VERSION ""

NS_ :

BS_:

BU_: FR C3B

BO_ 273 FR_111: 64 FR
 SG_ FR_CRCCheck_111 : 503|16@0+ (1,0) [0|65535] ""  C3B
 SG_ FR_RollingCounter_111 : 491|4@0+ (1,0) [0|15] ""  C3B
 SG_ FR_Obj1_Ax : 303|10@0+ (0.03125,-16) [-16|15.96875] "m/s2"  C3B
 SG_ FR_Obj1_Ay : 280|9@0+ (0.0625,-16) [-16|15.9375] "m/s2"  C3B
 SG_ FR_Obj1_Vx : 276|12@0+ (0.0625,-128) [-128|127.9375] "m/s"  C3B
 SG_ FR_Obj1_Vy : 270|10@0+ (0.0625,-32) [-32|31.9375] "m/s"  C3B
 SG_ FR_Obj1_DelayTime : 254|16@0+ (1,0) [0|65535] "ms"  C3B
 SG_ FR_Obj1_ReferPoint_Dx : 237|4@0+ (1,0) [0|15] "m"  C3B
 SG_ FR_Obj1_HeightGround : 223|9@0+ (0.1,0) [0|51.1] "m"  C3B
 SG_ FR_Obj1_MotionStatusConf : 213|6@0+ (2,0) [0|63] "-"  C3B
 SG_ FR_Obj1_MotionStatus : 200|3@0+ (1,0) [0|7] ""  C3B
 SG_ FR_Obj1_Measured : 202|2@0+ (1,0) [0|3] ""  C3B
 SG_ FR_Obj1_valid : 203|1@0+ (1,0) [0|1] ""  C3B
 SG_ FR_Obj1_Track_Age : 187|16@0+ (1,0) [0|65535] ""  C3B
 SG_ FR_Obj1_Track_ID : 171|16@0+ (1,0) [0|65535] ""  C3B
 SG_ FR_Obj1_ObstacleProb : 161|6@0+ (2,0) [0|100] "%"  C3B
 SG_ FR_Obj1_ExistProb : 167|6@0+ (2,0) [0|100] "%"  C3B
 SG_ FR_Obj1_RelAx : 145|10@0+ (0.03125,-16) [-16|15.96875] "m/s2"  C3B
 SG_ FR_Obj1_RelAy : 138|9@0+ (0.0625,-16) [-16|15.9375] "m/s2"  C3B
 SG_ FR_Obj1_RelVx_std : 134|12@0+ (0.0625,0) [0|255.9375] "m/s"  C3B
 SG_ FR_Obj1_RelVx : 114|12@0+ (0.0625,-128) [-128|127.9375] "m/s"  C3B
 SG_ FR_Obj1_RelVy_std : 108|10@0+ (0.125,0) [0|127.875] "m/s"  C3B
 SG_ FR_Obj1_RelVy : 102|10@0+ (0.0625,-32) [-32|31.9375] "m/s"  C3B
 SG_ FR_Obj1_Dx_Vnce : 84|14@0+ (0.05,0) [0|50] "m2"  C3B
 SG_ FR_Obj1_Dx : 65|13@0+ (0.0625,-100) [-100|411.9375] "m"  C3B
 SG_ FR_Obj1_Dy_Vnce : 59|10@0+ (0.02,0) [0|20] "m2"  C3B
 SG_ FR_Obj1_Dy : 54|11@0+ (0.125,-128) [-128|127.875] "m"  C3B
 SG_ FR_Obj1_HeadingAngle : 32|10@0+ (0.01,-3.14) [-3.14|3.14] "rad"  C3B
 SG_ FR_Obj1_Length : 25|9@0+ (0.05,0) [0|25.5] "m"  C3B
 SG_ FR_Obj1_Height : 18|9@0+ (0.01,0) [0|5.11] "m"  C3B
 SG_ FR_Obj1_Width : 12|10@0+ (0.01,0) [0|10.23] "m"  C3B
 SG_ FR_Obj1_TypeProb : 2|6@0+ (2,0) [0|100] "%"  C3B
 SG_ FR_Obj1_Type : 6|4@0+ (1,0) [0|15] ""  C3B

BO_ 274 FR_112: 64 FR
 SG_ FR_CRCCheck_112 : 503|16@0+ (1,0) [0|65535] ""  C3B
 SG_ FR_RollingCounter_112 : 491|4@0+ (1,0) [0|15] ""  C3B
 SG_ FR_Obj2_Ax : 303|10@0+ (0.03125,-16) [-16|15.96875] "m/s2"  C3B
 SG_ FR_Obj2_Ay : 280|9@0+ (0.0625,-16) [-16|15.9375] "m/s2"  C3B
 SG_ FR_Obj2_Vx : 276|12@0+ (0.0625,-128) [-128|127.9375] "m/s"  C3B
 SG_ FR_Obj2_Vy : 270|10@0+ (0.0625,-32) [-32|31.9375] "m/s"  C3B
 SG_ FR_Obj2_DelayTime : 254|16@0+ (1,0) [0|65535] "ms"  C3B
 SG_ FR_Obj2_ReferPoint_Dx : 237|4@0+ (1,0) [0|15] "m"  C3B
 SG_ FR_Obj2_HeightGround : 223|9@0+ (0.1,0) [0|51.1] "m"  C3B
 SG_ FR_Obj2_MotionStatusConf : 213|6@0+ (2,0) [0|63] "-"  C3B
 SG_ FR_Obj2_MotionStatus : 200|3@0+ (1,0) [0|7] ""  C3B
 SG_ FR_Obj2_Measured : 202|2@0+ (1,0) [0|3] ""  C3B
 SG_ FR_Obj2_valid : 203|1@0+ (1,0) [0|1] ""  C3B
 SG_ FR_Obj2_Track_Age : 187|16@0+ (1,0) [0|65535] ""  C3B
 SG_ FR_Obj2_Track_ID : 171|16@0+ (1,0) [0|65535] ""  C3B
 SG_ FR_Obj2_ObstacleProb : 161|6@0+ (2,0) [0|100] "%"  C3B
 SG_ FR_Obj2_ExistProb : 167|6@0+ (2,0) [0|100] "%"  C3B
 SG_ FR_Obj2_RelAx : 145|10@0+ (0.03125,-16) [-16|15.96875] "m/s2"  C3B
 SG_ FR_Obj2_RelAy : 138|9@0+ (0.0625,-16) [-16|15.9375] "m/s2"  C3B
 SG_ FR_Obj2_RelVx_std : 134|12@0+ (0.0625,0) [0|255.9375] "m/s"  C3B
 SG_ FR_Obj2_RelVx : 114|12@0+ (0.0625,-128) [-128|127.9375] "m/s"  C3B
 SG_ FR_Obj2_RelVy_std : 108|10@0+ (0.125,0) [0|127.875] "m/s"  C3B
 SG_ FR_Obj2_RelVy : 102|10@0+ (0.0625,-32) [-32|31.9375] "m/s"  C3B
 SG_ FR_Obj2_Dx_Vnce : 84|14@0+ (0.05,0) [0|50] "m2"  C3B
 SG_ FR_Obj2_Dx : 65|13@0+ (0.0625,-100) [-100|411.9375] "m"  C3B
 SG_ FR_Obj2_Dy_Vnce : 59|10@0+ (0.02,0) [0|20] "m2"  C3B
 SG_ FR_Obj2_Dy : 54|11@0+ (0.125,-128) [-128|127.875] "m"  C3B
 SG_ FR_Obj2_HeadingAngle : 32|10@0+ (0.01,-3.14) [-3.14|3.14] "rad"  C3B
 SG_ FR_Obj2_Length : 25|9@0+ (0.05,0) [0|25.5] "m"  C3B
 SG_ FR_Obj2_Height : 18|9@0+ (0.01,0) [0|5.11] "m"  C3B
 SG_ FR_Obj2_Width : 12|10@0+ (0.01,0) [0|10.23] "m"  C3B
 SG_ FR_Obj2_TypeProb : 2|6@0+ (2,0) [0|100] "%"  C3B
 SG_ FR_Obj2_Type : 6|4@0+ (1,0) [0|15] ""  C3B

BO_ 275 FR_113: 64 FR
 SG_ FR_CRCCheck_113 : 503|16@0+ (1,0) [0|65535] ""  C3B
 SG_ FR_RollingCounter_113 : 491|4@0+ (1,0) [0|15] ""  C3B
 SG_ FR_Obj3_Ax : 303|10@0+ (0.03125,-16) [-16|15.96875] "m/s2"  C3B
 SG_ FR_Obj3_Ay : 280|9@0+ (0.0625,-16) [-16|15.9375] "m/s2"  C3B
 SG_ FR_Obj3_Vx : 276|12@0+ (0.0625,-128) [-128|127.9375] "m/s"  C3B
 SG_ FR_Obj3_Vy : 270|10@0+ (0.0625,-32) [-32|31.9375] "m/s"  C3B
 SG_ FR_Obj3_DelayTime : 254|16@0+ (1,0) [0|65535] "ms"  C3B
 SG_ FR_Obj3_ReferPoint_Dx : 237|4@0+ (1,0) [0|15] "m"  C3B
 SG_ FR_Obj3_HeightGround : 223|9@0+ (0.1,0) [0|51.1] "m"  C3B
 SG_ FR_Obj3_MotionStatusConf : 213|6@0+ (2,0) [0|63] "-"  C3B
 SG_ FR_Obj3_MotionStatus : 200|3@0+ (1,0) [0|7] ""  C3B
 SG_ FR_Obj3_Measured : 202|2@0+ (1,0) [0|3] ""  C3B
 SG_ FR_Obj3_valid : 203|1@0+ (1,0) [0|1] ""  C3B
 SG_ FR_Obj3_Track_Age : 187|16@0+ (1,0) [0|65535] ""  C3B
 SG_ FR_Obj3_Track_ID : 171|16@0+ (1,0) [0|65535] ""  C3B
 SG_ FR_Obj3_ObstacleProb : 161|6@0+ (2,0) [0|100] "%"  C3B
 SG_ FR_Obj3_ExistProb : 167|6@0+ (2,0) [0|100] "%"  C3B
 SG_ FR_Obj3_RelAx : 145|10@0+ (0.03125,-16) [-16|15.96875] "m/s2"  C3B
 SG_ FR_Obj3_RelAy : 138|9@0+ (0.0625,-16) [-16|15.9375] "m/s2"  C3B
 SG_ FR_Obj3_RelVx_std : 134|12@0+ (0.0625,0) [0|255.9375] "m/s"  C3B
 SG_ FR_Obj3_RelVx : 114|12@0+ (0.0625,-128) [-128|127.9375] "m/s"  C3B
 SG_ FR_Obj3_RelVy_std : 108|10@0+ (0.125,0) [0|127.875] "m/s"  C3B
 SG_ FR_Obj3_RelVy : 102|10@0+ (0.0625,-32) [-32|31.9375] "m/s"  C3B
 SG_ FR_Obj3_Dx_Vnce : 84|14@0+ (0.05,0) [0|50] "m2"  C3B
 SG_ FR_Obj3_Dx : 65|13@0+ (0.0625,-100) [-100|411.9375] "m"  C3B
 SG_ FR_Obj3_Dy_Vnce : 59|10@0+ (0.02,0) [0|20] "m2"  C3B
 SG_ FR_Obj3_Dy : 54|11@0+ (0.125,-128) [-128|127.875] "m"  C3B
 SG_ FR_Obj3_HeadingAngle : 32|10@0+ (0.01,-3.14) [-3.14|3.14] "rad"  C3B
 SG_ FR_Obj3_Length : 25|9@0+ (0.05,0) [0|25.5] "m"  C3B
 SG_ FR_Obj3_Height : 18|9@0+ (0.01,0) [0|5.11] "m"  C3B
 SG_ FR_Obj3_Width : 12|10@0+ (0.01,0) [0|10.23] "m"  C3B
 SG_ FR_Obj3_TypeProb : 2|6@0+ (2,0) [0|100] "%"  C3B
 SG_ FR_Obj3_Type : 6|4@0+ (1,0) [0|15] ""  C3B

BO_ 276 FR_114: 64 FR
 SG_ FR_CRCCheck_114 : 503|16@0+ (1,0) [0|65535] ""  C3B
 SG_ FR_RollingCounter_114 : 491|4@0+ (1,0) [0|15] ""  C3B
 SG_ FR_Obj4_Ax : 303|10@0+ (0.03125,-16) [-16|15.96875] "m/s2"  C3B
 SG_ FR_Obj4_Ay : 280|9@0+ (0.0625,-16) [-16|15.9375] "m/s2"  C3B
 SG_ FR_Obj4_Vx : 276|12@0+ (0.0625,-128) [-128|127.9375] "m/s"  C3B
 SG_ FR_Obj4_Vy : 270|10@0+ (0.0625,-32) [-32|31.9375] "m/s"  C3B
 SG_ FR_Obj4_DelayTime : 254|16@0+ (1,0) [0|65535] "ms"  C3B
 SG_ FR_Obj4_ReferPoint_Dx : 237|4@0+ (1,0) [0|15] "m"  C3B
 SG_ FR_Obj4_HeightGround : 223|9@0+ (0.1,0) [0|51.1] "m"  C3B
 SG_ FR_Obj4_MotionStatusConf : 213|6@0+ (2,0) [0|63] "-"  C3B
 SG_ FR_Obj4_MotionStatus : 200|3@0+ (1,0) [0|7] ""  C3B
 SG_ FR_Obj4_Measured : 202|2@0+ (1,0) [0|3] ""  C3B
 SG_ FR_Obj4_valid : 203|1@0+ (1,0) [0|1] ""  C3B
 SG_ FR_Obj4_Track_Age : 187|16@0+ (1,0) [0|65535] ""  C3B
 SG_ FR_Obj4_Track_ID : 171|16@0+ (1,0) [0|65535] ""  C3B
 SG_ FR_Obj4_ObstacleProb : 161|6@0+ (2,0) [0|100] "%"  C3B
 SG_ FR_Obj4_ExistProb : 167|6@0+ (2,0) [0|100] "%"  C3B
 SG_ FR_Obj4_RelAx : 145|10@0+ (0.03125,-16) [-16|15.96875] "m/s2"  C3B
 SG_ FR_Obj4_RelAy : 138|9@0+ (0.0625,-16) [-16|15.9375] "m/s2"  C3B
 SG_ FR_Obj4_RelVx_std : 134|12@0+ (0.0625,0) [0|255.9375] "m/s"  C3B
 SG_ FR_Obj4_RelVx : 114|12@0+ (0.0625,-128) [-128|127.9375] "m/s"  C3B
 SG_ FR_Obj4_RelVy_std : 108|10@0+ (0.125,0) [0|127.875] "m/s"  C3B
 SG_ FR_Obj4_RelVy : 102|10@0+ (0.0625,-32) [-32|31.9375] "m/s"  C3B
 SG_ FR_Obj4_Dx_Vnce : 84|14@0+ (0.05,0) [0|50] "m2"  C3B
 SG_ FR_Obj4_Dx : 65|13@0+ (0.0625,-100) [-100|411.9375] "m"  C3B
 SG_ FR_Obj4_Dy_Vnce : 59|10@0+ (0.02,0) [0|20] "m2"  C3B
 SG_ FR_Obj4_Dy : 54|11@0+ (0.125,-128) [-128|127.875] "m"  C3B
 SG_ FR_Obj4_HeadingAngle : 32|10@0+ (0.01,-3.14) [-3.14|3.14] "rad"  C3B
 SG_ FR_Obj4_Length : 25|9@0+ (0.05,0) [0|25.5] "m"  C3B
 SG_ FR_Obj4_Height : 18|9@0+ (0.01,0) [0|5.11] "m"  C3B
 SG_ FR_Obj4_Width : 12|10@0+ (0.01,0) [0|10.23] "m"  C3B
 SG_ FR_Obj4_TypeProb : 2|6@0+ (2,0) [0|100] "%"  C3B
 SG_ FR_Obj4_Type : 6|4@0+ (1,0) [0|15] ""  C3B

BO_ 277 FR_115: 64 FR
 SG_ FR_CRCCheck_115 : 503|16@0+ (1,0) [0|65535] ""  C3B
 SG_ FR_RollingCounter_115 : 491|4@0+ (1,0) [0|15] ""  C3B
 SG_ FR_Obj5_Ax : 303|10@0+ (0.03125,-16) [-16|15.96875] "m/s2"  C3B
 SG_ FR_Obj5_Ay : 280|9@0+ (0.0625,-16) [-16|15.9375] "m/s2"  C3B
 SG_ FR_Obj5_Vx : 276|12@0+ (0.0625,-128) [-128|127.9375] "m/s"  C3B
 SG_ FR_Obj5_Vy : 270|10@0+ (0.0625,-32) [-32|31.9375] "m/s"  C3B
 SG_ FR_Obj5_DelayTime : 254|16@0+ (1,0) [0|65535] "ms"  C3B
 SG_ FR_Obj5_ReferPoint_Dx : 237|4@0+ (1,0) [0|15] "m"  C3B
 SG_ FR_Obj5_HeightGround : 223|9@0+ (0.1,0) [0|51.1] "m"  C3B
 SG_ FR_Obj5_MotionStatusConf : 213|6@0+ (2,0) [0|63] "-"  C3B
 SG_ FR_Obj5_MotionStatus : 200|3@0+ (1,0) [0|7] ""  C3B
 SG_ FR_Obj5_Measured : 202|2@0+ (1,0) [0|3] ""  C3B
 SG_ FR_Obj5_valid : 203|1@0+ (1,0) [0|1] ""  C3B
 SG_ FR_Obj5_Track_Age : 187|16@0+ (1,0) [0|65535] ""  C3B
 SG_ FR_Obj5_Track_ID : 171|16@0+ (1,0) [0|65535] ""  C3B
 SG_ FR_Obj5_ObstacleProb : 161|6@0+ (2,0) [0|100] "%"  C3B
 SG_ FR_Obj5_ExistProb : 167|6@0+ (2,0) [0|100] "%"  C3B
 SG_ FR_Obj5_RelAx : 145|10@0+ (0.03125,-16) [-16|15.96875] "m/s2"  C3B
 SG_ FR_Obj5_RelAy : 138|9@0+ (0.0625,-16) [-16|15.9375] "m/s2"  C3B
 SG_ FR_Obj5_RelVx_std : 134|12@0+ (0.0625,0) [0|255.9375] "m/s"  C3B
 SG_ FR_Obj5_RelVx : 114|12@0+ (0.0625,-128) [-128|127.9375] "m/s"  C3B
 SG_ FR_Obj5_RelVy_std : 108|10@0+ (0.125,0) [0|127.875] "m/s"  C3B
 SG_ FR_Obj5_RelVy : 102|10@0+ (0.0625,-32) [-32|31.9375] "m/s"  C3B
 SG_ FR_Obj5_Dx_Vnce : 84|14@0+ (0.05,0) [0|50] "m2"  C3B
 SG_ FR_Obj5_Dx : 65|13@0+ (0.0625,-100) [-100|411.9375] "m"  C3B
 SG_ FR_Obj5_Dy_Vnce : 59|10@0+ (0.02,0) [0|20] "m2"  C3B
 SG_ FR_Obj5_Dy : 54|11@0+ (0.125,-128) [-128|127.875] "m"  C3B
 SG_ FR_Obj5_HeadingAngle : 32|10@0+ (0.01,-3.14) [-3.14|3.14] "rad"  C3B
 SG_ FR_Obj5_Length : 25|9@0+ (0.05,0) [0|25.5] "m"  C3B
 SG_ FR_Obj5_Height : 18|9@0+ (0.01,0) [0|5.11] "m"  C3B
 SG_ FR_Obj5_Width : 12|10@0+ (0.01,0) [0|10.23] "m"  C3B
 SG_ FR_Obj5_TypeProb : 2|6@0+ (2,0) [0|100] "%"  C3B
 SG_ FR_Obj5_Type : 6|4@0+ (1,0) [0|15] ""  C3B

BO_ 278 FR_116: 64 FR
 SG_ FR_CRCCheck_116 : 503|16@0+ (1,0) [0|65535] ""  C3B
 SG_ FR_RollingCounter_116 : 491|4@0+ (1,0) [0|15] ""  C3B
 SG_ FR_Obj6_Ax : 303|10@0+ (0.03125,-16) [-16|15.96875] "m/s2"  C3B
 SG_ FR_Obj6_Ay : 280|9@0+ (0.0625,-16) [-16|15.9375] "m/s2"  C3B
 SG_ FR_Obj6_Vx : 276|12@0+ (0.0625,-128) [-128|127.9375] "m/s"  C3B
 SG_ FR_Obj6_Vy : 270|10@0+ (0.0625,-32) [-32|31.9375] "m/s"  C3B
 SG_ FR_Obj6_DelayTime : 254|16@0+ (1,0) [0|65535] "ms"  C3B
 SG_ FR_Obj6_ReferPoint_Dx : 237|4@0+ (1,0) [0|15] "m"  C3B
 SG_ FR_Obj6_HeightGround : 223|9@0+ (0.1,0) [0|51.1] "m"  C3B
 SG_ FR_Obj6_MotionStatusConf : 213|6@0+ (2,0) [0|63] "-"  C3B
 SG_ FR_Obj6_MotionStatus : 200|3@0+ (1,0) [0|7] ""  C3B
 SG_ FR_Obj6_Measured : 202|2@0+ (1,0) [0|3] ""  C3B
 SG_ FR_Obj6_valid : 203|1@0+ (1,0) [0|1] ""  C3B
 SG_ FR_Obj6_Track_Age : 187|16@0+ (1,0) [0|65535] ""  C3B
 SG_ FR_Obj6_Track_ID : 171|16@0+ (1,0) [0|65535] ""  C3B
 SG_ FR_Obj6_ObstacleProb : 161|6@0+ (2,0) [0|100] "%"  C3B
 SG_ FR_Obj6_ExistProb : 167|6@0+ (2,0) [0|100] "%"  C3B
 SG_ FR_Obj6_RelAx : 145|10@0+ (0.03125,-16) [-16|15.96875] "m/s2"  C3B
 SG_ FR_Obj6_RelAy : 138|9@0+ (0.0625,-16) [-16|15.9375] "m/s2"  C3B
 SG_ FR_Obj6_RelVx_std : 134|12@0+ (0.0625,0) [0|255.9375] "m/s"  C3B
 SG_ FR_Obj6_RelVx : 114|12@0+ (0.0625,-128) [-128|127.9375] "m/s"  C3B
 SG_ FR_Obj6_RelVy_std : 108|10@0+ (0.125,0) [0|127.875] "m/s"  C3B
 SG_ FR_Obj6_RelVy : 102|10@0+ (0.0625,-32) [-32|31.9375] "m/s"  C3B
 SG_ FR_Obj6_Dx_Vnce : 84|14@0+ (0.05,0) [0|50] "m2"  C3B
 SG_ FR_Obj6_Dx : 65|13@0+ (0.0625,-100) [-100|411.9375] "m"  C3B
 SG_ FR_Obj6_Dy_Vnce : 59|10@0+ (0.02,0) [0|20] "m2"  C3B
 SG_ FR_Obj6_Dy : 54|11@0+ (0.125,-128) [-128|127.875] "m"  C3B
 SG_ FR_Obj6_HeadingAngle : 32|10@0+ (0.01,-3.14) [-3.14|3.14] "rad"  C3B
 SG_ FR_Obj6_Length : 25|9@0+ (0.05,0) [0|25.5] "m"  C3B
 SG_ FR_Obj6_Height : 18|9@0+ (0.01,0) [0|5.11] "m"  C3B
 SG_ FR_Obj6_Width : 12|10@0+ (0.01,0) [0|10.23] "m"  C3B
 SG_ FR_Obj6_TypeProb : 2|6@0+ (2,0) [0|100] "%"  C3B
 SG_ FR_Obj6_Type : 6|4@0+ (1,0) [0|15] ""  C3B

BO_ 279 FR_117: 64 FR
 SG_ FR_CRCCheck_117 : 503|16@0+ (1,0) [0|65535] ""  C3B
 SG_ FR_RollingCounter_117 : 491|4@0+ (1,0) [0|15] ""  C3B
 SG_ FR_Obj7_Ax : 303|10@0+ (0.03125,-16) [-16|15.96875] "m/s2"  C3B
 SG_ FR_Obj7_Ay : 280|9@0+ (0.0625,-16) [-16|15.9375] "m/s2"  C3B
 SG_ FR_Obj7_Vx : 276|12@0+ (0.0625,-128) [-128|127.9375] "m/s"  C3B
 SG_ FR_Obj7_Vy : 270|10@0+ (0.0625,-32) [-32|31.9375] "m/s"  C3B
 SG_ FR_Obj7_DelayTime : 254|16@0+ (1,0) [0|65535] "ms"  C3B
 SG_ FR_Obj7_ReferPoint_Dx : 237|4@0+ (1,0) [0|15] "m"  C3B
 SG_ FR_Obj7_HeightGround : 223|9@0+ (0.1,0) [0|51.1] "m"  C3B
 SG_ FR_Obj7_MotionStatusConf : 213|6@0+ (2,0) [0|63] "-"  C3B
 SG_ FR_Obj7_MotionStatus : 200|3@0+ (1,0) [0|7] ""  C3B
 SG_ FR_Obj7_Measured : 202|2@0+ (1,0) [0|3] ""  C3B
 SG_ FR_Obj7_valid : 203|1@0+ (1,0) [0|1] ""  C3B
 SG_ FR_Obj7_Track_Age : 187|16@0+ (1,0) [0|65535] ""  C3B
 SG_ FR_Obj7_Track_ID : 171|16@0+ (1,0) [0|65535] ""  C3B
 SG_ FR_Obj7_ObstacleProb : 161|6@0+ (2,0) [0|100] "%"  C3B
 SG_ FR_Obj7_ExistProb : 167|6@0+ (2,0) [0|100] "%"  C3B
 SG_ FR_Obj7_RelAx : 145|10@0+ (0.03125,-16) [-16|15.96875] "m/s2"  C3B
 SG_ FR_Obj7_RelAy : 138|9@0+ (0.0625,-16) [-16|15.9375] "m/s2"  C3B
 SG_ FR_Obj7_RelVx_std : 134|12@0+ (0.0625,0) [0|255.9375] "m/s"  C3B
 SG_ FR_Obj7_RelVx : 114|12@0+ (0.0625,-128) [-128|127.9375] "m/s"  C3B
 SG_ FR_Obj7_RelVy_std : 108|10@0+ (0.125,0) [0|127.875] "m/s"  C3B
 SG_ FR_Obj7_RelVy : 102|10@0+ (0.0625,-32) [-32|31.9375] "m/s"  C3B
 SG_ FR_Obj7_Dx_Vnce : 84|14@0+ (0.05,0) [0|50] "m2"  C3B
 SG_ FR_Obj7_Dx : 65|13@0+ (0.0625,-100) [-100|411.9375] "m"  C3B
 SG_ FR_Obj7_Dy_Vnce : 59|10@0+ (0.02,0) [0|20] "m2"  C3B
 SG_ FR_Obj7_Dy : 54|11@0+ (0.125,-128) [-128|127.875] "m"  C3B
 SG_ FR_Obj7_HeadingAngle : 32|10@0+ (0.01,-3.14) [-3.14|3.14] "rad"  C3B
 SG_ FR_Obj7_Length : 25|9@0+ (0.05,0) [0|25.5] "m"  C3B
 SG_ FR_Obj7_Height : 18|9@0+ (0.01,0) [0|5.11] "m"  C3B
 SG_ FR_Obj7_Width : 12|10@0+ (0.01,0) [0|10.23] "m"  C3B
 SG_ FR_Obj7_TypeProb : 2|6@0+ (2,0) [0|100] "%"  C3B
 SG_ FR_Obj7_Type : 6|4@0+ (1,0) [0|15] ""  C3B

BO_ 280 FR_118: 64 FR
 SG_ FR_CRCCheck_118 : 503|16@0+ (1,0) [0|65535] ""  C3B
 SG_ FR_RollingCounter_118 : 491|4@0+ (1,0) [0|15] ""  C3B
 SG_ FR_Obj8_Ax : 303|10@0+ (0.03125,-16) [-16|15.96875] "m/s2"  C3B
 SG_ FR_Obj8_Ay : 280|9@0+ (0.0625,-16) [-16|15.9375] "m/s2"  C3B
 SG_ FR_Obj8_Vx : 276|12@0+ (0.0625,-128) [-128|127.9375] "m/s"  C3B
 SG_ FR_Obj8_Vy : 270|10@0+ (0.0625,-32) [-32|31.9375] "m/s"  C3B
 SG_ FR_Obj8_DelayTime : 254|16@0+ (1,0) [0|65535] "ms"  C3B
 SG_ FR_Obj8_ReferPoint_Dx : 237|4@0+ (1,0) [0|15] "m"  C3B
 SG_ FR_Obj8_HeightGround : 223|9@0+ (0.1,0) [0|51.1] "m"  C3B
 SG_ FR_Obj8_MotionStatusConf : 213|6@0+ (2,0) [0|63] "-"  C3B
 SG_ FR_Obj8_MotionStatus : 200|3@0+ (1,0) [0|7] ""  C3B
 SG_ FR_Obj8_Measured : 202|2@0+ (1,0) [0|3] ""  C3B
 SG_ FR_Obj8_valid : 203|1@0+ (1,0) [0|1] ""  C3B
 SG_ FR_Obj8_Track_Age : 187|16@0+ (1,0) [0|65535] ""  C3B
 SG_ FR_Obj8_Track_ID : 171|16@0+ (1,0) [0|65535] ""  C3B
 SG_ FR_Obj8_ObstacleProb : 161|6@0+ (2,0) [0|100] "%"  C3B
 SG_ FR_Obj8_ExistProb : 167|6@0+ (2,0) [0|100] "%"  C3B
 SG_ FR_Obj8_RelAx : 145|10@0+ (0.03125,-16) [-16|15.96875] "m/s2"  C3B
 SG_ FR_Obj8_RelAy : 138|9@0+ (0.0625,-16) [-16|15.9375] "m/s2"  C3B
 SG_ FR_Obj8_RelVx_std : 134|12@0+ (0.0625,0) [0|255.9375] "m/s"  C3B
 SG_ FR_Obj8_RelVx : 114|12@0+ (0.0625,-128) [-128|127.9375] "m/s"  C3B
 SG_ FR_Obj8_RelVy_std : 108|10@0+ (0.125,0) [0|127.875] "m/s"  C3B
 SG_ FR_Obj8_RelVy : 102|10@0+ (0.0625,-32) [-32|31.9375] "m/s"  C3B
 SG_ FR_Obj8_Dx_Vnce : 84|14@0+ (0.05,0) [0|50] "m2"  C3B
 SG_ FR_Obj8_Dx : 65|13@0+ (0.0625,-100) [-100|411.9375] "m"  C3B
 SG_ FR_Obj8_Dy_Vnce : 59|10@0+ (0.02,0) [0|20] "m2"  C3B
 SG_ FR_Obj8_Dy : 54|11@0+ (0.125,-128) [-128|127.875] "m"  C3B
 SG_ FR_Obj8_HeadingAngle : 32|10@0+ (0.01,-3.14) [-3.14|3.14] "rad"  C3B
 SG_ FR_Obj8_Length : 25|9@0+ (0.05,0) [0|25.5] "m"  C3B
 SG_ FR_Obj8_Height : 18|9@0+ (0.01,0) [0|5.11] "m"  C3B
 SG_ FR_Obj8_Width : 12|10@0+ (0.01,0) [0|10.23] "m"  C3B
 SG_ FR_Obj8_TypeProb : 2|6@0+ (2,0) [0|100] "%"  C3B
 SG_ FR_Obj8_Type : 6|4@0+ (1,0) [0|15] ""  C3B

BO_ 281 FR_119: 64 FR
 SG_ FR_CRCCheck_119 : 503|16@0+ (1,0) [0|65535] ""  C3B
 SG_ FR_RollingCounter_119 : 491|4@0+ (1,0) [0|15] ""  C3B
 SG_ FR_Obj9_Ax : 303|10@0+ (0.03125,-16) [-16|15.96875] "m/s2"  C3B
 SG_ FR_Obj9_Ay : 280|9@0+ (0.0625,-16) [-16|15.9375] "m/s2"  C3B
 SG_ FR_Obj9_Vx : 276|12@0+ (0.0625,-128) [-128|127.9375] "m/s"  C3B
 SG_ FR_Obj9_Vy : 270|10@0+ (0.0625,-32) [-32|31.9375] "m/s"  C3B
 SG_ FR_Obj9_DelayTime : 254|16@0+ (1,0) [0|65535] "ms"  C3B
 SG_ FR_Obj9_ReferPoint_Dx : 237|4@0+ (1,0) [0|15] "m"  C3B
 SG_ FR_Obj9_HeightGround : 223|9@0+ (0.1,0) [0|51.1] "m"  C3B
 SG_ FR_Obj9_MotionStatusConf : 213|6@0+ (2,0) [0|63] "-"  C3B
 SG_ FR_Obj9_MotionStatus : 200|3@0+ (1,0) [0|7] ""  C3B
 SG_ FR_Obj9_Measured : 202|2@0+ (1,0) [0|3] ""  C3B
 SG_ FR_Obj9_valid : 203|1@0+ (1,0) [0|1] ""  C3B
 SG_ FR_Obj9_Track_Age : 187|16@0+ (1,0) [0|65535] ""  C3B
 SG_ FR_Obj9_Track_ID : 171|16@0+ (1,0) [0|65535] ""  C3B
 SG_ FR_Obj9_ObstacleProb : 161|6@0+ (2,0) [0|100] "%"  C3B
 SG_ FR_Obj9_ExistProb : 167|6@0+ (2,0) [0|100] "%"  C3B
 SG_ FR_Obj9_RelAx : 145|10@0+ (0.03125,-16) [-16|15.96875] "m/s2"  C3B
 SG_ FR_Obj9_RelAy : 138|9@0+ (0.0625,-16) [-16|15.9375] "m/s2"  C3B
 SG_ FR_Obj9_RelVx_std : 134|12@0+ (0.0625,0) [0|255.9375] "m/s"  C3B
 SG_ FR_Obj9_RelVx : 114|12@0+ (0.0625,-128) [-128|127.9375] "m/s"  C3B
 SG_ FR_Obj9_RelVy_std : 108|10@0+ (0.125,0) [0|127.875] "m/s"  C3B
 SG_ FR_Obj9_RelVy : 102|10@0+ (0.0625,-32) [-32|31.9375] "m/s"  C3B
 SG_ FR_Obj9_Dx_Vnce : 84|14@0+ (0.05,0) [0|50] "m2"  C3B
 SG_ FR_Obj9_Dx : 65|13@0+ (0.0625,-100) [-100|411.9375] "m"  C3B
 SG_ FR_Obj9_Dy_Vnce : 59|10@0+ (0.02,0) [0|20] "m2"  C3B
 SG_ FR_Obj9_Dy : 54|11@0+ (0.125,-128) [-128|127.875] "m"  C3B
 SG_ FR_Obj9_HeadingAngle : 32|10@0+ (0.01,-3.14) [-3.14|3.14] "rad"  C3B
 SG_ FR_Obj9_Length : 25|9@0+ (0.05,0) [0|25.5] "m"  C3B
 SG_ FR_Obj9_Height : 18|9@0+ (0.01,0) [0|5.11] "m"  C3B
 SG_ FR_Obj9_Width : 12|10@0+ (0.01,0) [0|10.23] "m"  C3B
 SG_ FR_Obj9_TypeProb : 2|6@0+ (2,0) [0|100] "%"  C3B
 SG_ FR_Obj9_Type : 6|4@0+ (1,0) [0|15] ""  C3B

BO_ 288 FR_120: 64 FR
 SG_ FR_CRCCheck_120 : 503|16@0+ (1,0) [0|65535] ""  C3B
 SG_ FR_RollingCounter_120 : 491|4@0+ (1,0) [0|15] ""  C3B
 SG_ FR_Obj10_Ax : 303|10@0+ (0.03125,-16) [-16|15.96875] "m/s2"  C3B
 SG_ FR_Obj10_Ay : 280|9@0+ (0.0625,-16) [-16|15.9375] "m/s2"  C3B
 SG_ FR_Obj10_Vx : 276|12@0+ (0.0625,-128) [-128|127.9375] "m/s"  C3B
 SG_ FR_Obj10_Vy : 270|10@0+ (0.0625,-32) [-32|31.9375] "m/s"  C3B
 SG_ FR_Obj10_DelayTime : 254|16@0+ (1,0) [0|65535] "ms"  C3B
 SG_ FR_Obj10_ReferPoint_Dx : 237|4@0+ (1,0) [0|15] "m"  C3B
 SG_ FR_Obj10_HeightGround : 223|9@0+ (0.1,0) [0|51.1] "m"  C3B
 SG_ FR_Obj10_MotionStatusConf : 213|6@0+ (2,0) [0|63] "-"  C3B
 SG_ FR_Obj10_MotionStatus : 200|3@0+ (1,0) [0|7] ""  C3B
 SG_ FR_Obj10_Measured : 202|2@0+ (1,0) [0|3] ""  C3B
 SG_ FR_Obj10_valid : 203|1@0+ (1,0) [0|1] ""  C3B
 SG_ FR_Obj10_Track_Age : 187|16@0+ (1,0) [0|65535] ""  C3B
 SG_ FR_Obj10_Track_ID : 171|16@0+ (1,0) [0|65535] ""  C3B
 SG_ FR_Obj10_ObstacleProb : 161|6@0+ (2,0) [0|100] "%"  C3B
 SG_ FR_Obj10_ExistProb : 167|6@0+ (2,0) [0|100] "%"  C3B
 SG_ FR_Obj10_RelAx : 145|10@0+ (0.03125,-16) [-16|15.96875] "m/s2"  C3B
 SG_ FR_Obj10_RelAy : 138|9@0+ (0.0625,-16) [-16|15.9375] "m/s2"  C3B
 SG_ FR_Obj10_RelVx_std : 134|12@0+ (0.0625,0) [0|255.9375] "m/s"  C3B
 SG_ FR_Obj10_RelVx : 114|12@0+ (0.0625,-128) [-128|127.9375] "m/s"  C3B
 SG_ FR_Obj10_RelVy_std : 108|10@0+ (0.125,0) [0|127.875] "m/s"  C3B
 SG_ FR_Obj10_RelVy : 102|10@0+ (0.0625,-32) [-32|31.9375] "m/s"  C3B
 SG_ FR_Obj10_Dx_Vnce : 84|14@0+ (0.05,0) [0|50] "m2"  C3B
 SG_ FR_Obj10_Dx : 65|13@0+ (0.0625,-100) [-100|411.9375] "m"  C3B
 SG_ FR_Obj10_Dy_Vnce : 59|10@0+ (0.02,0) [0|20] "m2"  C3B
 SG_ FR_Obj10_Dy : 54|11@0+ (0.125,-128) [-128|127.875] "m"  C3B
 SG_ FR_Obj10_HeadingAngle : 32|10@0+ (0.01,-3.14) [-3.14|3.14] "rad"  C3B
 SG_ FR_Obj10_Length : 25|9@0+ (0.05,0) [0|25.5] "m"  C3B
 SG_ FR_Obj10_Height : 18|9@0+ (0.01,0) [0|5.11] "m"  C3B
 SG_ FR_Obj10_Width : 12|10@0+ (0.01,0) [0|10.23] "m"  C3B
 SG_ FR_Obj10_TypeProb : 2|6@0+ (2,0) [0|100] "%"  C3B
 SG_ FR_Obj10_Type : 6|4@0+ (1,0) [0|15] ""  C3B

BO_ 289 FR_121: 64 FR
 SG_ FR_CRCCheck_121 : 503|16@0+ (1,0) [0|65535] ""  C3B
 SG_ FR_RollingCounter_121 : 491|4@0+ (1,0) [0|15] ""  C3B
 SG_ FR_Obj11_Ax : 303|10@0+ (0.03125,-16) [-16|15.96875] "m/s2"  C3B
 SG_ FR_Obj11_Ay : 280|9@0+ (0.0625,-16) [-16|15.9375] "m/s2"  C3B
 SG_ FR_Obj11_Vx : 276|12@0+ (0.0625,-128) [-128|127.9375] "m/s"  C3B
 SG_ FR_Obj11_Vy : 270|10@0+ (0.0625,-32) [-32|31.9375] "m/s"  C3B
 SG_ FR_Obj11_DelayTime : 254|16@0+ (1,0) [0|65535] "ms"  C3B
 SG_ FR_Obj11_ReferPoint_Dx : 237|4@0+ (1,0) [0|15] "m"  C3B
 SG_ FR_Obj11_HeightGround : 223|9@0+ (0.1,0) [0|51.1] "m"  C3B
 SG_ FR_Obj11_MotionStatusConf : 213|6@0+ (2,0) [0|63] "-"  C3B
 SG_ FR_Obj11_MotionStatus : 200|3@0+ (1,0) [0|7] ""  C3B
 SG_ FR_Obj11_Measured : 202|2@0+ (1,0) [0|3] ""  C3B
 SG_ FR_Obj11_valid : 203|1@0+ (1,0) [0|1] ""  C3B
 SG_ FR_Obj11_Track_Age : 187|16@0+ (1,0) [0|65535] ""  C3B
 SG_ FR_Obj11_Track_ID : 171|16@0+ (1,0) [0|65535] ""  C3B
 SG_ FR_Obj11_ObstacleProb : 161|6@0+ (2,0) [0|100] "%"  C3B
 SG_ FR_Obj11_ExistProb : 167|6@0+ (2,0) [0|100] "%"  C3B
 SG_ FR_Obj11_RelAx : 145|10@0+ (0.03125,-16) [-16|15.96875] "m/s2"  C3B
 SG_ FR_Obj11_RelAy : 138|9@0+ (0.0625,-16) [-16|15.9375] "m/s2"  C3B
 SG_ FR_Obj11_RelVx_std : 134|12@0+ (0.0625,0) [0|255.9375] "m/s"  C3B
 SG_ FR_Obj11_RelVx : 114|12@0+ (0.0625,-128) [-128|127.9375] "m/s"  C3B
 SG_ FR_Obj11_RelVy_std : 108|10@0+ (0.125,0) [0|127.875] "m/s"  C3B
 SG_ FR_Obj11_RelVy : 102|10@0+ (0.0625,-32) [-32|31.9375] "m/s"  C3B
 SG_ FR_Obj11_Dx_Vnce : 84|14@0+ (0.05,0) [0|50] "m2"  C3B
 SG_ FR_Obj11_Dx : 65|13@0+ (0.0625,-100) [-100|411.9375] "m"  C3B
 SG_ FR_Obj11_Dy_Vnce : 59|10@0+ (0.02,0) [0|20] "m2"  C3B
 SG_ FR_Obj11_Dy : 54|11@0+ (0.125,-128) [-128|127.875] "m"  C3B
 SG_ FR_Obj11_HeadingAngle : 32|10@0+ (0.01,-3.14) [-3.14|3.14] "rad"  C3B
 SG_ FR_Obj11_Length : 25|9@0+ (0.05,0) [0|25.5] "m"  C3B
 SG_ FR_Obj11_Height : 18|9@0+ (0.01,0) [0|5.11] "m"  C3B
 SG_ FR_Obj11_Width : 12|10@0+ (0.01,0) [0|10.23] "m"  C3B
 SG_ FR_Obj11_TypeProb : 2|6@0+ (2,0) [0|100] "%"  C3B
 SG_ FR_Obj11_Type : 6|4@0+ (1,0) [0|15] ""  C3B

BO_ 290 FR_122: 64 FR
 SG_ FR_CRCCheck_122 : 503|16@0+ (1,0) [0|65535] ""  C3B
 SG_ FR_RollingCounter_122 : 491|4@0+ (1,0) [0|15] ""  C3B
 SG_ FR_Obj12_Ax : 303|10@0+ (0.03125,-16) [-16|15.96875] "m/s2"  C3B
 SG_ FR_Obj12_Ay : 280|9@0+ (0.0625,-16) [-16|15.9375] "m/s2"  C3B
 SG_ FR_Obj12_Vx : 276|12@0+ (0.0625,-128) [-128|127.9375] "m/s"  C3B
 SG_ FR_Obj12_Vy : 270|10@0+ (0.0625,-32) [-32|31.9375] "m/s"  C3B
 SG_ FR_Obj12_DelayTime : 254|16@0+ (1,0) [0|65535] "ms"  C3B
 SG_ FR_Obj12_ReferPoint_Dx : 237|4@0+ (1,0) [0|15] "m"  C3B
 SG_ FR_Obj12_HeightGround : 223|9@0+ (0.1,0) [0|51.1] "m"  C3B
 SG_ FR_Obj12_MotionStatusConf : 213|6@0+ (2,0) [0|63] "-"  C3B
 SG_ FR_Obj12_MotionStatus : 200|3@0+ (1,0) [0|7] ""  C3B
 SG_ FR_Obj12_Measured : 202|2@0+ (1,0) [0|3] ""  C3B
 SG_ FR_Obj12_valid : 203|1@0+ (1,0) [0|1] ""  C3B
 SG_ FR_Obj12_Track_Age : 187|16@0+ (1,0) [0|65535] ""  C3B
 SG_ FR_Obj12_Track_ID : 171|16@0+ (1,0) [0|65535] ""  C3B
 SG_ FR_Obj12_ObstacleProb : 161|6@0+ (2,0) [0|100] "%"  C3B
 SG_ FR_Obj12_ExistProb : 167|6@0+ (2,0) [0|100] "%"  C3B
 SG_ FR_Obj12_RelAx : 145|10@0+ (0.03125,-16) [-16|15.96875] "m/s2"  C3B
 SG_ FR_Obj12_RelAy : 138|9@0+ (0.0625,-16) [-16|15.9375] "m/s2"  C3B
 SG_ FR_Obj12_RelVx_std : 134|12@0+ (0.0625,0) [0|255.9375] "m/s"  C3B
 SG_ FR_Obj12_RelVx : 114|12@0+ (0.0625,-128) [-128|127.9375] "m/s"  C3B
 SG_ FR_Obj12_RelVy_std : 108|10@0+ (0.125,0) [0|127.875] "m/s"  C3B
 SG_ FR_Obj12_RelVy : 102|10@0+ (0.0625,-32) [-32|31.9375] "m/s"  C3B
 SG_ FR_Obj12_Dx_Vnce : 84|14@0+ (0.05,0) [0|50] "m2"  C3B
 SG_ FR_Obj12_Dx : 65|13@0+ (0.0625,-100) [-100|411.9375] "m"  C3B
 SG_ FR_Obj12_Dy_Vnce : 59|10@0+ (0.02,0) [0|20] "m2"  C3B
 SG_ FR_Obj12_Dy : 54|11@0+ (0.125,-128) [-128|127.875] "m"  C3B
 SG_ FR_Obj12_HeadingAngle : 32|10@0+ (0.01,-3.14) [-3.14|3.14] "rad"  C3B
 SG_ FR_Obj12_Length : 25|9@0+ (0.05,0) [0|25.5] "m"  C3B
 SG_ FR_Obj12_Height : 18|9@0+ (0.01,0) [0|5.11] "m"  C3B
 SG_ FR_Obj12_Width : 12|10@0+ (0.01,0) [0|10.23] "m"  C3B
 SG_ FR_Obj12_TypeProb : 2|6@0+ (2,0) [0|100] "%"  C3B
 SG_ FR_Obj12_Type : 6|4@0+ (1,0) [0|15] ""  C3B

BO_ 292 FR_124: 64 FR
 SG_ FR_CRCCheck_124 : 503|16@0+ (1,0) [0|65535] ""  C3B
 SG_ FR_RollingCounter_124 : 491|4@0+ (1,0) [0|15] ""  C3B
 SG_ FR_Obj14_Ax : 303|10@0+ (0.03125,-16) [-16|15.96875] "m/s2"  C3B
 SG_ FR_Obj14_Ay : 280|9@0+ (0.0625,-16) [-16|15.9375] "m/s2"  C3B
 SG_ FR_Obj14_Vx : 276|12@0+ (0.0625,-128) [-128|127.9375] "m/s"  C3B
 SG_ FR_Obj14_Vy : 270|10@0+ (0.0625,-32) [-32|31.9375] "m/s"  C3B
 SG_ FR_Obj14_DelayTime : 254|16@0+ (1,0) [0|65535] "ms"  C3B
 SG_ FR_Obj14_ReferPoint_Dx : 237|4@0+ (1,0) [0|15] "m"  C3B
 SG_ FR_Obj14_HeightGround : 223|9@0+ (0.1,0) [0|51.1] "m"  C3B
 SG_ FR_Obj14_MotionStatusConf : 213|6@0+ (2,0) [0|63] "-"  C3B
 SG_ FR_Obj14_MotionStatus : 200|3@0+ (1,0) [0|7] ""  C3B
 SG_ FR_Obj14_Measured : 202|2@0+ (1,0) [0|3] ""  C3B
 SG_ FR_Obj14_valid : 203|1@0+ (1,0) [0|1] ""  C3B
 SG_ FR_Obj14_Track_Age : 187|16@0+ (1,0) [0|65535] ""  C3B
 SG_ FR_Obj14_Track_ID : 171|16@0+ (1,0) [0|65535] ""  C3B
 SG_ FR_Obj14_ObstacleProb : 161|6@0+ (2,0) [0|100] "%"  C3B
 SG_ FR_Obj14_ExistProb : 167|6@0+ (2,0) [0|100] "%"  C3B
 SG_ FR_Obj14_RelAx : 145|10@0+ (0.03125,-16) [-16|15.96875] "m/s2"  C3B
 SG_ FR_Obj14_RelAy : 138|9@0+ (0.0625,-16) [-16|15.9375] "m/s2"  C3B
 SG_ FR_Obj14_RelVx_std : 134|12@0+ (0.0625,0) [0|255.9375] "m/s"  C3B
 SG_ FR_Obj14_RelVx : 114|12@0+ (0.0625,-128) [-128|127.9375] "m/s"  C3B
 SG_ FR_Obj14_RelVy_std : 108|10@0+ (0.125,0) [0|127.875] "m/s"  C3B
 SG_ FR_Obj14_RelVy : 102|10@0+ (0.0625,-32) [-32|31.9375] "m/s"  C3B
 SG_ FR_Obj14_Dx_Vnce : 84|14@0+ (0.05,0) [0|50] "m2"  C3B
 SG_ FR_Obj14_Dx : 65|13@0+ (0.0625,-100) [-100|411.9375] "m"  C3B
 SG_ FR_Obj14_Dy_Vnce : 59|10@0+ (0.02,0) [0|20] "m2"  C3B
 SG_ FR_Obj14_Dy : 54|11@0+ (0.125,-128) [-128|127.875] "m"  C3B
 SG_ FR_Obj14_HeadingAngle : 32|10@0+ (0.01,-3.14) [-3.14|3.14] "rad"  C3B
 SG_ FR_Obj14_Length : 25|9@0+ (0.05,0) [0|25.5] "m"  C3B
 SG_ FR_Obj14_Height : 18|9@0+ (0.01,0) [0|5.11] "m"  C3B
 SG_ FR_Obj14_Width : 12|10@0+ (0.01,0) [0|10.23] "m"  C3B
 SG_ FR_Obj14_TypeProb : 2|6@0+ (2,0) [0|100] "%"  C3B
 SG_ FR_Obj14_Type : 6|4@0+ (1,0) [0|15] ""  C3B

BO_ 293 FR_125: 64 FR
 SG_ FR_CRCCheck_125 : 503|16@0+ (1,0) [0|65535] ""  C3B
 SG_ FR_RollingCounter_125 : 491|4@0+ (1,0) [0|15] ""  C3B
 SG_ FR_Obj15_Ax : 303|10@0+ (0.03125,-16) [-16|15.96875] "m/s2"  C3B
 SG_ FR_Obj15_Ay : 280|9@0+ (0.0625,-16) [-16|15.9375] "m/s2"  C3B
 SG_ FR_Obj15_Vx : 276|12@0+ (0.0625,-128) [-128|127.9375] "m/s"  C3B
 SG_ FR_Obj15_Vy : 270|10@0+ (0.0625,-32) [-32|31.9375] "m/s"  C3B
 SG_ FR_Obj15_DelayTime : 254|16@0+ (1,0) [0|65535] "ms"  C3B
 SG_ FR_Obj15_ReferPoint_Dx : 237|4@0+ (1,0) [0|15] "m"  C3B
 SG_ FR_Obj15_HeightGround : 223|9@0+ (0.1,0) [0|51.1] "m"  C3B
 SG_ FR_Obj15_MotionStatusConf : 213|6@0+ (2,0) [0|63] "-"  C3B
 SG_ FR_Obj15_MotionStatus : 200|3@0+ (1,0) [0|7] ""  C3B
 SG_ FR_Obj15_Measured : 202|2@0+ (1,0) [0|3] ""  C3B
 SG_ FR_Obj15_valid : 203|1@0+ (1,0) [0|1] ""  C3B
 SG_ FR_Obj15_Track_Age : 187|16@0+ (1,0) [0|65535] ""  C3B
 SG_ FR_Obj15_Track_ID : 171|16@0+ (1,0) [0|65535] ""  C3B
 SG_ FR_Obj15_ObstacleProb : 161|6@0+ (2,0) [0|100] "%"  C3B
 SG_ FR_Obj15_ExistProb : 167|6@0+ (2,0) [0|100] "%"  C3B
 SG_ FR_Obj15_RelAx : 145|10@0+ (0.03125,-16) [-16|15.96875] "m/s2"  C3B
 SG_ FR_Obj15_RelAy : 138|9@0+ (0.0625,-16) [-16|15.9375] "m/s2"  C3B
 SG_ FR_Obj15_RelVx_std : 134|12@0+ (0.0625,0) [0|255.9375] "m/s"  C3B
 SG_ FR_Obj15_RelVx : 114|12@0+ (0.0625,-128) [-128|127.9375] "m/s"  C3B
 SG_ FR_Obj15_RelVy_std : 108|10@0+ (0.125,0) [0|127.875] "m/s"  C3B
 SG_ FR_Obj15_RelVy : 102|10@0+ (0.0625,-32) [-32|31.9375] "m/s"  C3B
 SG_ FR_Obj15_Dx_Vnce : 84|14@0+ (0.05,0) [0|50] "m2"  C3B
 SG_ FR_Obj15_Dx : 65|13@0+ (0.0625,-100) [-100|411.9375] "m"  C3B
 SG_ FR_Obj15_Dy_Vnce : 59|10@0+ (0.02,0) [0|20] "m2"  C3B
 SG_ FR_Obj15_Dy : 54|11@0+ (0.125,-128) [-128|127.875] "m"  C3B
 SG_ FR_Obj15_HeadingAngle : 32|10@0+ (0.01,-3.14) [-3.14|3.14] "rad"  C3B
 SG_ FR_Obj15_Length : 25|9@0+ (0.05,0) [0|25.5] "m"  C3B
 SG_ FR_Obj15_Height : 18|9@0+ (0.01,0) [0|5.11] "m"  C3B
 SG_ FR_Obj15_Width : 12|10@0+ (0.01,0) [0|10.23] "m"  C3B
 SG_ FR_Obj15_TypeProb : 2|6@0+ (2,0) [0|100] "%"  C3B
 SG_ FR_Obj15_Type : 6|4@0+ (1,0) [0|15] ""  C3B

BO_ 294 FR_126: 64 FR
 SG_ FR_CRCCheck_126 : 503|16@0+ (1,0) [0|65535] ""  C3B
 SG_ FR_RollingCounter_126 : 491|4@0+ (1,0) [0|15] ""  C3B
 SG_ FR_Obj16_Ax : 303|10@0+ (0.03125,-16) [-16|15.96875] "m/s2"  C3B
 SG_ FR_Obj16_Ay : 280|9@0+ (0.0625,-16) [-16|15.9375] "m/s2"  C3B
 SG_ FR_Obj16_Vx : 276|12@0+ (0.0625,-128) [-128|127.9375] "m/s"  C3B
 SG_ FR_Obj16_Vy : 270|10@0+ (0.0625,-32) [-32|31.9375] "m/s"  C3B
 SG_ FR_Obj16_DelayTime : 254|16@0+ (1,0) [0|65535] "ms"  C3B
 SG_ FR_Obj16_ReferPoint_Dx : 237|4@0+ (1,0) [0|15] "m"  C3B
 SG_ FR_Obj16_HeightGround : 223|9@0+ (0.1,0) [0|51.1] "m"  C3B
 SG_ FR_Obj16_MotionStatusConf : 213|6@0+ (2,0) [0|63] "-"  C3B
 SG_ FR_Obj16_MotionStatus : 200|3@0+ (1,0) [0|7] ""  C3B
 SG_ FR_Obj16_Measured : 202|2@0+ (1,0) [0|3] ""  C3B
 SG_ FR_Obj16_valid : 203|1@0+ (1,0) [0|1] ""  C3B
 SG_ FR_Obj16_Track_Age : 187|16@0+ (1,0) [0|65535] ""  C3B
 SG_ FR_Obj16_Track_ID : 171|16@0+ (1,0) [0|65535] ""  C3B
 SG_ FR_Obj16_ObstacleProb : 161|6@0+ (2,0) [0|100] "%"  C3B
 SG_ FR_Obj16_ExistProb : 167|6@0+ (2,0) [0|100] "%"  C3B
 SG_ FR_Obj16_RelAx : 145|10@0+ (0.03125,-16) [-16|15.96875] "m/s2"  C3B
 SG_ FR_Obj16_RelAy : 138|9@0+ (0.0625,-16) [-16|15.9375] "m/s2"  C3B
 SG_ FR_Obj16_RelVx_std : 134|12@0+ (0.0625,0) [0|255.9375] "m/s"  C3B
 SG_ FR_Obj16_RelVx : 114|12@0+ (0.0625,-128) [-128|127.9375] "m/s"  C3B
 SG_ FR_Obj16_RelVy_std : 108|10@0+ (0.125,0) [0|127.875] "m/s"  C3B
 SG_ FR_Obj16_RelVy : 102|10@0+ (0.0625,-32) [-32|31.9375] "m/s"  C3B
 SG_ FR_Obj16_Dx_Vnce : 84|14@0+ (0.05,0) [0|50] "m2"  C3B
 SG_ FR_Obj16_Dx : 65|13@0+ (0.0625,-100) [-100|411.9375] "m"  C3B
 SG_ FR_Obj16_Dy_Vnce : 59|10@0+ (0.02,0) [0|20] "m2"  C3B
 SG_ FR_Obj16_Dy : 54|11@0+ (0.125,-128) [-128|127.875] "m"  C3B
 SG_ FR_Obj16_HeadingAngle : 32|10@0+ (0.01,-3.14) [-3.14|3.14] "rad"  C3B
 SG_ FR_Obj16_Length : 25|9@0+ (0.05,0) [0|25.5] "m"  C3B
 SG_ FR_Obj16_Height : 18|9@0+ (0.01,0) [0|5.11] "m"  C3B
 SG_ FR_Obj16_Width : 12|10@0+ (0.01,0) [0|10.23] "m"  C3B
 SG_ FR_Obj16_TypeProb : 2|6@0+ (2,0) [0|100] "%"  C3B
 SG_ FR_Obj16_Type : 6|4@0+ (1,0) [0|15] ""  C3B

BO_ 295 FR_127: 64 FR
 SG_ FR_CRCCheck_127 : 503|16@0+ (1,0) [0|65535] ""  C3B
 SG_ FR_RollingCounter_127 : 491|4@0+ (1,0) [0|15] ""  C3B
 SG_ FR_Obj17_Ax : 303|10@0+ (0.03125,-16) [-16|15.96875] "m/s2"  C3B
 SG_ FR_Obj17_Ay : 280|9@0+ (0.0625,-16) [-16|15.9375] "m/s2"  C3B
 SG_ FR_Obj17_Vx : 276|12@0+ (0.0625,-128) [-128|127.9375] "m/s"  C3B
 SG_ FR_Obj17_Vy : 270|10@0+ (0.0625,-32) [-32|31.9375] "m/s"  C3B
 SG_ FR_Obj17_DelayTime : 254|16@0+ (1,0) [0|65535] "ms"  C3B
 SG_ FR_Obj17_ReferPoint_Dx : 237|4@0+ (1,0) [0|15] "m"  C3B
 SG_ FR_Obj17_HeightGround : 223|9@0+ (0.1,0) [0|51.1] "m"  C3B
 SG_ FR_Obj17_MotionStatusConf : 213|6@0+ (2,0) [0|63] "-"  C3B
 SG_ FR_Obj17_MotionStatus : 200|3@0+ (1,0) [0|7] ""  C3B
 SG_ FR_Obj17_Measured : 202|2@0+ (1,0) [0|3] ""  C3B
 SG_ FR_Obj17_valid : 203|1@0+ (1,0) [0|1] ""  C3B
 SG_ FR_Obj17_Track_Age : 187|16@0+ (1,0) [0|65535] ""  C3B
 SG_ FR_Obj17_Track_ID : 171|16@0+ (1,0) [0|65535] ""  C3B
 SG_ FR_Obj17_ObstacleProb : 161|6@0+ (2,0) [0|100] "%"  C3B
 SG_ FR_Obj17_ExistProb : 167|6@0+ (2,0) [0|100] "%"  C3B
 SG_ FR_Obj17_RelAx : 145|10@0+ (0.03125,-16) [-16|15.96875] "m/s2"  C3B
 SG_ FR_Obj17_RelAy : 138|9@0+ (0.0625,-16) [-16|15.9375] "m/s2"  C3B
 SG_ FR_Obj17_RelVx_std : 134|12@0+ (0.0625,0) [0|255.9375] "m/s"  C3B
 SG_ FR_Obj17_RelVx : 114|12@0+ (0.0625,-128) [-128|127.9375] "m/s"  C3B
 SG_ FR_Obj17_RelVy_std : 108|10@0+ (0.125,0) [0|127.875] "m/s"  C3B
 SG_ FR_Obj17_RelVy : 102|10@0+ (0.0625,-32) [-32|31.9375] "m/s"  C3B
 SG_ FR_Obj17_Dx_Vnce : 84|14@0+ (0.05,0) [0|50] "m2"  C3B
 SG_ FR_Obj17_Dx : 65|13@0+ (0.0625,-100) [-100|411.9375] "m"  C3B
 SG_ FR_Obj17_Dy_Vnce : 59|10@0+ (0.02,0) [0|20] "m2"  C3B
 SG_ FR_Obj17_Dy : 54|11@0+ (0.125,-128) [-128|127.875] "m"  C3B
 SG_ FR_Obj17_HeadingAngle : 32|10@0+ (0.01,-3.14) [-3.14|3.14] "rad"  C3B
 SG_ FR_Obj17_Length : 25|9@0+ (0.05,0) [0|25.5] "m"  C3B
 SG_ FR_Obj17_Height : 18|9@0+ (0.01,0) [0|5.11] "m"  C3B
 SG_ FR_Obj17_Width : 12|10@0+ (0.01,0) [0|10.23] "m"  C3B
 SG_ FR_Obj17_TypeProb : 2|6@0+ (2,0) [0|100] "%"  C3B
 SG_ FR_Obj17_Type : 6|4@0+ (1,0) [0|15] ""  C3B

BO_ 296 FR_128: 64 FR
 SG_ FR_CRCCheck_128 : 503|16@0+ (1,0) [0|65535] ""  C3B
 SG_ FR_RollingCounter_128 : 491|4@0+ (1,0) [0|15] ""  C3B
 SG_ FR_Obj18_Ax : 303|10@0+ (0.03125,-16) [-16|15.96875] "m/s2"  C3B
 SG_ FR_Obj18_Ay : 280|9@0+ (0.0625,-16) [-16|15.9375] "m/s2"  C3B
 SG_ FR_Obj18_Vx : 276|12@0+ (0.0625,-128) [-128|127.9375] "m/s"  C3B
 SG_ FR_Obj18_Vy : 270|10@0+ (0.0625,-32) [-32|31.9375] "m/s"  C3B
 SG_ FR_Obj18_DelayTime : 254|16@0+ (1,0) [0|65535] "ms"  C3B
 SG_ FR_Obj18_ReferPoint_Dx : 237|4@0+ (1,0) [0|15] "m"  C3B
 SG_ FR_Obj18_HeightGround : 223|9@0+ (0.1,0) [0|51.1] "m"  C3B
 SG_ FR_Obj18_MotionStatusConf : 213|6@0+ (2,0) [0|63] "-"  C3B
 SG_ FR_Obj18_MotionStatus : 200|3@0+ (1,0) [0|7] ""  C3B
 SG_ FR_Obj18_Measured : 202|2@0+ (1,0) [0|3] ""  C3B
 SG_ FR_Obj18_valid : 203|1@0+ (1,0) [0|1] ""  C3B
 SG_ FR_Obj18_Track_Age : 187|16@0+ (1,0) [0|65535] ""  C3B
 SG_ FR_Obj18_Track_ID : 171|16@0+ (1,0) [0|65535] ""  C3B
 SG_ FR_Obj18_ObstacleProb : 161|6@0+ (2,0) [0|100] "%"  C3B
 SG_ FR_Obj18_ExistProb : 167|6@0+ (2,0) [0|100] "%"  C3B
 SG_ FR_Obj18_RelAx : 145|10@0+ (0.03125,-16) [-16|15.96875] "m/s2"  C3B
 SG_ FR_Obj18_RelAy : 138|9@0+ (0.0625,-16) [-16|15.9375] "m/s2"  C3B
 SG_ FR_Obj18_RelVx_std : 134|12@0+ (0.0625,0) [0|255.9375] "m/s"  C3B
 SG_ FR_Obj18_RelVx : 114|12@0+ (0.0625,-128) [-128|127.9375] "m/s"  C3B
 SG_ FR_Obj18_RelVy_std : 108|10@0+ (0.125,0) [0|127.875] "m/s"  C3B
 SG_ FR_Obj18_RelVy : 102|10@0+ (0.0625,-32) [-32|31.9375] "m/s"  C3B
 SG_ FR_Obj18_Dx_Vnce : 84|14@0+ (0.05,0) [0|50] "m2"  C3B
 SG_ FR_Obj18_Dx : 65|13@0+ (0.0625,-100) [-100|411.9375] "m"  C3B
 SG_ FR_Obj18_Dy_Vnce : 59|10@0+ (0.02,0) [0|20] "m2"  C3B
 SG_ FR_Obj18_Dy : 54|11@0+ (0.125,-128) [-128|127.875] "m"  C3B
 SG_ FR_Obj18_HeadingAngle : 32|10@0+ (0.01,-3.14) [-3.14|3.14] "rad"  C3B
 SG_ FR_Obj18_Length : 25|9@0+ (0.05,0) [0|25.5] "m"  C3B
 SG_ FR_Obj18_Height : 18|9@0+ (0.01,0) [0|5.11] "m"  C3B
 SG_ FR_Obj18_Width : 12|10@0+ (0.01,0) [0|10.23] "m"  C3B
 SG_ FR_Obj18_TypeProb : 2|6@0+ (2,0) [0|100] "%"  C3B
 SG_ FR_Obj18_Type : 6|4@0+ (1,0) [0|15] ""  C3B

BO_ 297 FR_129: 64 FR
 SG_ FR_CRCCheck_129 : 503|16@0+ (1,0) [0|65535] ""  C3B
 SG_ FR_RollingCounter_129 : 491|4@0+ (1,0) [0|15] ""  C3B
 SG_ FR_Obj19_Ax : 303|10@0+ (0.03125,-16) [-16|15.96875] "m/s2"  C3B
 SG_ FR_Obj19_Ay : 280|9@0+ (0.0625,-16) [-16|15.9375] "m/s2"  C3B
 SG_ FR_Obj19_Vx : 276|12@0+ (0.0625,-128) [-128|127.9375] "m/s"  C3B
 SG_ FR_Obj19_Vy : 270|10@0+ (0.0625,-32) [-32|31.9375] "m/s"  C3B
 SG_ FR_Obj19_DelayTime : 254|16@0+ (1,0) [0|65535] "ms"  C3B
 SG_ FR_Obj19_ReferPoint_Dx : 237|4@0+ (1,0) [0|15] "m"  C3B
 SG_ FR_Obj19_HeightGround : 223|9@0+ (0.1,0) [0|51.1] "m"  C3B
 SG_ FR_Obj19_MotionStatusConf : 213|6@0+ (2,0) [0|63] "-"  C3B
 SG_ FR_Obj19_MotionStatus : 200|3@0+ (1,0) [0|7] ""  C3B
 SG_ FR_Obj19_Measured : 202|2@0+ (1,0) [0|3] ""  C3B
 SG_ FR_Obj19_valid : 203|1@0+ (1,0) [0|1] ""  C3B
 SG_ FR_Obj19_Track_Age : 187|16@0+ (1,0) [0|65535] ""  C3B
 SG_ FR_Obj19_Track_ID : 171|16@0+ (1,0) [0|65535] ""  C3B
 SG_ FR_Obj19_ObstacleProb : 161|6@0+ (2,0) [0|100] "%"  C3B
 SG_ FR_Obj19_ExistProb : 167|6@0+ (2,0) [0|100] "%"  C3B
 SG_ FR_Obj19_RelAx : 145|10@0+ (0.03125,-16) [-16|15.96875] "m/s2"  C3B
 SG_ FR_Obj19_RelAy : 138|9@0+ (0.0625,-16) [-16|15.9375] "m/s2"  C3B
 SG_ FR_Obj19_RelVx_std : 134|12@0+ (0.0625,0) [0|255.9375] "m/s"  C3B
 SG_ FR_Obj19_RelVx : 114|12@0+ (0.0625,-128) [-128|127.9375] "m/s"  C3B
 SG_ FR_Obj19_RelVy_std : 108|10@0+ (0.125,0) [0|127.875] "m/s"  C3B
 SG_ FR_Obj19_RelVy : 102|10@0+ (0.0625,-32) [-32|31.9375] "m/s"  C3B
 SG_ FR_Obj19_Dx_Vnce : 84|14@0+ (0.05,0) [0|50] "m2"  C3B
 SG_ FR_Obj19_Dx : 65|13@0+ (0.0625,-100) [-100|411.9375] "m"  C3B
 SG_ FR_Obj19_Dy_Vnce : 59|10@0+ (0.02,0) [0|20] "m2"  C3B
 SG_ FR_Obj19_Dy : 54|11@0+ (0.125,-128) [-128|127.875] "m"  C3B
 SG_ FR_Obj19_HeadingAngle : 32|10@0+ (0.01,-3.14) [-3.14|3.14] "rad"  C3B
 SG_ FR_Obj19_Length : 25|9@0+ (0.05,0) [0|25.5] "m"  C3B
 SG_ FR_Obj19_Height : 18|9@0+ (0.01,0) [0|5.11] "m"  C3B
 SG_ FR_Obj19_Width : 12|10@0+ (0.01,0) [0|10.23] "m"  C3B
 SG_ FR_Obj19_TypeProb : 2|6@0+ (2,0) [0|100] "%"  C3B
 SG_ FR_Obj19_Type : 6|4@0+ (1,0) [0|15] ""  C3B

BO_ 298 FR_12A: 64 FR
 SG_ FR_CRCCheck_12A : 503|16@0+ (1,0) [0|65535] ""  C3B
 SG_ FR_RollingCounter_12A : 491|4@0+ (1,0) [0|15] ""  C3B
 SG_ FR_Obj13_Ax : 303|10@0+ (0.03125,-16) [-16|15.96875] "m/s2"  C3B
 SG_ FR_Obj13_Ay : 280|9@0+ (0.0625,-16) [-16|15.9375] "m/s2"  C3B
 SG_ FR_Obj13_Vx : 276|12@0+ (0.0625,-128) [-128|127.9375] "m/s"  C3B
 SG_ FR_Obj13_Vy : 270|10@0+ (0.0625,-32) [-32|31.9375] "m/s"  C3B
 SG_ FR_Obj13_DelayTime : 254|16@0+ (1,0) [0|65535] "ms"  C3B
 SG_ FR_Obj13_ReferPoint_Dx : 237|4@0+ (1,0) [0|15] "m"  C3B
 SG_ FR_Obj13_HeightGround : 223|9@0+ (0.1,0) [0|51.1] "m"  C3B
 SG_ FR_Obj13_MotionStatusConf : 213|6@0+ (2,0) [0|63] "-"  C3B
 SG_ FR_Obj13_MotionStatus : 200|3@0+ (1,0) [0|7] ""  C3B
 SG_ FR_Obj13_Measured : 202|2@0+ (1,0) [0|3] ""  C3B
 SG_ FR_Obj13_valid : 203|1@0+ (1,0) [0|1] ""  C3B
 SG_ FR_Obj13_Track_Age : 187|16@0+ (1,0) [0|65535] ""  C3B
 SG_ FR_Obj13_Track_ID : 171|16@0+ (1,0) [0|65535] ""  C3B
 SG_ FR_Obj13_ObstacleProb : 161|6@0+ (2,0) [0|100] "%"  C3B
 SG_ FR_Obj13_ExistProb : 167|6@0+ (2,0) [0|100] "%"  C3B
 SG_ FR_Obj13_RelAx : 145|10@0+ (0.03125,-16) [-16|15.96875] "m/s2"  C3B
 SG_ FR_Obj13_RelAy : 138|9@0+ (0.0625,-16) [-16|15.9375] "m/s2"  C3B
 SG_ FR_Obj13_RelVx_std : 134|12@0+ (0.0625,0) [0|255.9375] "m/s"  C3B
 SG_ FR_Obj13_RelVx : 114|12@0+ (0.0625,-128) [-128|127.9375] "m/s"  C3B
 SG_ FR_Obj13_RelVy_std : 108|10@0+ (0.125,0) [0|127.875] "m/s"  C3B
 SG_ FR_Obj13_RelVy : 102|10@0+ (0.0625,-32) [-32|31.9375] "m/s"  C3B
 SG_ FR_Obj13_Dx_Vnce : 84|14@0+ (0.05,0) [0|50] "m2"  C3B
 SG_ FR_Obj13_Dx : 65|13@0+ (0.0625,-100) [-100|411.9375] "m"  C3B
 SG_ FR_Obj13_Dy_Vnce : 59|10@0+ (0.02,0) [0|20] "m2"  C3B
 SG_ FR_Obj13_Dy : 54|11@0+ (0.125,-128) [-128|127.875] "m"  C3B
 SG_ FR_Obj13_HeadingAngle : 32|10@0+ (0.01,-3.14) [-3.14|3.14] "rad"  C3B
 SG_ FR_Obj13_Length : 25|9@0+ (0.05,0) [0|25.5] "m"  C3B
 SG_ FR_Obj13_Height : 18|9@0+ (0.01,0) [0|5.11] "m"  C3B
 SG_ FR_Obj13_Width : 12|10@0+ (0.01,0) [0|10.23] "m"  C3B
 SG_ FR_Obj13_TypeProb : 2|6@0+ (2,0) [0|100] "%"  C3B
 SG_ FR_Obj13_Type : 6|4@0+ (1,0) [0|15] ""  C3B

BO_ 299 FR_12B: 64 FR
 SG_ FR_CRCCheck_12B : 503|16@0+ (1,0) [0|65535] ""  C3B
 SG_ FR_RollingCounter_12B : 491|4@0+ (1,0) [0|15] ""  C3B
 SG_ FR_Obj20_Ax : 303|10@0+ (0.03125,-16) [-16|15.96875] "m/s2"  C3B
 SG_ FR_Obj20_Ay : 280|9@0+ (0.0625,-16) [-16|15.9375] "m/s2"  C3B
 SG_ FR_Obj20_Vx : 276|12@0+ (0.0625,-128) [-128|127.9375] "m/s"  C3B
 SG_ FR_Obj20_Vy : 270|10@0+ (0.0625,-32) [-32|31.9375] "m/s"  C3B
 SG_ FR_Obj20_DelayTime : 254|16@0+ (1,0) [0|65535] "ms"  C3B
 SG_ FR_Obj20_ReferPoint_Dx : 237|4@0+ (1,0) [0|15] "m"  C3B
 SG_ FR_Obj20_HeightGround : 223|9@0+ (0.1,0) [0|51.1] "m"  C3B
 SG_ FR_Obj20_MotionStatusConf : 213|6@0+ (2,0) [0|63] "-"  C3B
 SG_ FR_Obj20_MotionStatus : 200|3@0+ (1,0) [0|7] ""  C3B
 SG_ FR_Obj20_Measured : 202|2@0+ (1,0) [0|3] ""  C3B
 SG_ FR_Obj20_valid : 203|1@0+ (1,0) [0|1] ""  C3B
 SG_ FR_Obj20_Track_Age : 187|16@0+ (1,0) [0|65535] ""  C3B
 SG_ FR_Obj20_Track_ID : 171|16@0+ (1,0) [0|65535] ""  C3B
 SG_ FR_Obj20_ObstacleProb : 161|6@0+ (2,0) [0|100] "%"  C3B
 SG_ FR_Obj20_ExistProb : 167|6@0+ (2,0) [0|100] "%"  C3B
 SG_ FR_Obj20_RelAx : 145|10@0+ (0.03125,-16) [-16|15.96875] "m/s2"  C3B
 SG_ FR_Obj20_RelAy : 138|9@0+ (0.0625,-16) [-16|15.9375] "m/s2"  C3B
 SG_ FR_Obj20_RelVx_std : 134|12@0+ (0.0625,0) [0|255.9375] "m/s"  C3B
 SG_ FR_Obj20_RelVx : 114|12@0+ (0.0625,-128) [-128|127.9375] "m/s"  C3B
 SG_ FR_Obj20_RelVy_std : 108|10@0+ (0.125,0) [0|127.875] "m/s"  C3B
 SG_ FR_Obj20_RelVy : 102|10@0+ (0.0625,-32) [-32|31.9375] "m/s"  C3B
 SG_ FR_Obj20_Dx_Vnce : 84|14@0+ (0.05,0) [0|50] "m2"  C3B
 SG_ FR_Obj20_Dx : 65|13@0+ (0.0625,-100) [-100|411.9375] "m"  C3B
 SG_ FR_Obj20_Dy_Vnce : 59|10@0+ (0.02,0) [0|20] "m2"  C3B
 SG_ FR_Obj20_Dy : 54|11@0+ (0.125,-128) [-128|127.875] "m"  C3B
 SG_ FR_Obj20_HeadingAngle : 32|10@0+ (0.01,-3.14) [-3.14|3.14] "rad"  C3B
 SG_ FR_Obj20_Length : 25|9@0+ (0.05,0) [0|25.5] "m"  C3B
 SG_ FR_Obj20_Height : 18|9@0+ (0.01,0) [0|5.11] "m"  C3B
 SG_ FR_Obj20_Width : 12|10@0+ (0.01,0) [0|10.23] "m"  C3B
 SG_ FR_Obj20_TypeProb : 2|6@0+ (2,0) [0|100] "%"  C3B
 SG_ FR_Obj20_Type : 6|4@0+ (1,0) [0|15] ""  C3B

BO_ 300 FR_12C: 64 FR
 SG_ FR_CRCCheck_12C : 503|16@0+ (1,0) [0|65535] ""  C3B
 SG_ FR_RollingCounter_12C : 491|4@0+ (1,0) [0|15] ""  C3B
 SG_ FR_Obj21_Ax : 303|10@0+ (0.03125,-16) [-16|15.96875] "m/s2"  C3B
 SG_ FR_Obj21_Ay : 280|9@0+ (0.0625,-16) [-16|15.9375] "m/s2"  C3B
 SG_ FR_Obj21_Vx : 276|12@0+ (0.0625,-128) [-128|127.9375] "m/s"  C3B
 SG_ FR_Obj21_Vy : 270|10@0+ (0.0625,-32) [-32|31.9375] "m/s"  C3B
 SG_ FR_Obj21_DelayTime : 254|16@0+ (1,0) [0|65535] "ms"  C3B
 SG_ FR_Obj21_ReferPoint_Dx : 237|4@0+ (1,0) [0|15] "m"  C3B
 SG_ FR_Obj21_HeightGround : 223|9@0+ (0.1,0) [0|51.1] "m"  C3B
 SG_ FR_Obj21_MotionStatusConf : 213|6@0+ (2,0) [0|63] "-"  C3B
 SG_ FR_Obj21_MotionStatus : 200|3@0+ (1,0) [0|7] ""  C3B
 SG_ FR_Obj21_Measured : 202|2@0+ (1,0) [0|3] ""  C3B
 SG_ FR_Obj21_valid : 203|1@0+ (1,0) [0|1] ""  C3B
 SG_ FR_Obj21_Track_Age : 187|16@0+ (1,0) [0|65535] ""  C3B
 SG_ FR_Obj21_Track_ID : 171|16@0+ (1,0) [0|65535] ""  C3B
 SG_ FR_Obj21_ObstacleProb : 161|6@0+ (2,0) [0|100] "%"  C3B
 SG_ FR_Obj21_ExistProb : 167|6@0+ (2,0) [0|100] "%"  C3B
 SG_ FR_Obj21_RelAx : 145|10@0+ (0.03125,-16) [-16|15.96875] "m/s2"  C3B
 SG_ FR_Obj21_RelAy : 138|9@0+ (0.0625,-16) [-16|15.9375] "m/s2"  C3B
 SG_ FR_Obj21_RelVx_std : 134|12@0+ (0.0625,0) [0|255.9375] "m/s"  C3B
 SG_ FR_Obj21_RelVx : 114|12@0+ (0.0625,-128) [-128|127.9375] "m/s"  C3B
 SG_ FR_Obj21_RelVy_std : 108|10@0+ (0.125,0) [0|127.875] "m/s"  C3B
 SG_ FR_Obj21_RelVy : 102|10@0+ (0.0625,-32) [-32|31.9375] "m/s"  C3B
 SG_ FR_Obj21_Dx_Vnce : 84|14@0+ (0.05,0) [0|50] "m2"  C3B
 SG_ FR_Obj21_Dx : 65|13@0+ (0.0625,-100) [-100|411.9375] "m"  C3B
 SG_ FR_Obj21_Dy_Vnce : 59|10@0+ (0.02,0) [0|20] "m2"  C3B
 SG_ FR_Obj21_Dy : 54|11@0+ (0.125,-128) [-128|127.875] "m"  C3B
 SG_ FR_Obj21_HeadingAngle : 32|10@0+ (0.01,-3.14) [-3.14|3.14] "rad"  C3B
 SG_ FR_Obj21_Length : 25|9@0+ (0.05,0) [0|25.5] "m"  C3B
 SG_ FR_Obj21_Height : 18|9@0+ (0.01,0) [0|5.11] "m"  C3B
 SG_ FR_Obj21_Width : 12|10@0+ (0.01,0) [0|10.23] "m"  C3B
 SG_ FR_Obj21_TypeProb : 2|6@0+ (2,0) [0|100] "%"  C3B
 SG_ FR_Obj21_Type : 6|4@0+ (1,0) [0|15] ""  C3B

BO_ 301 FR_12D: 64 FR
 SG_ FR_CRCCheck_12D : 503|16@0+ (1,0) [0|65535] ""  C3B
 SG_ FR_RollingCounter_12D : 491|4@0+ (1,0) [0|15] ""  C3B
 SG_ FR_Obj22_Ax : 303|10@0+ (0.03125,-16) [-16|15.96875] "m/s2"  C3B
 SG_ FR_Obj22_Ay : 280|9@0+ (0.0625,-16) [-16|15.9375] "m/s2"  C3B
 SG_ FR_Obj22_Vx : 276|12@0+ (0.0625,-128) [-128|127.9375] "m/s"  C3B
 SG_ FR_Obj22_Vy : 270|10@0+ (0.0625,-32) [-32|31.9375] "m/s"  C3B
 SG_ FR_Obj22_DelayTime : 254|16@0+ (1,0) [0|65535] "ms"  C3B
 SG_ FR_Obj22_ReferPoint_Dx : 237|4@0+ (1,0) [0|15] "m"  C3B
 SG_ FR_Obj22_HeightGround : 223|9@0+ (0.1,0) [0|51.1] "m"  C3B
 SG_ FR_Obj22_MotionStatusConf : 213|6@0+ (2,0) [0|63] "-"  C3B
 SG_ FR_Obj22_MotionStatus : 200|3@0+ (1,0) [0|7] ""  C3B
 SG_ FR_Obj22_Measured : 202|2@0+ (1,0) [0|3] ""  C3B
 SG_ FR_Obj22_valid : 203|1@0+ (1,0) [0|1] ""  C3B
 SG_ FR_Obj22_Track_Age : 187|16@0+ (1,0) [0|65535] ""  C3B
 SG_ FR_Obj22_Track_ID : 171|16@0+ (1,0) [0|65535] ""  C3B
 SG_ FR_Obj22_ObstacleProb : 161|6@0+ (2,0) [0|100] "%"  C3B
 SG_ FR_Obj22_ExistProb : 167|6@0+ (2,0) [0|100] "%"  C3B
 SG_ FR_Obj22_RelAx : 145|10@0+ (0.03125,-16) [-16|15.96875] "m/s2"  C3B
 SG_ FR_Obj22_RelAy : 138|9@0+ (0.0625,-16) [-16|15.9375] "m/s2"  C3B
 SG_ FR_Obj22_RelVx_std : 134|12@0+ (0.0625,0) [0|255.9375] "m/s"  C3B
 SG_ FR_Obj22_RelVx : 114|12@0+ (0.0625,-128) [-128|127.9375] "m/s"  C3B
 SG_ FR_Obj22_RelVy_std : 108|10@0+ (0.125,0) [0|127.875] "m/s"  C3B
 SG_ FR_Obj22_RelVy : 102|10@0+ (0.0625,-32) [-32|31.9375] "m/s"  C3B
 SG_ FR_Obj22_Dx_Vnce : 84|14@0+ (0.05,0) [0|50] "m2"  C3B
 SG_ FR_Obj22_Dx : 65|13@0+ (0.0625,-100) [-100|411.9375] "m"  C3B
 SG_ FR_Obj22_Dy_Vnce : 59|10@0+ (0.02,0) [0|20] "m2"  C3B
 SG_ FR_Obj22_Dy : 54|11@0+ (0.125,-128) [-128|127.875] "m"  C3B
 SG_ FR_Obj22_HeadingAngle : 32|10@0+ (0.01,-3.14) [-3.14|3.14] "rad"  C3B
 SG_ FR_Obj22_Length : 25|9@0+ (0.05,0) [0|25.5] "m"  C3B
 SG_ FR_Obj22_Height : 18|9@0+ (0.01,0) [0|5.11] "m"  C3B
 SG_ FR_Obj22_Width : 12|10@0+ (0.01,0) [0|10.23] "m"  C3B
 SG_ FR_Obj22_TypeProb : 2|6@0+ (2,0) [0|100] "%"  C3B
 SG_ FR_Obj22_Type : 6|4@0+ (1,0) [0|15] ""  C3B

BO_ 302 FR_12E: 64 FR
 SG_ FR_CRCCheck_12E : 503|16@0+ (1,0) [0|65535] ""  C3B
 SG_ FR_RollingCounter_12E : 491|4@0+ (1,0) [0|15] ""  C3B
 SG_ FR_Obj23_Ax : 303|10@0+ (0.03125,-16) [-16|15.96875] "m/s2"  C3B
 SG_ FR_Obj23_Ay : 280|9@0+ (0.0625,-16) [-16|15.9375] "m/s2"  C3B
 SG_ FR_Obj23_Vx : 276|12@0+ (0.0625,-128) [-128|127.9375] "m/s"  C3B
 SG_ FR_Obj23_Vy : 270|10@0+ (0.0625,-32) [-32|31.9375] "m/s"  C3B
 SG_ FR_Obj23_DelayTime : 254|16@0+ (1,0) [0|65535] "ms"  C3B
 SG_ FR_Obj23_ReferPoint_Dx : 237|4@0+ (1,0) [0|15] "m"  C3B
 SG_ FR_Obj23_HeightGround : 223|9@0+ (0.1,0) [0|51.1] "m"  C3B
 SG_ FR_Obj23_MotionStatusConf : 213|6@0+ (2,0) [0|63] "-"  C3B
 SG_ FR_Obj23_MotionStatus : 200|3@0+ (1,0) [0|7] ""  C3B
 SG_ FR_Obj23_Measured : 202|2@0+ (1,0) [0|3] ""  C3B
 SG_ FR_Obj23_valid : 203|1@0+ (1,0) [0|1] ""  C3B
 SG_ FR_Obj23_Track_Age : 187|16@0+ (1,0) [0|65535] ""  C3B
 SG_ FR_Obj23_Track_ID : 171|16@0+ (1,0) [0|65535] ""  C3B
 SG_ FR_Obj23_ObstacleProb : 161|6@0+ (2,0) [0|100] "%"  C3B
 SG_ FR_Obj23_ExistProb : 167|6@0+ (2,0) [0|100] "%"  C3B
 SG_ FR_Obj23_RelAx : 145|10@0+ (0.03125,-16) [-16|15.96875] "m/s2"  C3B
 SG_ FR_Obj23_RelAy : 138|9@0+ (0.0625,-16) [-16|15.9375] "m/s2"  C3B
 SG_ FR_Obj23_RelVx_std : 134|12@0+ (0.0625,0) [0|255.9375] "m/s"  C3B
 SG_ FR_Obj23_RelVx : 114|12@0+ (0.0625,-128) [-128|127.9375] "m/s"  C3B
 SG_ FR_Obj23_RelVy_std : 108|10@0+ (0.125,0) [0|127.875] "m/s"  C3B
 SG_ FR_Obj23_RelVy : 102|10@0+ (0.0625,-32) [-32|31.9375] "m/s"  C3B
 SG_ FR_Obj23_Dx_Vnce : 84|14@0+ (0.05,0) [0|50] "m2"  C3B
 SG_ FR_Obj23_Dx : 65|13@0+ (0.0625,-100) [-100|411.9375] "m"  C3B
 SG_ FR_Obj23_Dy_Vnce : 59|10@0+ (0.02,0) [0|20] "m2"  C3B
 SG_ FR_Obj23_Dy : 54|11@0+ (0.125,-128) [-128|127.875] "m"  C3B
 SG_ FR_Obj23_HeadingAngle : 32|10@0+ (0.01,-3.14) [-3.14|3.14] "rad"  C3B
 SG_ FR_Obj23_Length : 25|9@0+ (0.05,0) [0|25.5] "m"  C3B
 SG_ FR_Obj23_Height : 18|9@0+ (0.01,0) [0|5.11] "m"  C3B
 SG_ FR_Obj23_Width : 12|10@0+ (0.01,0) [0|10.23] "m"  C3B
 SG_ FR_Obj23_TypeProb : 2|6@0+ (2,0) [0|100] "%"  C3B
 SG_ FR_Obj23_Type : 6|4@0+ (1,0) [0|15] ""  C3B

BO_ 303 FR_12F: 64 FR
 SG_ FR_CRCCheck_12F : 503|16@0+ (1,0) [0|65535] ""  C3B
 SG_ FR_RollingCounter_12F : 491|4@0+ (1,0) [0|15] ""  C3B
 SG_ FR_Obj24_Ax : 303|10@0+ (0.03125,-16) [-16|15.96875] "m/s2"  C3B
 SG_ FR_Obj24_Ay : 280|9@0+ (0.0625,-16) [-16|15.9375] "m/s2"  C3B
 SG_ FR_Obj24_Vx : 276|12@0+ (0.0625,-128) [-128|127.9375] "m/s"  C3B
 SG_ FR_Obj24_Vy : 270|10@0+ (0.0625,-32) [-32|31.9375] "m/s"  C3B
 SG_ FR_Obj24_DelayTime : 254|16@0+ (1,0) [0|65535] "ms"  C3B
 SG_ FR_Obj24_ReferPoint_Dx : 237|4@0+ (1,0) [0|15] "m"  C3B
 SG_ FR_Obj24_HeightGround : 223|9@0+ (0.1,0) [0|51.1] "m"  C3B
 SG_ FR_Obj24_MotionStatusConf : 213|6@0+ (2,0) [0|63] "-"  C3B
 SG_ FR_Obj24_MotionStatus : 200|3@0+ (1,0) [0|7] ""  C3B
 SG_ FR_Obj24_Measured : 202|2@0+ (1,0) [0|3] ""  C3B
 SG_ FR_Obj24_valid : 203|1@0+ (1,0) [0|1] ""  C3B
 SG_ FR_Obj24_Track_Age : 187|16@0+ (1,0) [0|65535] ""  C3B
 SG_ FR_Obj24_Track_ID : 171|16@0+ (1,0) [0|65535] ""  C3B
 SG_ FR_Obj24_ObstacleProb : 161|6@0+ (2,0) [0|100] "%"  C3B
 SG_ FR_Obj24_ExistProb : 167|6@0+ (2,0) [0|100] "%"  C3B
 SG_ FR_Obj24_RelAx : 145|10@0+ (0.03125,-16) [-16|15.96875] "m/s2"  C3B
 SG_ FR_Obj24_RelAy : 138|9@0+ (0.0625,-16) [-16|15.9375] "m/s2"  C3B
 SG_ FR_Obj24_RelVx_std : 134|12@0+ (0.0625,0) [0|255.9375] "m/s"  C3B
 SG_ FR_Obj24_RelVx : 114|12@0+ (0.0625,-128) [-128|127.9375] "m/s"  C3B
 SG_ FR_Obj24_RelVy_std : 108|10@0+ (0.125,0) [0|127.875] "m/s"  C3B
 SG_ FR_Obj24_RelVy : 102|10@0+ (0.0625,-32) [-32|31.9375] "m/s"  C3B
 SG_ FR_Obj24_Dx_Vnce : 84|14@0+ (0.05,0) [0|50] "m2"  C3B
 SG_ FR_Obj24_Dx : 65|13@0+ (0.0625,-100) [-100|411.9375] "m"  C3B
 SG_ FR_Obj24_Dy_Vnce : 59|10@0+ (0.02,0) [0|20] "m2"  C3B
 SG_ FR_Obj24_Dy : 54|11@0+ (0.125,-128) [-128|127.875] "m"  C3B
 SG_ FR_Obj24_HeadingAngle : 32|10@0+ (0.01,-3.14) [-3.14|3.14] "rad"  C3B
 SG_ FR_Obj24_Length : 25|9@0+ (0.05,0) [0|25.5] "m"  C3B
 SG_ FR_Obj24_Height : 18|9@0+ (0.01,0) [0|5.11] "m"  C3B
 SG_ FR_Obj24_Width : 12|10@0+ (0.01,0) [0|10.23] "m"  C3B
 SG_ FR_Obj24_TypeProb : 2|6@0+ (2,0) [0|100] "%"  C3B
 SG_ FR_Obj24_Type : 6|4@0+ (1,0) [0|15] ""  C3B

BO_ 338 C3B_152: 64 C3B
 SG_ ADC_SenceMode : 131|2@0+ (1,0) [0|3] ""  FR
 SG_ AD_Reqmode : 89|2@0+ (1,0) [0|3] ""  FR

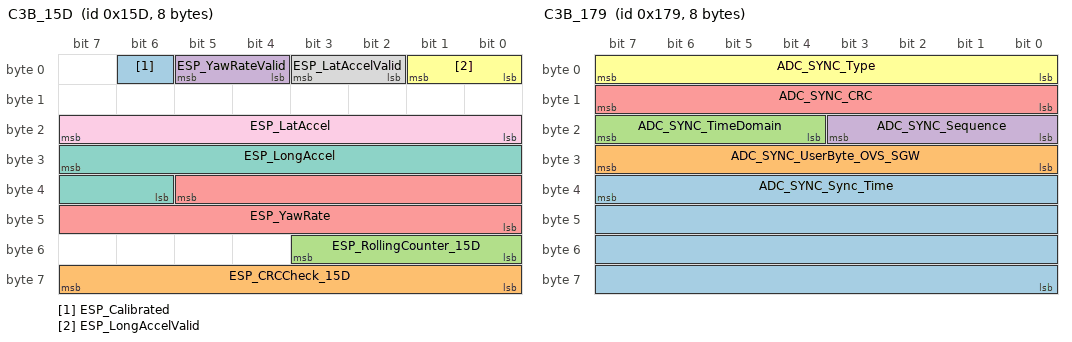
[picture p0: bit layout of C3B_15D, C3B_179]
BO_ 349 C3B_15D: 8 C3B
 SG_ ESP_Calibrated : 6|1@0+ (1,0) [0|1] ""  FR
 SG_ ESP_CRCCheck_15D : 63|8@0+ (1,0) [0|255] ""  FR
 SG_ ESP_RollingCounter_15D : 51|4@0+ (1,0) [0|15] ""  FR
 SG_ ESP_YawRateValid : 5|2@0+ (1,0) [0|3] ""  FR
 SG_ ESP_YawRate : 37|14@0+ (0.01,-81.91) [-81.91|81.92] "degree/s"  FR
 SG_ ESP_LongAccelValid : 1|2@0+ (1,0) [0|3] ""  FR
 SG_ ESP_LongAccel : 31|10@0+ (0.03125,-16) [-16|15.90625] "m/s2"  FR
 SG_ ESP_LatAccelValid : 3|2@0+ (1,0) [0|3] ""  FR
 SG_ ESP_LatAccel : 23|8@0+ (0.1,-12.7) [-12.7|12.7] "m/s2"  FR

BO_ 377 C3B_179: 8 C3B
 SG_ ADC_SYNC_Sync_Time : 39|32@0+ (1,0) [0|4290000000] ""  FR
 SG_ ADC_SYNC_UserByte_OVS_SGW : 31|8@0+ (1,0) [0|255] ""  FR
 SG_ ADC_SYNC_TimeDomain : 23|4@0+ (1,0) [0|15] ""  FR
 SG_ ADC_SYNC_Sequence : 19|4@0+ (1,0) [0|15] ""  FR
 SG_ ADC_SYNC_CRC : 15|8@0+ (1,0) [0|255] ""  FR
 SG_ ADC_SYNC_Type : 7|8@0+ (1,0) [0|255] ""  FR

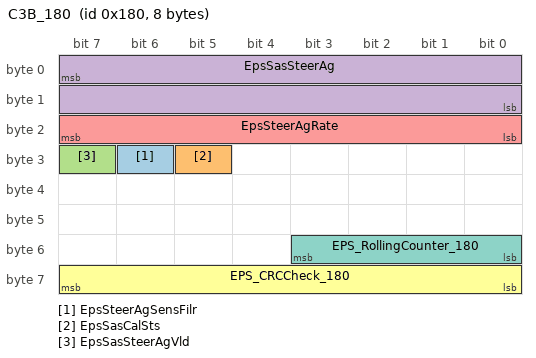
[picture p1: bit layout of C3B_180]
BO_ 384 C3B_180: 8 C3B
 SG_ EpsSteerAgSensFilr : 30|1@0+ (1,0) [0|1] ""  FR
 SG_ EpsSasCalSts : 29|1@0+ (1,0) [0|1] ""  FR
 SG_ EpsSasSteerAgVld : 31|1@0+ (1,0) [0|1] ""  FR
 SG_ EpsSasSteerAg : 7|16@0- (0.1,0) [-780|780] "degree"  FR
 SG_ EpsSteerAgRate : 23|8@0+ (4,0) [0|1016] "deg/s"  FR
 SG_ EPS_CRCCheck_180 : 63|8@0+ (1,0) [0|255] ""  FR
 SG_ EPS_RollingCounter_180 : 51|4@0+ (1,0) [0|15] ""  FR

BO_ 433 C3B_1B1: 64 C3B
 SG_ VcuAccrPedlPosnVld : 216|1@0+ (1,0) [0|1] ""  FR
 SG_ VcuAccrPedlPosn : 195|10@0+ (0.1,0) [0|102.3] "%"  FR
 SG_ VcuRdySts : 7|1@0+ (1,0) [0|1] ""  FR
 SG_ VcuVehGearPosnVld : 2|1@0+ (1,0) [0|1] ""  FR
 SG_ VcuGearPosn : 5|3@0+ (1,0) [0|7] ""  FR
 SG_ VCU_CRCCheck_1B1 : 439|16@0+ (1,0) [0|65535] ""  FR
 SG_ VCU_RollingCounter_1B1 : 427|4@0+ (1,0) [0|15] ""  FR

BO_ 450 C3B_1C2: 64 C3B
 SG_ WhlSpdReRiPls : 407|8@0+ (1,0) [0|254] ""  FR
 SG_ WhlSpdRiReDir : 65|2@0+ (1,0) [0|3] ""  FR
 SG_ WhlSpdRiReDataVld : 7|1@0+ (1,0) [0|1] ""  FR
 SG_ WhlSpdRiReData : 4|13@0+ (0.05625,0) [0|460.74375] "km/h"  FR
 SG_ WhlSpdReLePls : 263|8@0+ (1,0) [0|254] ""  FR
 SG_ WhlSpdLeReDir : 67|2@0+ (1,0) [0|3] ""  FR
 SG_ WhlSpdLeReDataVld : 23|1@0+ (1,0) [0|1] ""  FR
 SG_ WhlSpdLeReData : 20|13@0+ (0.05625,0) [0|460.74375] "km/h"  FR
 SG_ WhlSpdFrntRiPls : 239|8@0+ (1,0) [0|254] ""  FR
 SG_ WhlSpdRiFrntDir : 134|2@0+ (1,0) [0|3] ""  FR
 SG_ WhlSpdRiFrntDataVld : 135|1@0+ (1,0) [0|1] ""  FR
 SG_ WhlSpdRiFrntData : 132|13@0+ (0.05625,0) [0|460.74375] "km/h"  FR
 SG_ WhlSpdFrntLePls : 63|8@0+ (1,0) [0|254] ""  FR
 SG_ WhlSpdLeFrntDir : 150|2@0+ (1,0) [0|3] ""  FR
 SG_ WhlSpdLeFrntDataVld : 151|1@0+ (1,0) [0|1] ""  FR
 SG_ WhlSpdLeFrntData : 148|13@0+ (0.05625,0) [0|460.74375] "km/h"  FR
 SG_ EspVehStandstill : 351|1@0+ (1,0) [0|1] ""  FR
 SG_ EspVehSpdVld : 101|1@0+ (1,0) [0|1] ""  FR
 SG_ EspVehSpd : 100|13@0+ (0.05625,0) [0|460.744] "km/h"  FR
 SG_ ESP_RollingCounter_1C2 : 427|4@0+ (1,0) [0|15] ""  FR
 SG_ ESP_CRCCheck_1C2 : 439|16@0+ (1,0) [0|65535] ""  FR

CM_ BO_ 273 " ";
CM_ SG_ 273 FR_CRCCheck_111 " ";
CM_ SG_ 273 FR_RollingCounter_111 " ";
CM_ SG_ 273 FR_Obj1_Ax " ";
CM_ SG_ 273 FR_Obj1_Ay " ";
CM_ SG_ 273 FR_Obj1_Vx " ";
CM_ SG_ 273 FR_Obj1_Vy " ";
CM_ SG_ 273 FR_Obj1_DelayTime " ";
CM_ SG_ 273 FR_Obj1_ReferPoint_Dx " ";
CM_ SG_ 273 FR_Obj1_HeightGround "反射点最强点距离地面的高度 ";
CM_ SG_ 273 FR_Obj1_MotionStatusConf " ";
CM_ SG_ 273 FR_Obj1_MotionStatus " ";
CM_ SG_ 273 FR_Obj1_Measured " ";
CM_ SG_ 273 FR_Obj1_valid " ";
CM_ SG_ 273 FR_Obj1_Track_Age " ";
CM_ SG_ 273 FR_Obj1_Track_ID " ";
CM_ SG_ 273 FR_Obj1_ObstacleProb " ";
CM_ SG_ 273 FR_Obj1_ExistProb " ";
CM_ SG_ 273 FR_Obj1_RelAx " ";
CM_ SG_ 273 FR_Obj1_RelAy " ";
CM_ SG_ 273 FR_Obj1_RelVx_std " ";
CM_ SG_ 273 FR_Obj1_RelVx " ";
CM_ SG_ 273 FR_Obj1_RelVy_std " ";
CM_ SG_ 273 FR_Obj1_RelVy " ";
CM_ SG_ 273 FR_Obj1_Dx_Vnce " ";
CM_ SG_ 273 FR_Obj1_Dx " ";
CM_ SG_ 273 FR_Obj1_Dy_Vnce " ";
CM_ SG_ 273 FR_Obj1_Dy " ";
CM_ SG_ 273 FR_Obj1_HeadingAngle " ";
CM_ SG_ 273 FR_Obj1_Length " ";
CM_ SG_ 273 FR_Obj1_Height " ";
CM_ SG_ 273 FR_Obj1_Width " ";
CM_ SG_ 273 FR_Obj1_TypeProb " ";
CM_ SG_ 273 FR_Obj1_Type " ";
CM_ BO_ 274 " ";
CM_ SG_ 274 FR_CRCCheck_112 " ";
CM_ SG_ 274 FR_RollingCounter_112 " ";
CM_ SG_ 274 FR_Obj2_Ax " ";
CM_ SG_ 274 FR_Obj2_Ay " ";
CM_ SG_ 274 FR_Obj2_Vx " ";
CM_ SG_ 274 FR_Obj2_Vy " ";
CM_ SG_ 274 FR_Obj2_DelayTime " ";
CM_ SG_ 274 FR_Obj2_ReferPoint_Dx " ";
CM_ SG_ 274 FR_Obj2_HeightGround "反射点最强点距离地面的高度 ";
CM_ SG_ 274 FR_Obj2_MotionStatusConf " ";
CM_ SG_ 274 FR_Obj2_MotionStatus " ";
CM_ SG_ 274 FR_Obj2_Measured " ";
CM_ SG_ 274 FR_Obj2_valid " ";
CM_ SG_ 274 FR_Obj2_Track_Age " ";
CM_ SG_ 274 FR_Obj2_Track_ID " ";
CM_ SG_ 274 FR_Obj2_ObstacleProb " ";
CM_ SG_ 274 FR_Obj2_ExistProb " ";
CM_ SG_ 274 FR_Obj2_RelAx " ";
CM_ SG_ 274 FR_Obj2_RelAy " ";
CM_ SG_ 274 FR_Obj2_RelVx_std " ";
CM_ SG_ 274 FR_Obj2_RelVx " ";
CM_ SG_ 274 FR_Obj2_RelVy_std " ";
CM_ SG_ 274 FR_Obj2_RelVy " ";
CM_ SG_ 274 FR_Obj2_Dx_Vnce " ";
CM_ SG_ 274 FR_Obj2_Dx " ";
CM_ SG_ 274 FR_Obj2_Dy_Vnce " ";
CM_ SG_ 274 FR_Obj2_Dy " ";
CM_ SG_ 274 FR_Obj2_HeadingAngle " ";
CM_ SG_ 274 FR_Obj2_Length " ";
CM_ SG_ 274 FR_Obj2_Height " ";
CM_ SG_ 274 FR_Obj2_Width " ";
CM_ SG_ 274 FR_Obj2_TypeProb " ";
CM_ SG_ 274 FR_Obj2_Type " ";
CM_ BO_ 275 " ";
CM_ SG_ 275 FR_CRCCheck_113 " ";
CM_ SG_ 275 FR_RollingCounter_113 " ";
CM_ SG_ 275 FR_Obj3_Ax " ";
CM_ SG_ 275 FR_Obj3_Ay " ";
CM_ SG_ 275 FR_Obj3_Vx " ";
CM_ SG_ 275 FR_Obj3_Vy " ";
CM_ SG_ 275 FR_Obj3_DelayTime " ";
CM_ SG_ 275 FR_Obj3_ReferPoint_Dx " ";
CM_ SG_ 275 FR_Obj3_HeightGround "反射点最强点距离地面的高度 ";
CM_ SG_ 275 FR_Obj3_MotionStatusConf " ";
CM_ SG_ 275 FR_Obj3_MotionStatus " ";
CM_ SG_ 275 FR_Obj3_Measured " ";
CM_ SG_ 275 FR_Obj3_valid " ";
CM_ SG_ 275 FR_Obj3_Track_Age " ";
CM_ SG_ 275 FR_Obj3_Track_ID " ";
CM_ SG_ 275 FR_Obj3_ObstacleProb " ";
CM_ SG_ 275 FR_Obj3_ExistProb " ";
CM_ SG_ 275 FR_Obj3_RelAx " ";
CM_ SG_ 275 FR_Obj3_RelAy " ";
CM_ SG_ 275 FR_Obj3_RelVx_std " ";
CM_ SG_ 275 FR_Obj3_RelVx " ";
CM_ SG_ 275 FR_Obj3_RelVy_std " ";
CM_ SG_ 275 FR_Obj3_RelVy " ";
CM_ SG_ 275 FR_Obj3_Dx_Vnce " ";
CM_ SG_ 275 FR_Obj3_Dx " ";
CM_ SG_ 275 FR_Obj3_Dy_Vnce " ";
CM_ SG_ 275 FR_Obj3_Dy " ";
CM_ SG_ 275 FR_Obj3_HeadingAngle " ";
CM_ SG_ 275 FR_Obj3_Length " ";
CM_ SG_ 275 FR_Obj3_Height " ";
CM_ SG_ 275 FR_Obj3_Width " ";
CM_ SG_ 275 FR_Obj3_TypeProb " ";
CM_ SG_ 275 FR_Obj3_Type " ";
CM_ BO_ 276 " ";
CM_ SG_ 276 FR_CRCCheck_114 " ";
CM_ SG_ 276 FR_RollingCounter_114 " ";
CM_ SG_ 276 FR_Obj4_Ax " ";
CM_ SG_ 276 FR_Obj4_Ay " ";
CM_ SG_ 276 FR_Obj4_Vx " ";
CM_ SG_ 276 FR_Obj4_Vy " ";
CM_ SG_ 276 FR_Obj4_DelayTime " ";
CM_ SG_ 276 FR_Obj4_ReferPoint_Dx " ";
CM_ SG_ 276 FR_Obj4_HeightGround "反射点最强点距离地面的高度 ";
CM_ SG_ 276 FR_Obj4_MotionStatusConf " ";
CM_ SG_ 276 FR_Obj4_MotionStatus " ";
CM_ SG_ 276 FR_Obj4_Measured " ";
CM_ SG_ 276 FR_Obj4_valid " ";
CM_ SG_ 276 FR_Obj4_Track_Age " ";
CM_ SG_ 276 FR_Obj4_Track_ID " ";
CM_ SG_ 276 FR_Obj4_ObstacleProb " ";
CM_ SG_ 276 FR_Obj4_ExistProb " ";
CM_ SG_ 276 FR_Obj4_RelAx " ";
CM_ SG_ 276 FR_Obj4_RelAy " ";
CM_ SG_ 276 FR_Obj4_RelVx_std " ";
CM_ SG_ 276 FR_Obj4_RelVx " ";
CM_ SG_ 276 FR_Obj4_RelVy_std " ";
CM_ SG_ 276 FR_Obj4_RelVy " ";
CM_ SG_ 276 FR_Obj4_Dx_Vnce " ";
CM_ SG_ 276 FR_Obj4_Dx " ";
CM_ SG_ 276 FR_Obj4_Dy_Vnce " ";
CM_ SG_ 276 FR_Obj4_Dy " ";
CM_ SG_ 276 FR_Obj4_HeadingAngle " ";
CM_ SG_ 276 FR_Obj4_Length " ";
CM_ SG_ 276 FR_Obj4_Height " ";
CM_ SG_ 276 FR_Obj4_Width " ";
CM_ SG_ 276 FR_Obj4_TypeProb " ";
CM_ SG_ 276 FR_Obj4_Type " ";
CM_ BO_ 277 " ";
CM_ SG_ 277 FR_CRCCheck_115 " ";
CM_ SG_ 277 FR_RollingCounter_115 " ";
CM_ SG_ 277 FR_Obj5_Ax " ";
CM_ SG_ 277 FR_Obj5_Ay " ";
CM_ SG_ 277 FR_Obj5_Vx " ";
CM_ SG_ 277 FR_Obj5_Vy " ";
CM_ SG_ 277 FR_Obj5_DelayTime " ";
CM_ SG_ 277 FR_Obj5_ReferPoint_Dx " ";
CM_ SG_ 277 FR_Obj5_HeightGround "反射点最强点距离地面的高度 ";
CM_ SG_ 277 FR_Obj5_MotionStatusConf " ";
CM_ SG_ 277 FR_Obj5_MotionStatus " ";
CM_ SG_ 277 FR_Obj5_Measured " ";
CM_ SG_ 277 FR_Obj5_valid " ";
CM_ SG_ 277 FR_Obj5_Track_Age " ";
CM_ SG_ 277 FR_Obj5_Track_ID " ";
CM_ SG_ 277 FR_Obj5_ObstacleProb " ";
CM_ SG_ 277 FR_Obj5_ExistProb " ";
CM_ SG_ 277 FR_Obj5_RelAx " ";
CM_ SG_ 277 FR_Obj5_RelAy " ";
CM_ SG_ 277 FR_Obj5_RelVx_std " ";
CM_ SG_ 277 FR_Obj5_RelVx " ";
CM_ SG_ 277 FR_Obj5_RelVy_std " ";
CM_ SG_ 277 FR_Obj5_RelVy " ";
CM_ SG_ 277 FR_Obj5_Dx_Vnce " ";
CM_ SG_ 277 FR_Obj5_Dx " ";
CM_ SG_ 277 FR_Obj5_Dy_Vnce " ";
CM_ SG_ 277 FR_Obj5_Dy " ";
CM_ SG_ 277 FR_Obj5_HeadingAngle " ";
CM_ SG_ 277 FR_Obj5_Length " ";
CM_ SG_ 277 FR_Obj5_Height " ";
CM_ SG_ 277 FR_Obj5_Width " ";
CM_ SG_ 277 FR_Obj5_TypeProb " ";
CM_ SG_ 277 FR_Obj5_Type " ";
CM_ BO_ 278 " ";
CM_ SG_ 278 FR_CRCCheck_116 " ";
CM_ SG_ 278 FR_RollingCounter_116 " ";
CM_ SG_ 278 FR_Obj6_Ax " ";
CM_ SG_ 278 FR_Obj6_Ay " ";
CM_ SG_ 278 FR_Obj6_Vx " ";
CM_ SG_ 278 FR_Obj6_Vy " ";
CM_ SG_ 278 FR_Obj6_DelayTime " ";
CM_ SG_ 278 FR_Obj6_ReferPoint_Dx " ";
CM_ SG_ 278 FR_Obj6_HeightGround "反射点最强点距离地面的高度 ";
CM_ SG_ 278 FR_Obj6_MotionStatusConf " ";
CM_ SG_ 278 FR_Obj6_MotionStatus " ";
CM_ SG_ 278 FR_Obj6_Measured " ";
CM_ SG_ 278 FR_Obj6_valid " ";
CM_ SG_ 278 FR_Obj6_Track_Age " ";
CM_ SG_ 278 FR_Obj6_Track_ID " ";
CM_ SG_ 278 FR_Obj6_ObstacleProb " ";
CM_ SG_ 278 FR_Obj6_ExistProb " ";
CM_ SG_ 278 FR_Obj6_RelAx " ";
CM_ SG_ 278 FR_Obj6_RelAy " ";
CM_ SG_ 278 FR_Obj6_RelVx_std " ";
CM_ SG_ 278 FR_Obj6_RelVx " ";
CM_ SG_ 278 FR_Obj6_RelVy_std " ";
CM_ SG_ 278 FR_Obj6_RelVy " ";
CM_ SG_ 278 FR_Obj6_Dx_Vnce " ";
CM_ SG_ 278 FR_Obj6_Dx " ";
CM_ SG_ 278 FR_Obj6_Dy_Vnce " ";
CM_ SG_ 278 FR_Obj6_Dy " ";
CM_ SG_ 278 FR_Obj6_HeadingAngle " ";
CM_ SG_ 278 FR_Obj6_Length " ";
CM_ SG_ 278 FR_Obj6_Height " ";
CM_ SG_ 278 FR_Obj6_Width " ";
CM_ SG_ 278 FR_Obj6_TypeProb " ";
CM_ SG_ 278 FR_Obj6_Type " ";
CM_ BO_ 279 " ";
CM_ SG_ 279 FR_CRCCheck_117 " ";
CM_ SG_ 279 FR_RollingCounter_117 " ";
CM_ SG_ 279 FR_Obj7_Ax " ";
CM_ SG_ 279 FR_Obj7_Ay " ";
CM_ SG_ 279 FR_Obj7_Vx " ";
CM_ SG_ 279 FR_Obj7_Vy " ";
CM_ SG_ 279 FR_Obj7_DelayTime " ";
CM_ SG_ 279 FR_Obj7_ReferPoint_Dx " ";
CM_ SG_ 279 FR_Obj7_HeightGround "反射点最强点距离地面的高度 ";
CM_ SG_ 279 FR_Obj7_MotionStatusConf " ";
CM_ SG_ 279 FR_Obj7_MotionStatus " ";
CM_ SG_ 279 FR_Obj7_Measured " ";
CM_ SG_ 279 FR_Obj7_valid " ";
CM_ SG_ 279 FR_Obj7_Track_Age " ";
CM_ SG_ 279 FR_Obj7_Track_ID " ";
CM_ SG_ 279 FR_Obj7_ObstacleProb " ";
CM_ SG_ 279 FR_Obj7_ExistProb " ";
CM_ SG_ 279 FR_Obj7_RelAx " ";
CM_ SG_ 279 FR_Obj7_RelAy " ";
CM_ SG_ 279 FR_Obj7_RelVx_std " ";
CM_ SG_ 279 FR_Obj7_RelVx " ";
CM_ SG_ 279 FR_Obj7_RelVy_std " ";
CM_ SG_ 279 FR_Obj7_RelVy " ";
CM_ SG_ 279 FR_Obj7_Dx_Vnce " ";
CM_ SG_ 279 FR_Obj7_Dx " ";
CM_ SG_ 279 FR_Obj7_Dy_Vnce " ";
CM_ SG_ 279 FR_Obj7_Dy " ";
CM_ SG_ 279 FR_Obj7_HeadingAngle " ";
CM_ SG_ 279 FR_Obj7_Length " ";
CM_ SG_ 279 FR_Obj7_Height " ";
CM_ SG_ 279 FR_Obj7_Width " ";
CM_ SG_ 279 FR_Obj7_TypeProb " ";
CM_ SG_ 279 FR_Obj7_Type " ";
CM_ BO_ 280 " ";
CM_ SG_ 280 FR_CRCCheck_118 " ";
CM_ SG_ 280 FR_RollingCounter_118 " ";
CM_ SG_ 280 FR_Obj8_Ax " ";
CM_ SG_ 280 FR_Obj8_Ay " ";
CM_ SG_ 280 FR_Obj8_Vx " ";
CM_ SG_ 280 FR_Obj8_Vy " ";
CM_ SG_ 280 FR_Obj8_DelayTime " ";
CM_ SG_ 280 FR_Obj8_ReferPoint_Dx " ";
CM_ SG_ 280 FR_Obj8_HeightGround "反射点最强点距离地面的高度 ";
CM_ SG_ 280 FR_Obj8_MotionStatusConf " ";
CM_ SG_ 280 FR_Obj8_MotionStatus " ";
CM_ SG_ 280 FR_Obj8_Measured " ";
CM_ SG_ 280 FR_Obj8_valid " ";
CM_ SG_ 280 FR_Obj8_Track_Age " ";
CM_ SG_ 280 FR_Obj8_Track_ID " ";
CM_ SG_ 280 FR_Obj8_ObstacleProb " ";
CM_ SG_ 280 FR_Obj8_ExistProb " ";
CM_ SG_ 280 FR_Obj8_RelAx " ";
CM_ SG_ 280 FR_Obj8_RelAy " ";
CM_ SG_ 280 FR_Obj8_RelVx_std " ";
CM_ SG_ 280 FR_Obj8_RelVx " ";
CM_ SG_ 280 FR_Obj8_RelVy_std " ";
CM_ SG_ 280 FR_Obj8_RelVy " ";
CM_ SG_ 280 FR_Obj8_Dx_Vnce " ";
CM_ SG_ 280 FR_Obj8_Dx " ";
CM_ SG_ 280 FR_Obj8_Dy_Vnce " ";
CM_ SG_ 280 FR_Obj8_Dy " ";
CM_ SG_ 280 FR_Obj8_HeadingAngle " ";
CM_ SG_ 280 FR_Obj8_Length " ";
CM_ SG_ 280 FR_Obj8_Height " ";
CM_ SG_ 280 FR_Obj8_Width " ";
CM_ SG_ 280 FR_Obj8_TypeProb " ";
CM_ SG_ 280 FR_Obj8_Type " ";
CM_ BO_ 281 " ";
CM_ SG_ 281 FR_CRCCheck_119 " ";
CM_ SG_ 281 FR_RollingCounter_119 " ";
CM_ SG_ 281 FR_Obj9_Ax " ";
CM_ SG_ 281 FR_Obj9_Ay " ";
CM_ SG_ 281 FR_Obj9_Vx " ";
CM_ SG_ 281 FR_Obj9_Vy " ";
CM_ SG_ 281 FR_Obj9_DelayTime " ";
CM_ SG_ 281 FR_Obj9_ReferPoint_Dx " ";
CM_ SG_ 281 FR_Obj9_HeightGround "反射点最强点距离地面的高度 ";
CM_ SG_ 281 FR_Obj9_MotionStatusConf " ";
CM_ SG_ 281 FR_Obj9_MotionStatus " ";
CM_ SG_ 281 FR_Obj9_Measured " ";
CM_ SG_ 281 FR_Obj9_valid " ";
CM_ SG_ 281 FR_Obj9_Track_Age " ";
CM_ SG_ 281 FR_Obj9_Track_ID " ";
CM_ SG_ 281 FR_Obj9_ObstacleProb " ";
CM_ SG_ 281 FR_Obj9_ExistProb " ";
CM_ SG_ 281 FR_Obj9_RelAx " ";
CM_ SG_ 281 FR_Obj9_RelAy " ";
CM_ SG_ 281 FR_Obj9_RelVx_std " ";
CM_ SG_ 281 FR_Obj9_RelVx " ";
CM_ SG_ 281 FR_Obj9_RelVy_std " ";
CM_ SG_ 281 FR_Obj9_RelVy " ";
CM_ SG_ 281 FR_Obj9_Dx_Vnce " ";
CM_ SG_ 281 FR_Obj9_Dx " ";
CM_ SG_ 281 FR_Obj9_Dy_Vnce " ";
CM_ SG_ 281 FR_Obj9_Dy " ";
CM_ SG_ 281 FR_Obj9_HeadingAngle " ";
CM_ SG_ 281 FR_Obj9_Length " ";
CM_ SG_ 281 FR_Obj9_Height " ";
CM_ SG_ 281 FR_Obj9_Width " ";
CM_ SG_ 281 FR_Obj9_TypeProb " ";
CM_ SG_ 281 FR_Obj9_Type " ";
CM_ BO_ 288 " ";
CM_ SG_ 288 FR_CRCCheck_120 " ";
CM_ SG_ 288 FR_RollingCounter_120 " ";
CM_ SG_ 288 FR_Obj10_Ax " ";
CM_ SG_ 288 FR_Obj10_Ay " ";
CM_ SG_ 288 FR_Obj10_Vx " ";
CM_ SG_ 288 FR_Obj10_Vy " ";
CM_ SG_ 288 FR_Obj10_DelayTime " ";
CM_ SG_ 288 FR_Obj10_ReferPoint_Dx " ";
CM_ SG_ 288 FR_Obj10_HeightGround "反射点最强点距离地面的高度 ";
CM_ SG_ 288 FR_Obj10_MotionStatusConf " ";
CM_ SG_ 288 FR_Obj10_MotionStatus " ";
CM_ SG_ 288 FR_Obj10_Measured " ";
CM_ SG_ 288 FR_Obj10_valid " ";
CM_ SG_ 288 FR_Obj10_Track_Age " ";
CM_ SG_ 288 FR_Obj10_Track_ID " ";
CM_ SG_ 288 FR_Obj10_ObstacleProb " ";
CM_ SG_ 288 FR_Obj10_ExistProb " ";
CM_ SG_ 288 FR_Obj10_RelAx " ";
CM_ SG_ 288 FR_Obj10_RelAy " ";
CM_ SG_ 288 FR_Obj10_RelVx_std " ";
CM_ SG_ 288 FR_Obj10_RelVx " ";
CM_ SG_ 288 FR_Obj10_RelVy_std " ";
CM_ SG_ 288 FR_Obj10_RelVy " ";
CM_ SG_ 288 FR_Obj10_Dx_Vnce " ";
CM_ SG_ 288 FR_Obj10_Dx " ";
CM_ SG_ 288 FR_Obj10_Dy_Vnce " ";
CM_ SG_ 288 FR_Obj10_Dy " ";
CM_ SG_ 288 FR_Obj10_HeadingAngle " ";
CM_ SG_ 288 FR_Obj10_Length " ";
CM_ SG_ 288 FR_Obj10_Height " ";
CM_ SG_ 288 FR_Obj10_Width " ";
CM_ SG_ 288 FR_Obj10_TypeProb " ";
CM_ SG_ 288 FR_Obj10_Type " ";
CM_ BO_ 289 " ";
CM_ SG_ 289 FR_CRCCheck_121 " ";
CM_ SG_ 289 FR_RollingCounter_121 " ";
CM_ SG_ 289 FR_Obj11_Ax " ";
CM_ SG_ 289 FR_Obj11_Ay " ";
CM_ SG_ 289 FR_Obj11_Vx " ";
CM_ SG_ 289 FR_Obj11_Vy " ";
CM_ SG_ 289 FR_Obj11_DelayTime " ";
CM_ SG_ 289 FR_Obj11_ReferPoint_Dx " ";
CM_ SG_ 289 FR_Obj11_HeightGround "反射点最强点距离地面的高度 ";
CM_ SG_ 289 FR_Obj11_MotionStatusConf " ";
CM_ SG_ 289 FR_Obj11_MotionStatus " ";
CM_ SG_ 289 FR_Obj11_Measured " ";
CM_ SG_ 289 FR_Obj11_valid " ";
CM_ SG_ 289 FR_Obj11_Track_Age " ";
CM_ SG_ 289 FR_Obj11_Track_ID " ";
CM_ SG_ 289 FR_Obj11_ObstacleProb " ";
CM_ SG_ 289 FR_Obj11_ExistProb " ";
CM_ SG_ 289 FR_Obj11_RelAx " ";
CM_ SG_ 289 FR_Obj11_RelAy " ";
CM_ SG_ 289 FR_Obj11_RelVx_std " ";
CM_ SG_ 289 FR_Obj11_RelVx " ";
CM_ SG_ 289 FR_Obj11_RelVy_std " ";
CM_ SG_ 289 FR_Obj11_RelVy " ";
CM_ SG_ 289 FR_Obj11_Dx_Vnce " ";
CM_ SG_ 289 FR_Obj11_Dx " ";
CM_ SG_ 289 FR_Obj11_Dy_Vnce " ";
CM_ SG_ 289 FR_Obj11_Dy " ";
CM_ SG_ 289 FR_Obj11_HeadingAngle " ";
CM_ SG_ 289 FR_Obj11_Length " ";
CM_ SG_ 289 FR_Obj11_Height " ";
CM_ SG_ 289 FR_Obj11_Width " ";
CM_ SG_ 289 FR_Obj11_TypeProb " ";
CM_ SG_ 289 FR_Obj11_Type " ";
CM_ BO_ 290 " ";
CM_ SG_ 290 FR_CRCCheck_122 " ";
CM_ SG_ 290 FR_RollingCounter_122 " ";
CM_ SG_ 290 FR_Obj12_Ax " ";
CM_ SG_ 290 FR_Obj12_Ay " ";
CM_ SG_ 290 FR_Obj12_Vx " ";
CM_ SG_ 290 FR_Obj12_Vy " ";
CM_ SG_ 290 FR_Obj12_DelayTime " ";
CM_ SG_ 290 FR_Obj12_ReferPoint_Dx " ";
CM_ SG_ 290 FR_Obj12_HeightGround "反射点最强点距离地面的高度 ";
CM_ SG_ 290 FR_Obj12_MotionStatusConf " ";
CM_ SG_ 290 FR_Obj12_MotionStatus " ";
CM_ SG_ 290 FR_Obj12_Measured " ";
CM_ SG_ 290 FR_Obj12_valid " ";
CM_ SG_ 290 FR_Obj12_Track_Age " ";
CM_ SG_ 290 FR_Obj12_Track_ID " ";
CM_ SG_ 290 FR_Obj12_ObstacleProb " ";
CM_ SG_ 290 FR_Obj12_ExistProb " ";
CM_ SG_ 290 FR_Obj12_RelAx " ";
CM_ SG_ 290 FR_Obj12_RelAy " ";
CM_ SG_ 290 FR_Obj12_RelVx_std " ";
CM_ SG_ 290 FR_Obj12_RelVx " ";
CM_ SG_ 290 FR_Obj12_RelVy_std " ";
CM_ SG_ 290 FR_Obj12_RelVy " ";
CM_ SG_ 290 FR_Obj12_Dx_Vnce " ";
CM_ SG_ 290 FR_Obj12_Dx " ";
CM_ SG_ 290 FR_Obj12_Dy_Vnce " ";
CM_ SG_ 290 FR_Obj12_Dy " ";
CM_ SG_ 290 FR_Obj12_HeadingAngle " ";
CM_ SG_ 290 FR_Obj12_Length " ";
CM_ SG_ 290 FR_Obj12_Height " ";
CM_ SG_ 290 FR_Obj12_Width " ";
CM_ SG_ 290 FR_Obj12_TypeProb " ";
CM_ SG_ 290 FR_Obj12_Type " ";
CM_ BO_ 292 " ";
CM_ SG_ 292 FR_CRCCheck_124 " ";
CM_ SG_ 292 FR_RollingCounter_124 " ";
CM_ SG_ 292 FR_Obj14_Ax " ";
CM_ SG_ 292 FR_Obj14_Ay " ";
CM_ SG_ 292 FR_Obj14_Vx " ";
CM_ SG_ 292 FR_Obj14_Vy " ";
CM_ SG_ 292 FR_Obj14_DelayTime " ";
CM_ SG_ 292 FR_Obj14_ReferPoint_Dx " ";
CM_ SG_ 292 FR_Obj14_HeightGround "反射点最强点距离地面的高度 ";
CM_ SG_ 292 FR_Obj14_MotionStatusConf " ";
CM_ SG_ 292 FR_Obj14_MotionStatus " ";
CM_ SG_ 292 FR_Obj14_Measured " ";
CM_ SG_ 292 FR_Obj14_valid " ";
CM_ SG_ 292 FR_Obj14_Track_Age " ";
CM_ SG_ 292 FR_Obj14_Track_ID " ";
CM_ SG_ 292 FR_Obj14_ObstacleProb " ";
CM_ SG_ 292 FR_Obj14_ExistProb " ";
CM_ SG_ 292 FR_Obj14_RelAx " ";
CM_ SG_ 292 FR_Obj14_RelAy " ";
CM_ SG_ 292 FR_Obj14_RelVx_std " ";
CM_ SG_ 292 FR_Obj14_RelVx " ";
CM_ SG_ 292 FR_Obj14_RelVy_std " ";
CM_ SG_ 292 FR_Obj14_RelVy " ";
CM_ SG_ 292 FR_Obj14_Dx_Vnce " ";
CM_ SG_ 292 FR_Obj14_Dx " ";
CM_ SG_ 292 FR_Obj14_Dy_Vnce " ";
CM_ SG_ 292 FR_Obj14_Dy " ";
CM_ SG_ 292 FR_Obj14_HeadingAngle " ";
CM_ SG_ 292 FR_Obj14_Length " ";
CM_ SG_ 292 FR_Obj14_Height " ";
CM_ SG_ 292 FR_Obj14_Width " ";
CM_ SG_ 292 FR_Obj14_TypeProb " ";
CM_ SG_ 292 FR_Obj14_Type " ";
CM_ BO_ 293 " ";
CM_ SG_ 293 FR_CRCCheck_125 " ";
CM_ SG_ 293 FR_RollingCounter_125 " ";
CM_ SG_ 293 FR_Obj15_Ax " ";
CM_ SG_ 293 FR_Obj15_Ay " ";
CM_ SG_ 293 FR_Obj15_Vx " ";
CM_ SG_ 293 FR_Obj15_Vy " ";
CM_ SG_ 293 FR_Obj15_DelayTime " ";
CM_ SG_ 293 FR_Obj15_ReferPoint_Dx " ";
CM_ SG_ 293 FR_Obj15_HeightGround "反射点最强点距离地面的高度 ";
CM_ SG_ 293 FR_Obj15_MotionStatusConf " ";
CM_ SG_ 293 FR_Obj15_MotionStatus " ";
CM_ SG_ 293 FR_Obj15_Measured " ";
CM_ SG_ 293 FR_Obj15_valid " ";
CM_ SG_ 293 FR_Obj15_Track_Age " ";
CM_ SG_ 293 FR_Obj15_Track_ID " ";
CM_ SG_ 293 FR_Obj15_ObstacleProb " ";
CM_ SG_ 293 FR_Obj15_ExistProb " ";
CM_ SG_ 293 FR_Obj15_RelAx " ";
CM_ SG_ 293 FR_Obj15_RelAy " ";
CM_ SG_ 293 FR_Obj15_RelVx_std " ";
CM_ SG_ 293 FR_Obj15_RelVx " ";
CM_ SG_ 293 FR_Obj15_RelVy_std " ";
CM_ SG_ 293 FR_Obj15_RelVy " ";
CM_ SG_ 293 FR_Obj15_Dx_Vnce " ";
CM_ SG_ 293 FR_Obj15_Dx " ";
CM_ SG_ 293 FR_Obj15_Dy_Vnce " ";
CM_ SG_ 293 FR_Obj15_Dy " ";
CM_ SG_ 293 FR_Obj15_HeadingAngle " ";
CM_ SG_ 293 FR_Obj15_Length " ";
CM_ SG_ 293 FR_Obj15_Height " ";
CM_ SG_ 293 FR_Obj15_Width " ";
CM_ SG_ 293 FR_Obj15_TypeProb " ";
CM_ SG_ 293 FR_Obj15_Type " ";
CM_ BO_ 294 " ";
CM_ SG_ 294 FR_CRCCheck_126 " ";
CM_ SG_ 294 FR_RollingCounter_126 " ";
CM_ SG_ 294 FR_Obj16_Ax " ";
CM_ SG_ 294 FR_Obj16_Ay " ";
CM_ SG_ 294 FR_Obj16_Vx " ";
CM_ SG_ 294 FR_Obj16_Vy " ";
CM_ SG_ 294 FR_Obj16_DelayTime " ";
CM_ SG_ 294 FR_Obj16_ReferPoint_Dx " ";
CM_ SG_ 294 FR_Obj16_HeightGround "反射点最强点距离地面的高度 ";
CM_ SG_ 294 FR_Obj16_MotionStatusConf " ";
CM_ SG_ 294 FR_Obj16_MotionStatus " ";
CM_ SG_ 294 FR_Obj16_Measured " ";
CM_ SG_ 294 FR_Obj16_valid " ";
CM_ SG_ 294 FR_Obj16_Track_Age " ";
CM_ SG_ 294 FR_Obj16_Track_ID " ";
CM_ SG_ 294 FR_Obj16_ObstacleProb " ";
CM_ SG_ 294 FR_Obj16_ExistProb " ";
CM_ SG_ 294 FR_Obj16_RelAx " ";
CM_ SG_ 294 FR_Obj16_RelAy " ";
CM_ SG_ 294 FR_Obj16_RelVx_std " ";
CM_ SG_ 294 FR_Obj16_RelVx " ";
CM_ SG_ 294 FR_Obj16_RelVy_std " ";
CM_ SG_ 294 FR_Obj16_RelVy " ";
CM_ SG_ 294 FR_Obj16_Dx_Vnce " ";
CM_ SG_ 294 FR_Obj16_Dx " ";
CM_ SG_ 294 FR_Obj16_Dy_Vnce " ";
CM_ SG_ 294 FR_Obj16_Dy " ";
CM_ SG_ 294 FR_Obj16_HeadingAngle " ";
CM_ SG_ 294 FR_Obj16_Length " ";
CM_ SG_ 294 FR_Obj16_Height " ";
CM_ SG_ 294 FR_Obj16_Width " ";
CM_ SG_ 294 FR_Obj16_TypeProb " ";
CM_ SG_ 294 FR_Obj16_Type " ";
CM_ BO_ 295 " ";
CM_ SG_ 295 FR_CRCCheck_127 " ";
CM_ SG_ 295 FR_RollingCounter_127 " ";
CM_ SG_ 295 FR_Obj17_Ax " ";
CM_ SG_ 295 FR_Obj17_Ay " ";
CM_ SG_ 295 FR_Obj17_Vx " ";
CM_ SG_ 295 FR_Obj17_Vy " ";
CM_ SG_ 295 FR_Obj17_DelayTime " ";
CM_ SG_ 295 FR_Obj17_ReferPoint_Dx " ";
CM_ SG_ 295 FR_Obj17_HeightGround "反射点最强点距离地面的高度 ";
CM_ SG_ 295 FR_Obj17_MotionStatusConf " ";
CM_ SG_ 295 FR_Obj17_MotionStatus " ";
CM_ SG_ 295 FR_Obj17_Measured " ";
CM_ SG_ 295 FR_Obj17_valid " ";
CM_ SG_ 295 FR_Obj17_Track_Age " ";
CM_ SG_ 295 FR_Obj17_Track_ID " ";
CM_ SG_ 295 FR_Obj17_ObstacleProb " ";
CM_ SG_ 295 FR_Obj17_ExistProb " ";
CM_ SG_ 295 FR_Obj17_RelAx " ";
CM_ SG_ 295 FR_Obj17_RelAy " ";
CM_ SG_ 295 FR_Obj17_RelVx_std " ";
CM_ SG_ 295 FR_Obj17_RelVx " ";
CM_ SG_ 295 FR_Obj17_RelVy_std " ";
CM_ SG_ 295 FR_Obj17_RelVy " ";
CM_ SG_ 295 FR_Obj17_Dx_Vnce " ";
CM_ SG_ 295 FR_Obj17_Dx " ";
CM_ SG_ 295 FR_Obj17_Dy_Vnce " ";
CM_ SG_ 295 FR_Obj17_Dy " ";
CM_ SG_ 295 FR_Obj17_HeadingAngle " ";
CM_ SG_ 295 FR_Obj17_Length " ";
CM_ SG_ 295 FR_Obj17_Height " ";
CM_ SG_ 295 FR_Obj17_Width " ";
CM_ SG_ 295 FR_Obj17_TypeProb " ";
CM_ SG_ 295 FR_Obj17_Type " ";
CM_ BO_ 296 " ";
CM_ SG_ 296 FR_CRCCheck_128 " ";
CM_ SG_ 296 FR_RollingCounter_128 " ";
CM_ SG_ 296 FR_Obj18_Ax " ";
CM_ SG_ 296 FR_Obj18_Ay " ";
CM_ SG_ 296 FR_Obj18_Vx " ";
CM_ SG_ 296 FR_Obj18_Vy " ";
CM_ SG_ 296 FR_Obj18_DelayTime " ";
CM_ SG_ 296 FR_Obj18_ReferPoint_Dx " ";
CM_ SG_ 296 FR_Obj18_HeightGround "反射点最强点距离地面的高度 ";
CM_ SG_ 296 FR_Obj18_MotionStatusConf " ";
CM_ SG_ 296 FR_Obj18_MotionStatus " ";
CM_ SG_ 296 FR_Obj18_Measured " ";
CM_ SG_ 296 FR_Obj18_valid " ";
CM_ SG_ 296 FR_Obj18_Track_Age " ";
CM_ SG_ 296 FR_Obj18_Track_ID " ";
CM_ SG_ 296 FR_Obj18_ObstacleProb " ";
CM_ SG_ 296 FR_Obj18_ExistProb " ";
CM_ SG_ 296 FR_Obj18_RelAx " ";
CM_ SG_ 296 FR_Obj18_RelAy " ";
CM_ SG_ 296 FR_Obj18_RelVx_std " ";
CM_ SG_ 296 FR_Obj18_RelVx " ";
CM_ SG_ 296 FR_Obj18_RelVy_std " ";
CM_ SG_ 296 FR_Obj18_RelVy " ";
CM_ SG_ 296 FR_Obj18_Dx_Vnce " ";
CM_ SG_ 296 FR_Obj18_Dx " ";
CM_ SG_ 296 FR_Obj18_Dy_Vnce " ";
CM_ SG_ 296 FR_Obj18_Dy " ";
CM_ SG_ 296 FR_Obj18_HeadingAngle " ";
CM_ SG_ 296 FR_Obj18_Length " ";
CM_ SG_ 296 FR_Obj18_Height " ";
CM_ SG_ 296 FR_Obj18_Width " ";
CM_ SG_ 296 FR_Obj18_TypeProb " ";
CM_ SG_ 296 FR_Obj18_Type " ";
CM_ BO_ 297 " ";
CM_ SG_ 297 FR_CRCCheck_129 " ";
CM_ SG_ 297 FR_RollingCounter_129 " ";
CM_ SG_ 297 FR_Obj19_Ax " ";
CM_ SG_ 297 FR_Obj19_Ay " ";
CM_ SG_ 297 FR_Obj19_Vx " ";
CM_ SG_ 297 FR_Obj19_Vy " ";
CM_ SG_ 297 FR_Obj19_DelayTime " ";
CM_ SG_ 297 FR_Obj19_ReferPoint_Dx " ";
CM_ SG_ 297 FR_Obj19_HeightGround "反射点最强点距离地面的高度 ";
CM_ SG_ 297 FR_Obj19_MotionStatusConf " ";
CM_ SG_ 297 FR_Obj19_MotionStatus " ";
CM_ SG_ 297 FR_Obj19_Measured " ";
CM_ SG_ 297 FR_Obj19_valid " ";
CM_ SG_ 297 FR_Obj19_Track_Age " ";
CM_ SG_ 297 FR_Obj19_Track_ID " ";
CM_ SG_ 297 FR_Obj19_ObstacleProb " ";
CM_ SG_ 297 FR_Obj19_ExistProb " ";
CM_ SG_ 297 FR_Obj19_RelAx " ";
CM_ SG_ 297 FR_Obj19_RelAy " ";
CM_ SG_ 297 FR_Obj19_RelVx_std " ";
CM_ SG_ 297 FR_Obj19_RelVx " ";
CM_ SG_ 297 FR_Obj19_RelVy_std " ";
CM_ SG_ 297 FR_Obj19_RelVy " ";
CM_ SG_ 297 FR_Obj19_Dx_Vnce " ";
CM_ SG_ 297 FR_Obj19_Dx " ";
CM_ SG_ 297 FR_Obj19_Dy_Vnce " ";
CM_ SG_ 297 FR_Obj19_Dy " ";
CM_ SG_ 297 FR_Obj19_HeadingAngle " ";
CM_ SG_ 297 FR_Obj19_Length " ";
CM_ SG_ 297 FR_Obj19_Height " ";
CM_ SG_ 297 FR_Obj19_Width " ";
CM_ SG_ 297 FR_Obj19_TypeProb " ";
CM_ SG_ 297 FR_Obj19_Type " ";
CM_ BO_ 298 " ";
CM_ SG_ 298 FR_CRCCheck_12A " ";
CM_ SG_ 298 FR_RollingCounter_12A " ";
CM_ SG_ 298 FR_Obj13_Ax " ";
CM_ SG_ 298 FR_Obj13_Ay " ";
CM_ SG_ 298 FR_Obj13_Vx " ";
CM_ SG_ 298 FR_Obj13_Vy " ";
CM_ SG_ 298 FR_Obj13_DelayTime " ";
CM_ SG_ 298 FR_Obj13_ReferPoint_Dx " ";
CM_ SG_ 298 FR_Obj13_HeightGround "反射点最强点距离地面的高度 ";
CM_ SG_ 298 FR_Obj13_MotionStatusConf " ";
CM_ SG_ 298 FR_Obj13_MotionStatus " ";
CM_ SG_ 298 FR_Obj13_Measured " ";
CM_ SG_ 298 FR_Obj13_valid " ";
CM_ SG_ 298 FR_Obj13_Track_Age " ";
CM_ SG_ 298 FR_Obj13_Track_ID " ";
CM_ SG_ 298 FR_Obj13_ObstacleProb " ";
CM_ SG_ 298 FR_Obj13_ExistProb " ";
CM_ SG_ 298 FR_Obj13_RelAx " ";
CM_ SG_ 298 FR_Obj13_RelAy " ";
CM_ SG_ 298 FR_Obj13_RelVx_std " ";
CM_ SG_ 298 FR_Obj13_RelVx " ";
CM_ SG_ 298 FR_Obj13_RelVy_std " ";
CM_ SG_ 298 FR_Obj13_RelVy " ";
CM_ SG_ 298 FR_Obj13_Dx_Vnce " ";
CM_ SG_ 298 FR_Obj13_Dx " ";
CM_ SG_ 298 FR_Obj13_Dy_Vnce " ";
CM_ SG_ 298 FR_Obj13_Dy " ";
CM_ SG_ 298 FR_Obj13_HeadingAngle " ";
CM_ SG_ 298 FR_Obj13_Length " ";
CM_ SG_ 298 FR_Obj13_Height " ";
CM_ SG_ 298 FR_Obj13_Width " ";
CM_ SG_ 298 FR_Obj13_TypeProb " ";
CM_ SG_ 298 FR_Obj13_Type " ";
CM_ BO_ 299 " ";
CM_ SG_ 299 FR_CRCCheck_12B " ";
CM_ SG_ 299 FR_RollingCounter_12B " ";
CM_ SG_ 299 FR_Obj20_Ax " ";
CM_ SG_ 299 FR_Obj20_Ay " ";
CM_ SG_ 299 FR_Obj20_Vx " ";
CM_ SG_ 299 FR_Obj20_Vy " ";
CM_ SG_ 299 FR_Obj20_DelayTime " ";
CM_ SG_ 299 FR_Obj20_ReferPoint_Dx " ";
CM_ SG_ 299 FR_Obj20_HeightGround "反射点最强点距离地面的高度 ";
CM_ SG_ 299 FR_Obj20_MotionStatusConf " ";
CM_ SG_ 299 FR_Obj20_MotionStatus " ";
CM_ SG_ 299 FR_Obj20_Measured " ";
CM_ SG_ 299 FR_Obj20_valid " ";
CM_ SG_ 299 FR_Obj20_Track_Age " ";
CM_ SG_ 299 FR_Obj20_Track_ID " ";
CM_ SG_ 299 FR_Obj20_ObstacleProb " ";
CM_ SG_ 299 FR_Obj20_ExistProb " ";
CM_ SG_ 299 FR_Obj20_RelAx " ";
CM_ SG_ 299 FR_Obj20_RelAy " ";
CM_ SG_ 299 FR_Obj20_RelVx_std " ";
CM_ SG_ 299 FR_Obj20_RelVx " ";
CM_ SG_ 299 FR_Obj20_RelVy_std " ";
CM_ SG_ 299 FR_Obj20_RelVy " ";
CM_ SG_ 299 FR_Obj20_Dx_Vnce " ";
CM_ SG_ 299 FR_Obj20_Dx " ";
CM_ SG_ 299 FR_Obj20_Dy_Vnce " ";
CM_ SG_ 299 FR_Obj20_Dy " ";
CM_ SG_ 299 FR_Obj20_HeadingAngle " ";
CM_ SG_ 299 FR_Obj20_Length " ";
CM_ SG_ 299 FR_Obj20_Height " ";
CM_ SG_ 299 FR_Obj20_Width " ";
CM_ SG_ 299 FR_Obj20_TypeProb " ";
CM_ SG_ 299 FR_Obj20_Type " ";
CM_ BO_ 300 " ";
CM_ SG_ 300 FR_CRCCheck_12C " ";
CM_ SG_ 300 FR_RollingCounter_12C " ";
CM_ SG_ 300 FR_Obj21_Ax " ";
CM_ SG_ 300 FR_Obj21_Ay " ";
CM_ SG_ 300 FR_Obj21_Vx " ";
CM_ SG_ 300 FR_Obj21_Vy " ";
CM_ SG_ 300 FR_Obj21_DelayTime " ";
CM_ SG_ 300 FR_Obj21_ReferPoint_Dx " ";
CM_ SG_ 300 FR_Obj21_HeightGround "反射点最强点距离地面的高度 ";
CM_ SG_ 300 FR_Obj21_MotionStatusConf " ";
CM_ SG_ 300 FR_Obj21_MotionStatus " ";
CM_ SG_ 300 FR_Obj21_Measured " ";
CM_ SG_ 300 FR_Obj21_valid " ";
CM_ SG_ 300 FR_Obj21_Track_Age " ";
CM_ SG_ 300 FR_Obj21_Track_ID " ";
CM_ SG_ 300 FR_Obj21_ObstacleProb " ";
CM_ SG_ 300 FR_Obj21_ExistProb " ";
CM_ SG_ 300 FR_Obj21_RelAx " ";
CM_ SG_ 300 FR_Obj21_RelAy " ";
CM_ SG_ 300 FR_Obj21_RelVx_std " ";
CM_ SG_ 300 FR_Obj21_RelVx " ";
CM_ SG_ 300 FR_Obj21_RelVy_std " ";
CM_ SG_ 300 FR_Obj21_RelVy " ";
CM_ SG_ 300 FR_Obj21_Dx_Vnce " ";
CM_ SG_ 300 FR_Obj21_Dx " ";
CM_ SG_ 300 FR_Obj21_Dy_Vnce " ";
CM_ SG_ 300 FR_Obj21_Dy " ";
CM_ SG_ 300 FR_Obj21_HeadingAngle " ";
CM_ SG_ 300 FR_Obj21_Length " ";
CM_ SG_ 300 FR_Obj21_Height " ";
CM_ SG_ 300 FR_Obj21_Width " ";
CM_ SG_ 300 FR_Obj21_TypeProb " ";
CM_ SG_ 300 FR_Obj21_Type " ";
CM_ BO_ 301 " ";
CM_ SG_ 301 FR_CRCCheck_12D " ";
CM_ SG_ 301 FR_RollingCounter_12D " ";
CM_ SG_ 301 FR_Obj22_Ax " ";
CM_ SG_ 301 FR_Obj22_Ay " ";
CM_ SG_ 301 FR_Obj22_Vx " ";
CM_ SG_ 301 FR_Obj22_Vy " ";
CM_ SG_ 301 FR_Obj22_DelayTime " ";
CM_ SG_ 301 FR_Obj22_ReferPoint_Dx " ";
CM_ SG_ 301 FR_Obj22_HeightGround "反射点最强点距离地面的高度 ";
CM_ SG_ 301 FR_Obj22_MotionStatusConf " ";
CM_ SG_ 301 FR_Obj22_MotionStatus " ";
CM_ SG_ 301 FR_Obj22_Measured " ";
CM_ SG_ 301 FR_Obj22_valid " ";
CM_ SG_ 301 FR_Obj22_Track_Age " ";
CM_ SG_ 301 FR_Obj22_Track_ID " ";
CM_ SG_ 301 FR_Obj22_ObstacleProb " ";
CM_ SG_ 301 FR_Obj22_ExistProb " ";
CM_ SG_ 301 FR_Obj22_RelAx " ";
CM_ SG_ 301 FR_Obj22_RelAy " ";
CM_ SG_ 301 FR_Obj22_RelVx_std " ";
CM_ SG_ 301 FR_Obj22_RelVx " ";
CM_ SG_ 301 FR_Obj22_RelVy_std " ";
CM_ SG_ 301 FR_Obj22_RelVy " ";
CM_ SG_ 301 FR_Obj22_Dx_Vnce " ";
CM_ SG_ 301 FR_Obj22_Dx " ";
CM_ SG_ 301 FR_Obj22_Dy_Vnce " ";
CM_ SG_ 301 FR_Obj22_Dy " ";
CM_ SG_ 301 FR_Obj22_HeadingAngle " ";
CM_ SG_ 301 FR_Obj22_Length " ";
CM_ SG_ 301 FR_Obj22_Height " ";
CM_ SG_ 301 FR_Obj22_Width " ";
CM_ SG_ 301 FR_Obj22_TypeProb " ";
CM_ SG_ 301 FR_Obj22_Type " ";
CM_ BO_ 302 " ";
CM_ SG_ 302 FR_CRCCheck_12E " ";
CM_ SG_ 302 FR_RollingCounter_12E " ";
CM_ SG_ 302 FR_Obj23_Ax " ";
CM_ SG_ 302 FR_Obj23_Ay " ";
CM_ SG_ 302 FR_Obj23_Vx " ";
CM_ SG_ 302 FR_Obj23_Vy " ";
CM_ SG_ 302 FR_Obj23_DelayTime " ";
CM_ SG_ 302 FR_Obj23_ReferPoint_Dx " ";
CM_ SG_ 302 FR_Obj23_HeightGround "反射点最强点距离地面的高度 ";
CM_ SG_ 302 FR_Obj23_MotionStatusConf " ";
CM_ SG_ 302 FR_Obj23_MotionStatus " ";
CM_ SG_ 302 FR_Obj23_Measured " ";
CM_ SG_ 302 FR_Obj23_valid " ";
CM_ SG_ 302 FR_Obj23_Track_Age " ";
CM_ SG_ 302 FR_Obj23_Track_ID " ";
CM_ SG_ 302 FR_Obj23_ObstacleProb " ";
CM_ SG_ 302 FR_Obj23_ExistProb " ";
CM_ SG_ 302 FR_Obj23_RelAx " ";
CM_ SG_ 302 FR_Obj23_RelAy " ";
CM_ SG_ 302 FR_Obj23_RelVx_std " ";
CM_ SG_ 302 FR_Obj23_RelVx " ";
CM_ SG_ 302 FR_Obj23_RelVy_std " ";
CM_ SG_ 302 FR_Obj23_RelVy " ";
CM_ SG_ 302 FR_Obj23_Dx_Vnce " ";
CM_ SG_ 302 FR_Obj23_Dx " ";
CM_ SG_ 302 FR_Obj23_Dy_Vnce " ";
CM_ SG_ 302 FR_Obj23_Dy " ";
CM_ SG_ 302 FR_Obj23_HeadingAngle " ";
CM_ SG_ 302 FR_Obj23_Length " ";
CM_ SG_ 302 FR_Obj23_Height " ";
CM_ SG_ 302 FR_Obj23_Width " ";
CM_ SG_ 302 FR_Obj23_TypeProb " ";
CM_ SG_ 302 FR_Obj23_Type " ";
CM_ BO_ 303 " ";
CM_ SG_ 303 FR_CRCCheck_12F " ";
CM_ SG_ 303 FR_RollingCounter_12F " ";
CM_ SG_ 303 FR_Obj24_Ax " ";
CM_ SG_ 303 FR_Obj24_Ay " ";
CM_ SG_ 303 FR_Obj24_Vx " ";
CM_ SG_ 303 FR_Obj24_Vy " ";
CM_ SG_ 303 FR_Obj24_DelayTime " ";
CM_ SG_ 303 FR_Obj24_ReferPoint_Dx " ";
CM_ SG_ 303 FR_Obj24_HeightGround "反射点最强点距离地面的高度 ";
CM_ SG_ 303 FR_Obj24_MotionStatusConf " ";
CM_ SG_ 303 FR_Obj24_MotionStatus " ";
CM_ SG_ 303 FR_Obj24_Measured " ";
CM_ SG_ 303 FR_Obj24_valid " ";
CM_ SG_ 303 FR_Obj24_Track_Age " ";
CM_ SG_ 303 FR_Obj24_Track_ID " ";
CM_ SG_ 303 FR_Obj24_ObstacleProb " ";
CM_ SG_ 303 FR_Obj24_ExistProb " ";
CM_ SG_ 303 FR_Obj24_RelAx " ";
CM_ SG_ 303 FR_Obj24_RelAy " ";
CM_ SG_ 303 FR_Obj24_RelVx_std " ";
CM_ SG_ 303 FR_Obj24_RelVx " ";
CM_ SG_ 303 FR_Obj24_RelVy_std " ";
CM_ SG_ 303 FR_Obj24_RelVy " ";
CM_ SG_ 303 FR_Obj24_Dx_Vnce " ";
CM_ SG_ 303 FR_Obj24_Dx " ";
CM_ SG_ 303 FR_Obj24_Dy_Vnce " ";
CM_ SG_ 303 FR_Obj24_Dy " ";
CM_ SG_ 303 FR_Obj24_HeadingAngle " ";
CM_ SG_ 303 FR_Obj24_Length " ";
CM_ SG_ 303 FR_Obj24_Height " ";
CM_ SG_ 303 FR_Obj24_Width " ";
CM_ SG_ 303 FR_Obj24_TypeProb " ";
CM_ SG_ 303 FR_Obj24_Type " ";
CM_ BO_ 338 " ";
CM_ SG_ 338 ADC_SenceMode " ";
CM_ SG_ 338 AD_Reqmode "仅高配（带域控制器的车型） ";
CM_ BO_ 349 " ";
CM_ SG_ 349 ESP_Calibrated " ";
CM_ SG_ 349 ESP_CRCCheck_15D "mADC转发 ";
CM_ SG_ 349 ESP_RollingCounter_15D "mADC转发 ";
CM_ SG_ 349 ESP_YawRateValid "mADC转发 ";
CM_ SG_ 349 ESP_YawRate "mADC转发 ";
CM_ SG_ 349 ESP_LongAccelValid "mADC转发 ";
CM_ SG_ 349 ESP_LongAccel "mADC转发 ";
CM_ SG_ 349 ESP_LatAccelValid "mADC转发 ";
CM_ SG_ 349 ESP_LatAccel "mADC转发 ";
CM_ BO_ 377 " ";
CM_ SG_ 377 ADC_SYNC_Sync_Time " ";
CM_ SG_ 377 ADC_SYNC_UserByte_OVS_SGW " ";
CM_ SG_ 377 ADC_SYNC_TimeDomain " ";
CM_ SG_ 377 ADC_SYNC_Sequence " ";
CM_ SG_ 377 ADC_SYNC_CRC " ";
CM_ SG_ 377 ADC_SYNC_Type " ";
CM_ BO_ 384 " ";
CM_ SG_ 384 EpsSteerAgSensFilr " ";
CM_ SG_ 384 EpsSasCalSts " ";
CM_ SG_ 384 EpsSasSteerAgVld "mADC转发 ";
CM_ SG_ 384 EpsSasSteerAg "mADC转发 ";
CM_ SG_ 384 EpsSteerAgRate "mADC转发 ";
CM_ SG_ 384 EPS_CRCCheck_180 " ";
CM_ SG_ 384 EPS_RollingCounter_180 "messagecounter ";
CM_ BO_ 433 " ";
CM_ SG_ 433 VcuAccrPedlPosnVld " ";
CM_ SG_ 433 VcuAccrPedlPosn " ";
CM_ SG_ 433 VcuRdySts " ";
CM_ SG_ 433 VcuVehGearPosnVld " ";
CM_ SG_ 433 VcuGearPosn " ";
CM_ SG_ 433 VCU_CRCCheck_1B1 " ";
CM_ SG_ 433 VCU_RollingCounter_1B1 " ";
CM_ BO_ 450 " ";
CM_ SG_ 450 WhlSpdReRiPls " ";
CM_ SG_ 450 WhlSpdRiReDir " ";
CM_ SG_ 450 WhlSpdRiReDataVld " ";
CM_ SG_ 450 WhlSpdRiReData " ";
CM_ SG_ 450 WhlSpdReLePls " ";
CM_ SG_ 450 WhlSpdLeReDir " ";
CM_ SG_ 450 WhlSpdLeReDataVld " ";
CM_ SG_ 450 WhlSpdLeReData " ";
CM_ SG_ 450 WhlSpdFrntRiPls " ";
CM_ SG_ 450 WhlSpdRiFrntDir " ";
CM_ SG_ 450 WhlSpdRiFrntDataVld " ";
CM_ SG_ 450 WhlSpdRiFrntData " ";
CM_ SG_ 450 WhlSpdFrntLePls " ";
CM_ SG_ 450 WhlSpdLeFrntDir " ";
CM_ SG_ 450 WhlSpdLeFrntDataVld " ";
CM_ SG_ 450 WhlSpdLeFrntData " ";
CM_ SG_ 450 EspVehStandstill " ";
CM_ SG_ 450 EspVehSpdVld " ";
CM_ SG_ 450 EspVehSpd " ";
CM_ SG_ 450 ESP_RollingCounter_1C2 " ";
CM_ SG_ 450 ESP_CRCCheck_1C2 " ";
BA_DEF_ SG_  "GenSigStartValue" INT 0 0;
BA_DEF_ SG_  "GenSigInvalidValue" STRING ;
BA_DEF_ SG_  "GenSigCycleTime" INT 0 0;
BA_DEF_ SG_  "GenSigSendType" ENUM  "Cyclic","OnWrite","OnWriteWithRepetition","OnChange","OnChangeWithRepetition","IfActive","IfActiveWithRepetition","NoSigSendType","NotUsed","NotUsed","NotUsed","NotUsed","NotUsed";
BA_DEF_  "Baudrate" INT 0 1000000;
BA_DEF_  "BusType" STRING ;
BA_DEF_  "NmType" STRING ;
BA_DEF_  "Manufacturer" STRING ;
BA_DEF_  "VersionYear" INT 2009 2210;
BA_DEF_  "VersionNumber" INT 0 65535;
BA_DEF_  "VersionMonth" INT 0 18;
BA_DEF_  "VersionDay" INT 0 49;
BA_DEF_ BU_  "NodeLayerModules" STRING ;
BA_DEF_ BU_  "ILUsed" ENUM  "No","Yes";
BA_DEF_  "GenNWMTalkNM" STRING ;
BA_DEF_  "GenNWMGotoMode_BusSleep" STRING ;
BA_DEF_  "GenNWMGotoMode_Awake" STRING ;
BA_DEF_  "GenNWMApCanWakeUp" STRING ;
BA_DEF_  "GenNWMApCanSleep" STRING ;
BA_DEF_  "GenNWMApCanOn" STRING ;
BA_DEF_  "GenNWMApCanOff" STRING ;
BA_DEF_  "GenNWMApCanNormal" STRING ;
BA_DEF_  "GenNWMApBusSleep" STRING ;
BA_DEF_ BO_  "GenMsgSendType" ENUM  "Cyclic","Event","Direct","NotUsed","NotUsed","Cyclic","NotUsed","IfActive","NoMsgSendType","NotUsed";
BA_DEF_ BO_  "GenMsgILSupport" ENUM  "No","Yes";
BA_DEF_ BO_  "GenMsgCycleTime" INT 0 65535;
BA_DEF_ BO_  "CANFD_BRS" ENUM  "0","1";
BA_DEF_ BO_  "VFrameFormat" ENUM  "StandardCAN","ExtendedCAN","reserved","reserved","reserved","reserved","reserved","reserved","reserved","reserved","reserved","reserved","reserved","reserved","StandardCAN_FD","ExtendedCAN_FD";
BA_DEF_DEF_  "GenSigStartValue" 0;
BA_DEF_DEF_  "GenSigInvalidValue" "/";
BA_DEF_DEF_  "GenSigCycleTime" 0;
BA_DEF_DEF_  "GenSigSendType" "Cyclic";
BA_DEF_DEF_  "Baudrate" 500000;
BA_DEF_DEF_  "BusType" "";
BA_DEF_DEF_  "NmType" "";
BA_DEF_DEF_  "Manufacturer" "CHANA";
BA_DEF_DEF_  "VersionYear" 2010;
BA_DEF_DEF_  "VersionNumber" 0;
BA_DEF_DEF_  "VersionMonth" 11;
BA_DEF_DEF_  "VersionDay" 0;
BA_DEF_DEF_  "NodeLayerModules" "CANoeILNLVector.dll";
BA_DEF_DEF_  "ILUsed" "Yes";
BA_DEF_DEF_  "GenNWMTalkNM" "TalkNM()";
BA_DEF_DEF_  "GenNWMGotoMode_BusSleep" "GotoMode_BusSleep()";
BA_DEF_DEF_  "GenNWMGotoMode_Awake" "GotoMode_Awake()";
BA_DEF_DEF_  "GenNWMApCanWakeUp" "apCanWakeUp()";
BA_DEF_DEF_  "GenNWMApCanSleep" "apCanSleep()";
BA_DEF_DEF_  "GenNWMApCanOn" "apCanOn()";
BA_DEF_DEF_  "GenNWMApCanOff" "apCanOff()";
BA_DEF_DEF_  "GenNWMApCanNormal" "apCanNormal()";
BA_DEF_DEF_  "GenNWMApBusSleep" "apBusSleep()";
BA_DEF_DEF_  "GenMsgSendType" "NoMsgSendType";
BA_DEF_DEF_  "GenMsgILSupport" "Yes";
BA_DEF_DEF_  "GenMsgCycleTime" 0;
BA_DEF_DEF_  "CANFD_BRS" "1";
BA_DEF_DEF_  "VFrameFormat" "StandardCAN";
BA_ "BusType" "CAN FD";
BA_ "NmType" "OSEK";
BA_ "Baudrate" 2000000;
BA_ "VersionDay" 14;
BA_ "VersionNumber" 11;
BA_ "VersionYear" 2024;
BA_ "GenMsgSendType" BO_ 273 0;
BA_ "GenMsgCycleTime" BO_ 273 60;
BA_ "VFrameFormat" BO_ 273 14;
BA_ "GenMsgSendType" BO_ 274 0;
BA_ "GenMsgCycleTime" BO_ 274 60;
BA_ "VFrameFormat" BO_ 274 14;
BA_ "GenMsgSendType" BO_ 275 0;
BA_ "GenMsgCycleTime" BO_ 275 60;
BA_ "VFrameFormat" BO_ 275 14;
BA_ "GenMsgSendType" BO_ 276 0;
BA_ "GenMsgCycleTime" BO_ 276 60;
BA_ "VFrameFormat" BO_ 276 14;
BA_ "GenMsgSendType" BO_ 277 0;
BA_ "GenMsgCycleTime" BO_ 277 60;
BA_ "VFrameFormat" BO_ 277 14;
BA_ "GenMsgSendType" BO_ 278 0;
BA_ "GenMsgCycleTime" BO_ 278 60;
BA_ "VFrameFormat" BO_ 278 14;
BA_ "GenMsgSendType" BO_ 279 0;
BA_ "GenMsgCycleTime" BO_ 279 60;
BA_ "VFrameFormat" BO_ 279 14;
BA_ "GenMsgSendType" BO_ 280 0;
BA_ "GenMsgCycleTime" BO_ 280 60;
BA_ "VFrameFormat" BO_ 280 14;
BA_ "GenMsgSendType" BO_ 281 0;
BA_ "GenMsgCycleTime" BO_ 281 60;
BA_ "VFrameFormat" BO_ 281 14;
BA_ "GenMsgSendType" BO_ 288 0;
BA_ "GenMsgCycleTime" BO_ 288 60;
BA_ "VFrameFormat" BO_ 288 14;
BA_ "GenMsgSendType" BO_ 289 0;
BA_ "GenMsgCycleTime" BO_ 289 60;
BA_ "VFrameFormat" BO_ 289 14;
BA_ "GenMsgSendType" BO_ 290 0;
BA_ "GenMsgCycleTime" BO_ 290 60;
BA_ "VFrameFormat" BO_ 290 14;
BA_ "GenMsgSendType" BO_ 292 0;
BA_ "GenMsgCycleTime" BO_ 292 60;
BA_ "VFrameFormat" BO_ 292 14;
BA_ "GenMsgSendType" BO_ 293 0;
BA_ "GenMsgCycleTime" BO_ 293 60;
BA_ "VFrameFormat" BO_ 293 14;
BA_ "GenMsgSendType" BO_ 294 0;
BA_ "GenMsgCycleTime" BO_ 294 60;
BA_ "VFrameFormat" BO_ 294 14;
BA_ "GenMsgSendType" BO_ 295 0;
BA_ "GenMsgCycleTime" BO_ 295 60;
BA_ "VFrameFormat" BO_ 295 14;
BA_ "GenMsgSendType" BO_ 296 0;
BA_ "GenMsgCycleTime" BO_ 296 60;
BA_ "VFrameFormat" BO_ 296 14;
BA_ "GenMsgSendType" BO_ 297 0;
BA_ "GenMsgCycleTime" BO_ 297 60;
BA_ "VFrameFormat" BO_ 297 14;
BA_ "GenMsgSendType" BO_ 298 0;
BA_ "GenMsgCycleTime" BO_ 298 60;
BA_ "VFrameFormat" BO_ 298 14;
BA_ "GenMsgSendType" BO_ 299 0;
BA_ "GenMsgCycleTime" BO_ 299 60;
BA_ "VFrameFormat" BO_ 299 14;
BA_ "GenMsgSendType" BO_ 300 0;
BA_ "GenMsgCycleTime" BO_ 300 60;
BA_ "VFrameFormat" BO_ 300 14;
BA_ "GenMsgSendType" BO_ 301 0;
BA_ "GenMsgCycleTime" BO_ 301 60;
BA_ "VFrameFormat" BO_ 301 14;
BA_ "GenMsgSendType" BO_ 302 0;
BA_ "GenMsgCycleTime" BO_ 302 60;
BA_ "VFrameFormat" BO_ 302 14;
BA_ "GenMsgSendType" BO_ 303 0;
BA_ "GenMsgCycleTime" BO_ 303 60;
BA_ "VFrameFormat" BO_ 303 14;
BA_ "GenMsgSendType" BO_ 338 0;
BA_ "GenMsgCycleTime" BO_ 338 10;
BA_ "VFrameFormat" BO_ 338 14;
BA_ "GenMsgSendType" BO_ 349 0;
BA_ "GenMsgCycleTime" BO_ 349 10;
BA_ "VFrameFormat" BO_ 349 14;
BA_ "GenMsgSendType" BO_ 377 1;
BA_ "VFrameFormat" BO_ 377 14;
BA_ "GenMsgSendType" BO_ 384 0;
BA_ "GenMsgCycleTime" BO_ 384 10;
BA_ "VFrameFormat" BO_ 384 14;
BA_ "GenMsgSendType" BO_ 433 0;
BA_ "GenMsgCycleTime" BO_ 433 10;
BA_ "VFrameFormat" BO_ 433 14;
BA_ "GenMsgSendType" BO_ 450 0;
BA_ "GenMsgCycleTime" BO_ 450 10;
BA_ "VFrameFormat" BO_ 450 14;
BA_ "GenSigCycleTime" SG_ 273 FR_CRCCheck_111 60;
BA_ "GenSigCycleTime" SG_ 273 FR_RollingCounter_111 60;
BA_ "GenSigCycleTime" SG_ 273 FR_Obj1_Ax 60;
BA_ "GenSigCycleTime" SG_ 273 FR_Obj1_Ay 60;
BA_ "GenSigCycleTime" SG_ 273 FR_Obj1_Vx 60;
BA_ "GenSigCycleTime" SG_ 273 FR_Obj1_Vy 60;
BA_ "GenSigCycleTime" SG_ 273 FR_Obj1_DelayTime 60;
BA_ "GenSigCycleTime" SG_ 273 FR_Obj1_ReferPoint_Dx 60;
BA_ "GenSigCycleTime" SG_ 273 FR_Obj1_HeightGround 60;
BA_ "GenSigCycleTime" SG_ 273 FR_Obj1_MotionStatusConf 60;
BA_ "GenSigCycleTime" SG_ 273 FR_Obj1_MotionStatus 60;
BA_ "GenSigCycleTime" SG_ 273 FR_Obj1_Measured 60;
BA_ "GenSigCycleTime" SG_ 273 FR_Obj1_valid 60;
BA_ "GenSigCycleTime" SG_ 273 FR_Obj1_Track_Age 60;
BA_ "GenSigCycleTime" SG_ 273 FR_Obj1_Track_ID 60;
BA_ "GenSigCycleTime" SG_ 273 FR_Obj1_ObstacleProb 60;
BA_ "GenSigCycleTime" SG_ 273 FR_Obj1_ExistProb 60;
BA_ "GenSigCycleTime" SG_ 273 FR_Obj1_RelAx 60;
BA_ "GenSigCycleTime" SG_ 273 FR_Obj1_RelAy 60;
BA_ "GenSigInvalidValue" SG_ 273 FR_Obj1_RelVx_std "4095";
BA_ "GenSigCycleTime" SG_ 273 FR_Obj1_RelVx_std 60;
BA_ "GenSigCycleTime" SG_ 273 FR_Obj1_RelVx 60;
BA_ "GenSigInvalidValue" SG_ 273 FR_Obj1_RelVy_std "1023";
BA_ "GenSigCycleTime" SG_ 273 FR_Obj1_RelVy_std 60;
BA_ "GenSigCycleTime" SG_ 273 FR_Obj1_RelVy 60;
BA_ "GenSigInvalidValue" SG_ 273 FR_Obj1_Dx_Vnce "16383";
BA_ "GenSigCycleTime" SG_ 273 FR_Obj1_Dx_Vnce 60;
BA_ "GenSigCycleTime" SG_ 273 FR_Obj1_Dx 60;
BA_ "GenSigInvalidValue" SG_ 273 FR_Obj1_Dy_Vnce "1023";
BA_ "GenSigCycleTime" SG_ 273 FR_Obj1_Dy_Vnce 60;
BA_ "GenSigCycleTime" SG_ 273 FR_Obj1_Dy 60;
BA_ "GenSigCycleTime" SG_ 273 FR_Obj1_HeadingAngle 60;
BA_ "GenSigCycleTime" SG_ 273 FR_Obj1_Length 60;
BA_ "GenSigCycleTime" SG_ 273 FR_Obj1_Height 60;
BA_ "GenSigCycleTime" SG_ 273 FR_Obj1_Width 60;
BA_ "GenSigCycleTime" SG_ 273 FR_Obj1_TypeProb 60;
BA_ "GenSigCycleTime" SG_ 273 FR_Obj1_Type 60;
BA_ "GenSigCycleTime" SG_ 274 FR_CRCCheck_112 60;
BA_ "GenSigCycleTime" SG_ 274 FR_RollingCounter_112 60;
BA_ "GenSigCycleTime" SG_ 274 FR_Obj2_Ax 60;
BA_ "GenSigCycleTime" SG_ 274 FR_Obj2_Ay 60;
BA_ "GenSigCycleTime" SG_ 274 FR_Obj2_Vx 60;
BA_ "GenSigCycleTime" SG_ 274 FR_Obj2_Vy 60;
BA_ "GenSigCycleTime" SG_ 274 FR_Obj2_DelayTime 60;
BA_ "GenSigCycleTime" SG_ 274 FR_Obj2_ReferPoint_Dx 60;
BA_ "GenSigCycleTime" SG_ 274 FR_Obj2_HeightGround 60;
BA_ "GenSigCycleTime" SG_ 274 FR_Obj2_MotionStatusConf 60;
BA_ "GenSigCycleTime" SG_ 274 FR_Obj2_MotionStatus 60;
BA_ "GenSigCycleTime" SG_ 274 FR_Obj2_Measured 60;
BA_ "GenSigCycleTime" SG_ 274 FR_Obj2_valid 60;
BA_ "GenSigCycleTime" SG_ 274 FR_Obj2_Track_Age 60;
BA_ "GenSigCycleTime" SG_ 274 FR_Obj2_Track_ID 60;
BA_ "GenSigCycleTime" SG_ 274 FR_Obj2_ObstacleProb 60;
BA_ "GenSigCycleTime" SG_ 274 FR_Obj2_ExistProb 60;
BA_ "GenSigCycleTime" SG_ 274 FR_Obj2_RelAx 60;
BA_ "GenSigCycleTime" SG_ 274 FR_Obj2_RelAy 60;
BA_ "GenSigInvalidValue" SG_ 274 FR_Obj2_RelVx_std "4095";
BA_ "GenSigCycleTime" SG_ 274 FR_Obj2_RelVx_std 60;
BA_ "GenSigCycleTime" SG_ 274 FR_Obj2_RelVx 60;
BA_ "GenSigInvalidValue" SG_ 274 FR_Obj2_RelVy_std "1023";
BA_ "GenSigCycleTime" SG_ 274 FR_Obj2_RelVy_std 60;
BA_ "GenSigCycleTime" SG_ 274 FR_Obj2_RelVy 60;
BA_ "GenSigInvalidValue" SG_ 274 FR_Obj2_Dx_Vnce "16383";
BA_ "GenSigCycleTime" SG_ 274 FR_Obj2_Dx_Vnce 60;
BA_ "GenSigCycleTime" SG_ 274 FR_Obj2_Dx 60;
BA_ "GenSigInvalidValue" SG_ 274 FR_Obj2_Dy_Vnce "1023";
BA_ "GenSigCycleTime" SG_ 274 FR_Obj2_Dy_Vnce 60;
BA_ "GenSigCycleTime" SG_ 274 FR_Obj2_Dy 60;
BA_ "GenSigCycleTime" SG_ 274 FR_Obj2_HeadingAngle 60;
BA_ "GenSigCycleTime" SG_ 274 FR_Obj2_Length 60;
BA_ "GenSigCycleTime" SG_ 274 FR_Obj2_Height 60;
BA_ "GenSigCycleTime" SG_ 274 FR_Obj2_Width 60;
BA_ "GenSigCycleTime" SG_ 274 FR_Obj2_TypeProb 60;
BA_ "GenSigCycleTime" SG_ 274 FR_Obj2_Type 60;
BA_ "GenSigCycleTime" SG_ 275 FR_CRCCheck_113 60;
BA_ "GenSigCycleTime" SG_ 275 FR_RollingCounter_113 60;
BA_ "GenSigCycleTime" SG_ 275 FR_Obj3_Ax 60;
BA_ "GenSigCycleTime" SG_ 275 FR_Obj3_Ay 60;
BA_ "GenSigCycleTime" SG_ 275 FR_Obj3_Vx 60;
BA_ "GenSigCycleTime" SG_ 275 FR_Obj3_Vy 60;
BA_ "GenSigCycleTime" SG_ 275 FR_Obj3_DelayTime 60;
BA_ "GenSigCycleTime" SG_ 275 FR_Obj3_ReferPoint_Dx 60;
BA_ "GenSigCycleTime" SG_ 275 FR_Obj3_HeightGround 60;
BA_ "GenSigCycleTime" SG_ 275 FR_Obj3_MotionStatusConf 60;
BA_ "GenSigCycleTime" SG_ 275 FR_Obj3_MotionStatus 60;
BA_ "GenSigCycleTime" SG_ 275 FR_Obj3_Measured 60;
BA_ "GenSigCycleTime" SG_ 275 FR_Obj3_valid 60;
BA_ "GenSigCycleTime" SG_ 275 FR_Obj3_Track_Age 60;
BA_ "GenSigCycleTime" SG_ 275 FR_Obj3_Track_ID 60;
BA_ "GenSigCycleTime" SG_ 275 FR_Obj3_ObstacleProb 60;
BA_ "GenSigCycleTime" SG_ 275 FR_Obj3_ExistProb 60;
BA_ "GenSigCycleTime" SG_ 275 FR_Obj3_RelAx 60;
BA_ "GenSigCycleTime" SG_ 275 FR_Obj3_RelAy 60;
BA_ "GenSigInvalidValue" SG_ 275 FR_Obj3_RelVx_std "4095";
BA_ "GenSigCycleTime" SG_ 275 FR_Obj3_RelVx_std 60;
BA_ "GenSigCycleTime" SG_ 275 FR_Obj3_RelVx 60;
BA_ "GenSigInvalidValue" SG_ 275 FR_Obj3_RelVy_std "1023";
BA_ "GenSigCycleTime" SG_ 275 FR_Obj3_RelVy_std 60;
BA_ "GenSigCycleTime" SG_ 275 FR_Obj3_RelVy 60;
BA_ "GenSigInvalidValue" SG_ 275 FR_Obj3_Dx_Vnce "16383";
BA_ "GenSigCycleTime" SG_ 275 FR_Obj3_Dx_Vnce 60;
BA_ "GenSigCycleTime" SG_ 275 FR_Obj3_Dx 60;
BA_ "GenSigInvalidValue" SG_ 275 FR_Obj3_Dy_Vnce "1023";
BA_ "GenSigCycleTime" SG_ 275 FR_Obj3_Dy_Vnce 60;
BA_ "GenSigCycleTime" SG_ 275 FR_Obj3_Dy 60;
BA_ "GenSigCycleTime" SG_ 275 FR_Obj3_HeadingAngle 60;
BA_ "GenSigCycleTime" SG_ 275 FR_Obj3_Length 60;
BA_ "GenSigCycleTime" SG_ 275 FR_Obj3_Height 60;
BA_ "GenSigCycleTime" SG_ 275 FR_Obj3_Width 60;
BA_ "GenSigCycleTime" SG_ 275 FR_Obj3_TypeProb 60;
BA_ "GenSigCycleTime" SG_ 275 FR_Obj3_Type 60;
BA_ "GenSigCycleTime" SG_ 276 FR_CRCCheck_114 60;
BA_ "GenSigCycleTime" SG_ 276 FR_RollingCounter_114 60;
BA_ "GenSigCycleTime" SG_ 276 FR_Obj4_Ax 60;
BA_ "GenSigCycleTime" SG_ 276 FR_Obj4_Ay 60;
BA_ "GenSigCycleTime" SG_ 276 FR_Obj4_Vx 60;
BA_ "GenSigCycleTime" SG_ 276 FR_Obj4_Vy 60;
BA_ "GenSigCycleTime" SG_ 276 FR_Obj4_DelayTime 60;
BA_ "GenSigCycleTime" SG_ 276 FR_Obj4_ReferPoint_Dx 60;
BA_ "GenSigCycleTime" SG_ 276 FR_Obj4_HeightGround 60;
BA_ "GenSigCycleTime" SG_ 276 FR_Obj4_MotionStatusConf 60;
BA_ "GenSigCycleTime" SG_ 276 FR_Obj4_MotionStatus 60;
BA_ "GenSigCycleTime" SG_ 276 FR_Obj4_Measured 60;
BA_ "GenSigCycleTime" SG_ 276 FR_Obj4_valid 60;
BA_ "GenSigCycleTime" SG_ 276 FR_Obj4_Track_Age 60;
BA_ "GenSigCycleTime" SG_ 276 FR_Obj4_Track_ID 60;
BA_ "GenSigCycleTime" SG_ 276 FR_Obj4_ObstacleProb 60;
BA_ "GenSigCycleTime" SG_ 276 FR_Obj4_ExistProb 60;
BA_ "GenSigCycleTime" SG_ 276 FR_Obj4_RelAx 60;
BA_ "GenSigCycleTime" SG_ 276 FR_Obj4_RelAy 60;
BA_ "GenSigInvalidValue" SG_ 276 FR_Obj4_RelVx_std "4095";
BA_ "GenSigCycleTime" SG_ 276 FR_Obj4_RelVx_std 60;
BA_ "GenSigCycleTime" SG_ 276 FR_Obj4_RelVx 60;
BA_ "GenSigInvalidValue" SG_ 276 FR_Obj4_RelVy_std "1023";
BA_ "GenSigCycleTime" SG_ 276 FR_Obj4_RelVy_std 60;
BA_ "GenSigCycleTime" SG_ 276 FR_Obj4_RelVy 60;
BA_ "GenSigInvalidValue" SG_ 276 FR_Obj4_Dx_Vnce "16383";
BA_ "GenSigCycleTime" SG_ 276 FR_Obj4_Dx_Vnce 60;
BA_ "GenSigCycleTime" SG_ 276 FR_Obj4_Dx 60;
BA_ "GenSigInvalidValue" SG_ 276 FR_Obj4_Dy_Vnce "1023";
BA_ "GenSigCycleTime" SG_ 276 FR_Obj4_Dy_Vnce 60;
BA_ "GenSigCycleTime" SG_ 276 FR_Obj4_Dy 60;
BA_ "GenSigCycleTime" SG_ 276 FR_Obj4_HeadingAngle 60;
BA_ "GenSigCycleTime" SG_ 276 FR_Obj4_Length 60;
BA_ "GenSigCycleTime" SG_ 276 FR_Obj4_Height 60;
BA_ "GenSigCycleTime" SG_ 276 FR_Obj4_Width 60;
BA_ "GenSigCycleTime" SG_ 276 FR_Obj4_TypeProb 60;
BA_ "GenSigCycleTime" SG_ 276 FR_Obj4_Type 60;
BA_ "GenSigCycleTime" SG_ 277 FR_CRCCheck_115 60;
BA_ "GenSigCycleTime" SG_ 277 FR_RollingCounter_115 60;
BA_ "GenSigCycleTime" SG_ 277 FR_Obj5_Ax 60;
BA_ "GenSigCycleTime" SG_ 277 FR_Obj5_Ay 60;
BA_ "GenSigCycleTime" SG_ 277 FR_Obj5_Vx 60;
BA_ "GenSigCycleTime" SG_ 277 FR_Obj5_Vy 60;
BA_ "GenSigCycleTime" SG_ 277 FR_Obj5_DelayTime 60;
BA_ "GenSigCycleTime" SG_ 277 FR_Obj5_ReferPoint_Dx 60;
BA_ "GenSigCycleTime" SG_ 277 FR_Obj5_HeightGround 60;
BA_ "GenSigCycleTime" SG_ 277 FR_Obj5_MotionStatusConf 60;
BA_ "GenSigCycleTime" SG_ 277 FR_Obj5_MotionStatus 60;
BA_ "GenSigCycleTime" SG_ 277 FR_Obj5_Measured 60;
BA_ "GenSigCycleTime" SG_ 277 FR_Obj5_valid 60;
BA_ "GenSigCycleTime" SG_ 277 FR_Obj5_Track_Age 60;
BA_ "GenSigCycleTime" SG_ 277 FR_Obj5_Track_ID 60;
BA_ "GenSigCycleTime" SG_ 277 FR_Obj5_ObstacleProb 60;
BA_ "GenSigCycleTime" SG_ 277 FR_Obj5_ExistProb 60;
BA_ "GenSigCycleTime" SG_ 277 FR_Obj5_RelAx 60;
BA_ "GenSigCycleTime" SG_ 277 FR_Obj5_RelAy 60;
BA_ "GenSigInvalidValue" SG_ 277 FR_Obj5_RelVx_std "4095";
BA_ "GenSigCycleTime" SG_ 277 FR_Obj5_RelVx_std 60;
BA_ "GenSigCycleTime" SG_ 277 FR_Obj5_RelVx 60;
BA_ "GenSigInvalidValue" SG_ 277 FR_Obj5_RelVy_std "1023";
BA_ "GenSigCycleTime" SG_ 277 FR_Obj5_RelVy_std 60;
BA_ "GenSigCycleTime" SG_ 277 FR_Obj5_RelVy 60;
BA_ "GenSigInvalidValue" SG_ 277 FR_Obj5_Dx_Vnce "16383";
BA_ "GenSigCycleTime" SG_ 277 FR_Obj5_Dx_Vnce 60;
BA_ "GenSigCycleTime" SG_ 277 FR_Obj5_Dx 60;
BA_ "GenSigInvalidValue" SG_ 277 FR_Obj5_Dy_Vnce "1023";
BA_ "GenSigCycleTime" SG_ 277 FR_Obj5_Dy_Vnce 60;
BA_ "GenSigCycleTime" SG_ 277 FR_Obj5_Dy 60;
BA_ "GenSigCycleTime" SG_ 277 FR_Obj5_HeadingAngle 60;
BA_ "GenSigCycleTime" SG_ 277 FR_Obj5_Length 60;
BA_ "GenSigCycleTime" SG_ 277 FR_Obj5_Height 60;
BA_ "GenSigCycleTime" SG_ 277 FR_Obj5_Width 60;
BA_ "GenSigCycleTime" SG_ 277 FR_Obj5_TypeProb 60;
BA_ "GenSigCycleTime" SG_ 277 FR_Obj5_Type 60;
BA_ "GenSigCycleTime" SG_ 278 FR_CRCCheck_116 60;
BA_ "GenSigCycleTime" SG_ 278 FR_RollingCounter_116 60;
BA_ "GenSigCycleTime" SG_ 278 FR_Obj6_Ax 60;
BA_ "GenSigCycleTime" SG_ 278 FR_Obj6_Ay 60;
BA_ "GenSigCycleTime" SG_ 278 FR_Obj6_Vx 60;
BA_ "GenSigCycleTime" SG_ 278 FR_Obj6_Vy 60;
BA_ "GenSigCycleTime" SG_ 278 FR_Obj6_DelayTime 60;
BA_ "GenSigCycleTime" SG_ 278 FR_Obj6_ReferPoint_Dx 60;
BA_ "GenSigCycleTime" SG_ 278 FR_Obj6_HeightGround 60;
BA_ "GenSigCycleTime" SG_ 278 FR_Obj6_MotionStatusConf 60;
BA_ "GenSigCycleTime" SG_ 278 FR_Obj6_MotionStatus 60;
BA_ "GenSigCycleTime" SG_ 278 FR_Obj6_Measured 60;
BA_ "GenSigCycleTime" SG_ 278 FR_Obj6_valid 60;
BA_ "GenSigCycleTime" SG_ 278 FR_Obj6_Track_Age 60;
BA_ "GenSigCycleTime" SG_ 278 FR_Obj6_Track_ID 60;
BA_ "GenSigCycleTime" SG_ 278 FR_Obj6_ObstacleProb 60;
BA_ "GenSigCycleTime" SG_ 278 FR_Obj6_ExistProb 60;
BA_ "GenSigCycleTime" SG_ 278 FR_Obj6_RelAx 60;
BA_ "GenSigCycleTime" SG_ 278 FR_Obj6_RelAy 60;
BA_ "GenSigInvalidValue" SG_ 278 FR_Obj6_RelVx_std "4095";
BA_ "GenSigCycleTime" SG_ 278 FR_Obj6_RelVx_std 60;
BA_ "GenSigCycleTime" SG_ 278 FR_Obj6_RelVx 60;
BA_ "GenSigInvalidValue" SG_ 278 FR_Obj6_RelVy_std "1023";
BA_ "GenSigCycleTime" SG_ 278 FR_Obj6_RelVy_std 60;
BA_ "GenSigCycleTime" SG_ 278 FR_Obj6_RelVy 60;
BA_ "GenSigInvalidValue" SG_ 278 FR_Obj6_Dx_Vnce "16383";
BA_ "GenSigCycleTime" SG_ 278 FR_Obj6_Dx_Vnce 60;
BA_ "GenSigCycleTime" SG_ 278 FR_Obj6_Dx 60;
BA_ "GenSigInvalidValue" SG_ 278 FR_Obj6_Dy_Vnce "1023";
BA_ "GenSigCycleTime" SG_ 278 FR_Obj6_Dy_Vnce 60;
BA_ "GenSigCycleTime" SG_ 278 FR_Obj6_Dy 60;
BA_ "GenSigCycleTime" SG_ 278 FR_Obj6_HeadingAngle 60;
BA_ "GenSigCycleTime" SG_ 278 FR_Obj6_Length 60;
BA_ "GenSigCycleTime" SG_ 278 FR_Obj6_Height 60;
BA_ "GenSigCycleTime" SG_ 278 FR_Obj6_Width 60;
BA_ "GenSigCycleTime" SG_ 278 FR_Obj6_TypeProb 60;
BA_ "GenSigCycleTime" SG_ 278 FR_Obj6_Type 60;
BA_ "GenSigCycleTime" SG_ 279 FR_CRCCheck_117 60;
BA_ "GenSigCycleTime" SG_ 279 FR_RollingCounter_117 60;
BA_ "GenSigCycleTime" SG_ 279 FR_Obj7_Ax 60;
BA_ "GenSigCycleTime" SG_ 279 FR_Obj7_Ay 60;
BA_ "GenSigCycleTime" SG_ 279 FR_Obj7_Vx 60;
BA_ "GenSigCycleTime" SG_ 279 FR_Obj7_Vy 60;
BA_ "GenSigCycleTime" SG_ 279 FR_Obj7_DelayTime 60;
BA_ "GenSigCycleTime" SG_ 279 FR_Obj7_ReferPoint_Dx 60;
BA_ "GenSigCycleTime" SG_ 279 FR_Obj7_HeightGround 60;
BA_ "GenSigCycleTime" SG_ 279 FR_Obj7_MotionStatusConf 60;
BA_ "GenSigCycleTime" SG_ 279 FR_Obj7_MotionStatus 60;
BA_ "GenSigCycleTime" SG_ 279 FR_Obj7_Measured 60;
BA_ "GenSigCycleTime" SG_ 279 FR_Obj7_valid 60;
BA_ "GenSigCycleTime" SG_ 279 FR_Obj7_Track_Age 60;
BA_ "GenSigCycleTime" SG_ 279 FR_Obj7_Track_ID 60;
BA_ "GenSigCycleTime" SG_ 279 FR_Obj7_ObstacleProb 60;
BA_ "GenSigCycleTime" SG_ 279 FR_Obj7_ExistProb 60;
BA_ "GenSigCycleTime" SG_ 279 FR_Obj7_RelAx 60;
BA_ "GenSigCycleTime" SG_ 279 FR_Obj7_RelAy 60;
BA_ "GenSigInvalidValue" SG_ 279 FR_Obj7_RelVx_std "4095";
BA_ "GenSigCycleTime" SG_ 279 FR_Obj7_RelVx_std 60;
BA_ "GenSigCycleTime" SG_ 279 FR_Obj7_RelVx 60;
BA_ "GenSigInvalidValue" SG_ 279 FR_Obj7_RelVy_std "1023";
BA_ "GenSigCycleTime" SG_ 279 FR_Obj7_RelVy_std 60;
BA_ "GenSigCycleTime" SG_ 279 FR_Obj7_RelVy 60;
BA_ "GenSigInvalidValue" SG_ 279 FR_Obj7_Dx_Vnce "16383";
BA_ "GenSigCycleTime" SG_ 279 FR_Obj7_Dx_Vnce 60;
BA_ "GenSigCycleTime" SG_ 279 FR_Obj7_Dx 60;
BA_ "GenSigInvalidValue" SG_ 279 FR_Obj7_Dy_Vnce "1023";
BA_ "GenSigCycleTime" SG_ 279 FR_Obj7_Dy_Vnce 60;
BA_ "GenSigCycleTime" SG_ 279 FR_Obj7_Dy 60;
BA_ "GenSigCycleTime" SG_ 279 FR_Obj7_HeadingAngle 60;
BA_ "GenSigCycleTime" SG_ 279 FR_Obj7_Length 60;
BA_ "GenSigCycleTime" SG_ 279 FR_Obj7_Height 60;
BA_ "GenSigCycleTime" SG_ 279 FR_Obj7_Width 60;
BA_ "GenSigCycleTime" SG_ 279 FR_Obj7_TypeProb 60;
BA_ "GenSigCycleTime" SG_ 279 FR_Obj7_Type 60;
BA_ "GenSigCycleTime" SG_ 280 FR_CRCCheck_118 60;
BA_ "GenSigCycleTime" SG_ 280 FR_RollingCounter_118 60;
BA_ "GenSigCycleTime" SG_ 280 FR_Obj8_Ax 60;
BA_ "GenSigCycleTime" SG_ 280 FR_Obj8_Ay 60;
BA_ "GenSigCycleTime" SG_ 280 FR_Obj8_Vx 60;
BA_ "GenSigCycleTime" SG_ 280 FR_Obj8_Vy 60;
BA_ "GenSigCycleTime" SG_ 280 FR_Obj8_DelayTime 60;
BA_ "GenSigCycleTime" SG_ 280 FR_Obj8_ReferPoint_Dx 60;
BA_ "GenSigCycleTime" SG_ 280 FR_Obj8_HeightGround 60;
BA_ "GenSigCycleTime" SG_ 280 FR_Obj8_MotionStatusConf 60;
BA_ "GenSigCycleTime" SG_ 280 FR_Obj8_MotionStatus 60;
BA_ "GenSigCycleTime" SG_ 280 FR_Obj8_Measured 60;
BA_ "GenSigCycleTime" SG_ 280 FR_Obj8_valid 60;
BA_ "GenSigCycleTime" SG_ 280 FR_Obj8_Track_Age 60;
BA_ "GenSigCycleTime" SG_ 280 FR_Obj8_Track_ID 60;
BA_ "GenSigCycleTime" SG_ 280 FR_Obj8_ObstacleProb 60;
BA_ "GenSigCycleTime" SG_ 280 FR_Obj8_ExistProb 60;
BA_ "GenSigCycleTime" SG_ 280 FR_Obj8_RelAx 60;
BA_ "GenSigCycleTime" SG_ 280 FR_Obj8_RelAy 60;
BA_ "GenSigInvalidValue" SG_ 280 FR_Obj8_RelVx_std "4095";
BA_ "GenSigCycleTime" SG_ 280 FR_Obj8_RelVx_std 60;
BA_ "GenSigCycleTime" SG_ 280 FR_Obj8_RelVx 60;
BA_ "GenSigInvalidValue" SG_ 280 FR_Obj8_RelVy_std "1023";
BA_ "GenSigCycleTime" SG_ 280 FR_Obj8_RelVy_std 60;
BA_ "GenSigCycleTime" SG_ 280 FR_Obj8_RelVy 60;
BA_ "GenSigInvalidValue" SG_ 280 FR_Obj8_Dx_Vnce "16383";
BA_ "GenSigCycleTime" SG_ 280 FR_Obj8_Dx_Vnce 60;
BA_ "GenSigCycleTime" SG_ 280 FR_Obj8_Dx 60;
BA_ "GenSigInvalidValue" SG_ 280 FR_Obj8_Dy_Vnce "1023";
BA_ "GenSigCycleTime" SG_ 280 FR_Obj8_Dy_Vnce 60;
BA_ "GenSigCycleTime" SG_ 280 FR_Obj8_Dy 60;
BA_ "GenSigCycleTime" SG_ 280 FR_Obj8_HeadingAngle 60;
BA_ "GenSigCycleTime" SG_ 280 FR_Obj8_Length 60;
BA_ "GenSigCycleTime" SG_ 280 FR_Obj8_Height 60;
BA_ "GenSigCycleTime" SG_ 280 FR_Obj8_Width 60;
BA_ "GenSigCycleTime" SG_ 280 FR_Obj8_TypeProb 60;
BA_ "GenSigCycleTime" SG_ 280 FR_Obj8_Type 60;
BA_ "GenSigCycleTime" SG_ 281 FR_CRCCheck_119 60;
BA_ "GenSigCycleTime" SG_ 281 FR_RollingCounter_119 60;
BA_ "GenSigCycleTime" SG_ 281 FR_Obj9_Ax 60;
BA_ "GenSigCycleTime" SG_ 281 FR_Obj9_Ay 60;
BA_ "GenSigCycleTime" SG_ 281 FR_Obj9_Vx 60;
BA_ "GenSigCycleTime" SG_ 281 FR_Obj9_Vy 60;
BA_ "GenSigCycleTime" SG_ 281 FR_Obj9_DelayTime 60;
BA_ "GenSigCycleTime" SG_ 281 FR_Obj9_ReferPoint_Dx 60;
BA_ "GenSigCycleTime" SG_ 281 FR_Obj9_HeightGround 60;
BA_ "GenSigCycleTime" SG_ 281 FR_Obj9_MotionStatusConf 60;
BA_ "GenSigCycleTime" SG_ 281 FR_Obj9_MotionStatus 60;
BA_ "GenSigCycleTime" SG_ 281 FR_Obj9_Measured 60;
BA_ "GenSigCycleTime" SG_ 281 FR_Obj9_valid 60;
BA_ "GenSigCycleTime" SG_ 281 FR_Obj9_Track_Age 60;
BA_ "GenSigCycleTime" SG_ 281 FR_Obj9_Track_ID 60;
BA_ "GenSigCycleTime" SG_ 281 FR_Obj9_ObstacleProb 60;
BA_ "GenSigCycleTime" SG_ 281 FR_Obj9_ExistProb 60;
BA_ "GenSigCycleTime" SG_ 281 FR_Obj9_RelAx 60;
BA_ "GenSigCycleTime" SG_ 281 FR_Obj9_RelAy 60;
BA_ "GenSigInvalidValue" SG_ 281 FR_Obj9_RelVx_std "4095";
BA_ "GenSigCycleTime" SG_ 281 FR_Obj9_RelVx_std 60;
BA_ "GenSigCycleTime" SG_ 281 FR_Obj9_RelVx 60;
BA_ "GenSigInvalidValue" SG_ 281 FR_Obj9_RelVy_std "1023";
BA_ "GenSigCycleTime" SG_ 281 FR_Obj9_RelVy_std 60;
BA_ "GenSigCycleTime" SG_ 281 FR_Obj9_RelVy 60;
BA_ "GenSigInvalidValue" SG_ 281 FR_Obj9_Dx_Vnce "16383";
BA_ "GenSigCycleTime" SG_ 281 FR_Obj9_Dx_Vnce 60;
BA_ "GenSigCycleTime" SG_ 281 FR_Obj9_Dx 60;
BA_ "GenSigInvalidValue" SG_ 281 FR_Obj9_Dy_Vnce "1023";
BA_ "GenSigCycleTime" SG_ 281 FR_Obj9_Dy_Vnce 60;
BA_ "GenSigCycleTime" SG_ 281 FR_Obj9_Dy 60;
BA_ "GenSigCycleTime" SG_ 281 FR_Obj9_HeadingAngle 60;
BA_ "GenSigCycleTime" SG_ 281 FR_Obj9_Length 60;
BA_ "GenSigCycleTime" SG_ 281 FR_Obj9_Height 60;
BA_ "GenSigCycleTime" SG_ 281 FR_Obj9_Width 60;
BA_ "GenSigCycleTime" SG_ 281 FR_Obj9_TypeProb 60;
BA_ "GenSigCycleTime" SG_ 281 FR_Obj9_Type 60;
BA_ "GenSigCycleTime" SG_ 288 FR_CRCCheck_120 60;
BA_ "GenSigCycleTime" SG_ 288 FR_RollingCounter_120 60;
BA_ "GenSigCycleTime" SG_ 288 FR_Obj10_Ax 60;
BA_ "GenSigCycleTime" SG_ 288 FR_Obj10_Ay 60;
BA_ "GenSigCycleTime" SG_ 288 FR_Obj10_Vx 60;
BA_ "GenSigCycleTime" SG_ 288 FR_Obj10_Vy 60;
BA_ "GenSigCycleTime" SG_ 288 FR_Obj10_DelayTime 60;
BA_ "GenSigCycleTime" SG_ 288 FR_Obj10_ReferPoint_Dx 60;
BA_ "GenSigCycleTime" SG_ 288 FR_Obj10_HeightGround 60;
BA_ "GenSigCycleTime" SG_ 288 FR_Obj10_MotionStatusConf 60;
BA_ "GenSigCycleTime" SG_ 288 FR_Obj10_MotionStatus 60;
BA_ "GenSigCycleTime" SG_ 288 FR_Obj10_Measured 60;
BA_ "GenSigCycleTime" SG_ 288 FR_Obj10_valid 60;
BA_ "GenSigCycleTime" SG_ 288 FR_Obj10_Track_Age 60;
BA_ "GenSigCycleTime" SG_ 288 FR_Obj10_Track_ID 60;
BA_ "GenSigCycleTime" SG_ 288 FR_Obj10_ObstacleProb 60;
BA_ "GenSigCycleTime" SG_ 288 FR_Obj10_ExistProb 60;
BA_ "GenSigCycleTime" SG_ 288 FR_Obj10_RelAx 60;
BA_ "GenSigCycleTime" SG_ 288 FR_Obj10_RelAy 60;
BA_ "GenSigInvalidValue" SG_ 288 FR_Obj10_RelVx_std "4095";
BA_ "GenSigCycleTime" SG_ 288 FR_Obj10_RelVx_std 60;
BA_ "GenSigCycleTime" SG_ 288 FR_Obj10_RelVx 60;
BA_ "GenSigInvalidValue" SG_ 288 FR_Obj10_RelVy_std "1023";
BA_ "GenSigCycleTime" SG_ 288 FR_Obj10_RelVy_std 60;
BA_ "GenSigCycleTime" SG_ 288 FR_Obj10_RelVy 60;
BA_ "GenSigInvalidValue" SG_ 288 FR_Obj10_Dx_Vnce "16383";
BA_ "GenSigCycleTime" SG_ 288 FR_Obj10_Dx_Vnce 60;
BA_ "GenSigCycleTime" SG_ 288 FR_Obj10_Dx 60;
BA_ "GenSigInvalidValue" SG_ 288 FR_Obj10_Dy_Vnce "1023";
BA_ "GenSigCycleTime" SG_ 288 FR_Obj10_Dy_Vnce 60;
BA_ "GenSigCycleTime" SG_ 288 FR_Obj10_Dy 60;
BA_ "GenSigCycleTime" SG_ 288 FR_Obj10_HeadingAngle 60;
BA_ "GenSigCycleTime" SG_ 288 FR_Obj10_Length 60;
BA_ "GenSigCycleTime" SG_ 288 FR_Obj10_Height 60;
BA_ "GenSigCycleTime" SG_ 288 FR_Obj10_Width 60;
BA_ "GenSigCycleTime" SG_ 288 FR_Obj10_TypeProb 60;
BA_ "GenSigCycleTime" SG_ 288 FR_Obj10_Type 60;
BA_ "GenSigCycleTime" SG_ 289 FR_CRCCheck_121 60;
BA_ "GenSigCycleTime" SG_ 289 FR_RollingCounter_121 60;
BA_ "GenSigCycleTime" SG_ 289 FR_Obj11_Ax 60;
BA_ "GenSigCycleTime" SG_ 289 FR_Obj11_Ay 60;
BA_ "GenSigCycleTime" SG_ 289 FR_Obj11_Vx 60;
BA_ "GenSigCycleTime" SG_ 289 FR_Obj11_Vy 60;
BA_ "GenSigCycleTime" SG_ 289 FR_Obj11_DelayTime 60;
BA_ "GenSigCycleTime" SG_ 289 FR_Obj11_ReferPoint_Dx 60;
BA_ "GenSigCycleTime" SG_ 289 FR_Obj11_HeightGround 60;
BA_ "GenSigCycleTime" SG_ 289 FR_Obj11_MotionStatusConf 60;
BA_ "GenSigCycleTime" SG_ 289 FR_Obj11_MotionStatus 60;
BA_ "GenSigCycleTime" SG_ 289 FR_Obj11_Measured 60;
BA_ "GenSigCycleTime" SG_ 289 FR_Obj11_valid 60;
BA_ "GenSigCycleTime" SG_ 289 FR_Obj11_Track_Age 60;
BA_ "GenSigCycleTime" SG_ 289 FR_Obj11_Track_ID 60;
BA_ "GenSigCycleTime" SG_ 289 FR_Obj11_ObstacleProb 60;
BA_ "GenSigCycleTime" SG_ 289 FR_Obj11_ExistProb 60;
BA_ "GenSigCycleTime" SG_ 289 FR_Obj11_RelAx 60;
BA_ "GenSigCycleTime" SG_ 289 FR_Obj11_RelAy 60;
BA_ "GenSigInvalidValue" SG_ 289 FR_Obj11_RelVx_std "4095";
BA_ "GenSigCycleTime" SG_ 289 FR_Obj11_RelVx_std 60;
BA_ "GenSigCycleTime" SG_ 289 FR_Obj11_RelVx 60;
BA_ "GenSigInvalidValue" SG_ 289 FR_Obj11_RelVy_std "1023";
BA_ "GenSigCycleTime" SG_ 289 FR_Obj11_RelVy_std 60;
BA_ "GenSigCycleTime" SG_ 289 FR_Obj11_RelVy 60;
BA_ "GenSigInvalidValue" SG_ 289 FR_Obj11_Dx_Vnce "16383";
BA_ "GenSigCycleTime" SG_ 289 FR_Obj11_Dx_Vnce 60;
BA_ "GenSigCycleTime" SG_ 289 FR_Obj11_Dx 60;
BA_ "GenSigInvalidValue" SG_ 289 FR_Obj11_Dy_Vnce "1023";
BA_ "GenSigCycleTime" SG_ 289 FR_Obj11_Dy_Vnce 60;
BA_ "GenSigCycleTime" SG_ 289 FR_Obj11_Dy 60;
BA_ "GenSigCycleTime" SG_ 289 FR_Obj11_HeadingAngle 60;
BA_ "GenSigCycleTime" SG_ 289 FR_Obj11_Length 60;
BA_ "GenSigCycleTime" SG_ 289 FR_Obj11_Height 60;
BA_ "GenSigCycleTime" SG_ 289 FR_Obj11_Width 60;
BA_ "GenSigCycleTime" SG_ 289 FR_Obj11_TypeProb 60;
BA_ "GenSigCycleTime" SG_ 289 FR_Obj11_Type 60;
BA_ "GenSigCycleTime" SG_ 290 FR_CRCCheck_122 60;
BA_ "GenSigCycleTime" SG_ 290 FR_RollingCounter_122 60;
BA_ "GenSigCycleTime" SG_ 290 FR_Obj12_Ax 60;
BA_ "GenSigCycleTime" SG_ 290 FR_Obj12_Ay 60;
BA_ "GenSigCycleTime" SG_ 290 FR_Obj12_Vx 60;
BA_ "GenSigCycleTime" SG_ 290 FR_Obj12_Vy 60;
BA_ "GenSigCycleTime" SG_ 290 FR_Obj12_DelayTime 60;
BA_ "GenSigCycleTime" SG_ 290 FR_Obj12_ReferPoint_Dx 60;
BA_ "GenSigCycleTime" SG_ 290 FR_Obj12_HeightGround 60;
BA_ "GenSigCycleTime" SG_ 290 FR_Obj12_MotionStatusConf 60;
BA_ "GenSigCycleTime" SG_ 290 FR_Obj12_MotionStatus 60;
BA_ "GenSigCycleTime" SG_ 290 FR_Obj12_Measured 60;
BA_ "GenSigCycleTime" SG_ 290 FR_Obj12_valid 60;
BA_ "GenSigCycleTime" SG_ 290 FR_Obj12_Track_Age 60;
BA_ "GenSigCycleTime" SG_ 290 FR_Obj12_Track_ID 60;
BA_ "GenSigCycleTime" SG_ 290 FR_Obj12_ObstacleProb 60;
BA_ "GenSigCycleTime" SG_ 290 FR_Obj12_ExistProb 60;
BA_ "GenSigCycleTime" SG_ 290 FR_Obj12_RelAx 60;
BA_ "GenSigCycleTime" SG_ 290 FR_Obj12_RelAy 60;
BA_ "GenSigInvalidValue" SG_ 290 FR_Obj12_RelVx_std "4095";
BA_ "GenSigCycleTime" SG_ 290 FR_Obj12_RelVx_std 60;
BA_ "GenSigCycleTime" SG_ 290 FR_Obj12_RelVx 60;
BA_ "GenSigInvalidValue" SG_ 290 FR_Obj12_RelVy_std "1023";
BA_ "GenSigCycleTime" SG_ 290 FR_Obj12_RelVy_std 60;
BA_ "GenSigCycleTime" SG_ 290 FR_Obj12_RelVy 60;
BA_ "GenSigInvalidValue" SG_ 290 FR_Obj12_Dx_Vnce "16383";
BA_ "GenSigCycleTime" SG_ 290 FR_Obj12_Dx_Vnce 60;
BA_ "GenSigCycleTime" SG_ 290 FR_Obj12_Dx 60;
BA_ "GenSigInvalidValue" SG_ 290 FR_Obj12_Dy_Vnce "1023";
BA_ "GenSigCycleTime" SG_ 290 FR_Obj12_Dy_Vnce 60;
BA_ "GenSigCycleTime" SG_ 290 FR_Obj12_Dy 60;
BA_ "GenSigCycleTime" SG_ 290 FR_Obj12_HeadingAngle 60;
BA_ "GenSigCycleTime" SG_ 290 FR_Obj12_Length 60;
BA_ "GenSigCycleTime" SG_ 290 FR_Obj12_Height 60;
BA_ "GenSigCycleTime" SG_ 290 FR_Obj12_Width 60;
BA_ "GenSigCycleTime" SG_ 290 FR_Obj12_TypeProb 60;
BA_ "GenSigCycleTime" SG_ 290 FR_Obj12_Type 60;
BA_ "GenSigCycleTime" SG_ 292 FR_CRCCheck_124 60;
BA_ "GenSigCycleTime" SG_ 292 FR_RollingCounter_124 60;
BA_ "GenSigCycleTime" SG_ 292 FR_Obj14_Ax 60;
BA_ "GenSigCycleTime" SG_ 292 FR_Obj14_Ay 60;
BA_ "GenSigCycleTime" SG_ 292 FR_Obj14_Vx 60;
BA_ "GenSigCycleTime" SG_ 292 FR_Obj14_Vy 60;
BA_ "GenSigCycleTime" SG_ 292 FR_Obj14_DelayTime 60;
BA_ "GenSigCycleTime" SG_ 292 FR_Obj14_ReferPoint_Dx 60;
BA_ "GenSigCycleTime" SG_ 292 FR_Obj14_HeightGround 60;
BA_ "GenSigCycleTime" SG_ 292 FR_Obj14_MotionStatusConf 60;
BA_ "GenSigCycleTime" SG_ 292 FR_Obj14_MotionStatus 60;
BA_ "GenSigCycleTime" SG_ 292 FR_Obj14_Measured 60;
BA_ "GenSigCycleTime" SG_ 292 FR_Obj14_valid 60;
BA_ "GenSigCycleTime" SG_ 292 FR_Obj14_Track_Age 60;
BA_ "GenSigCycleTime" SG_ 292 FR_Obj14_Track_ID 60;
BA_ "GenSigCycleTime" SG_ 292 FR_Obj14_ObstacleProb 60;
BA_ "GenSigCycleTime" SG_ 292 FR_Obj14_ExistProb 60;
BA_ "GenSigCycleTime" SG_ 292 FR_Obj14_RelAx 60;
BA_ "GenSigCycleTime" SG_ 292 FR_Obj14_RelAy 60;
BA_ "GenSigInvalidValue" SG_ 292 FR_Obj14_RelVx_std "4095";
BA_ "GenSigCycleTime" SG_ 292 FR_Obj14_RelVx_std 60;
BA_ "GenSigCycleTime" SG_ 292 FR_Obj14_RelVx 60;
BA_ "GenSigInvalidValue" SG_ 292 FR_Obj14_RelVy_std "1023";
BA_ "GenSigCycleTime" SG_ 292 FR_Obj14_RelVy_std 60;
BA_ "GenSigCycleTime" SG_ 292 FR_Obj14_RelVy 60;
BA_ "GenSigInvalidValue" SG_ 292 FR_Obj14_Dx_Vnce "16383";
BA_ "GenSigCycleTime" SG_ 292 FR_Obj14_Dx_Vnce 60;
BA_ "GenSigCycleTime" SG_ 292 FR_Obj14_Dx 60;
BA_ "GenSigInvalidValue" SG_ 292 FR_Obj14_Dy_Vnce "1023";
BA_ "GenSigCycleTime" SG_ 292 FR_Obj14_Dy_Vnce 60;
BA_ "GenSigCycleTime" SG_ 292 FR_Obj14_Dy 60;
BA_ "GenSigCycleTime" SG_ 292 FR_Obj14_HeadingAngle 60;
BA_ "GenSigCycleTime" SG_ 292 FR_Obj14_Length 60;
BA_ "GenSigCycleTime" SG_ 292 FR_Obj14_Height 60;
BA_ "GenSigCycleTime" SG_ 292 FR_Obj14_Width 60;
BA_ "GenSigCycleTime" SG_ 292 FR_Obj14_TypeProb 60;
BA_ "GenSigCycleTime" SG_ 292 FR_Obj14_Type 60;
BA_ "GenSigCycleTime" SG_ 293 FR_CRCCheck_125 60;
BA_ "GenSigCycleTime" SG_ 293 FR_RollingCounter_125 60;
BA_ "GenSigCycleTime" SG_ 293 FR_Obj15_Ax 60;
BA_ "GenSigCycleTime" SG_ 293 FR_Obj15_Ay 60;
BA_ "GenSigCycleTime" SG_ 293 FR_Obj15_Vx 60;
BA_ "GenSigCycleTime" SG_ 293 FR_Obj15_Vy 60;
BA_ "GenSigCycleTime" SG_ 293 FR_Obj15_DelayTime 60;
BA_ "GenSigCycleTime" SG_ 293 FR_Obj15_ReferPoint_Dx 60;
BA_ "GenSigCycleTime" SG_ 293 FR_Obj15_HeightGround 60;
BA_ "GenSigCycleTime" SG_ 293 FR_Obj15_MotionStatusConf 60;
BA_ "GenSigCycleTime" SG_ 293 FR_Obj15_MotionStatus 60;
BA_ "GenSigCycleTime" SG_ 293 FR_Obj15_Measured 60;
BA_ "GenSigCycleTime" SG_ 293 FR_Obj15_valid 60;
BA_ "GenSigCycleTime" SG_ 293 FR_Obj15_Track_Age 60;
BA_ "GenSigCycleTime" SG_ 293 FR_Obj15_Track_ID 60;
BA_ "GenSigCycleTime" SG_ 293 FR_Obj15_ObstacleProb 60;
BA_ "GenSigCycleTime" SG_ 293 FR_Obj15_ExistProb 60;
BA_ "GenSigCycleTime" SG_ 293 FR_Obj15_RelAx 60;
BA_ "GenSigCycleTime" SG_ 293 FR_Obj15_RelAy 60;
BA_ "GenSigInvalidValue" SG_ 293 FR_Obj15_RelVx_std "4095";
BA_ "GenSigCycleTime" SG_ 293 FR_Obj15_RelVx_std 60;
BA_ "GenSigCycleTime" SG_ 293 FR_Obj15_RelVx 60;
BA_ "GenSigInvalidValue" SG_ 293 FR_Obj15_RelVy_std "1023";
BA_ "GenSigCycleTime" SG_ 293 FR_Obj15_RelVy_std 60;
BA_ "GenSigCycleTime" SG_ 293 FR_Obj15_RelVy 60;
BA_ "GenSigInvalidValue" SG_ 293 FR_Obj15_Dx_Vnce "16383";
BA_ "GenSigCycleTime" SG_ 293 FR_Obj15_Dx_Vnce 60;
BA_ "GenSigCycleTime" SG_ 293 FR_Obj15_Dx 60;
BA_ "GenSigInvalidValue" SG_ 293 FR_Obj15_Dy_Vnce "1023";
BA_ "GenSigCycleTime" SG_ 293 FR_Obj15_Dy_Vnce 60;
BA_ "GenSigCycleTime" SG_ 293 FR_Obj15_Dy 60;
BA_ "GenSigCycleTime" SG_ 293 FR_Obj15_HeadingAngle 60;
BA_ "GenSigCycleTime" SG_ 293 FR_Obj15_Length 60;
BA_ "GenSigCycleTime" SG_ 293 FR_Obj15_Height 60;
BA_ "GenSigCycleTime" SG_ 293 FR_Obj15_Width 60;
BA_ "GenSigCycleTime" SG_ 293 FR_Obj15_TypeProb 60;
BA_ "GenSigCycleTime" SG_ 293 FR_Obj15_Type 60;
BA_ "GenSigCycleTime" SG_ 294 FR_CRCCheck_126 60;
BA_ "GenSigCycleTime" SG_ 294 FR_RollingCounter_126 60;
BA_ "GenSigCycleTime" SG_ 294 FR_Obj16_Ax 60;
BA_ "GenSigCycleTime" SG_ 294 FR_Obj16_Ay 60;
BA_ "GenSigCycleTime" SG_ 294 FR_Obj16_Vx 60;
BA_ "GenSigCycleTime" SG_ 294 FR_Obj16_Vy 60;
BA_ "GenSigCycleTime" SG_ 294 FR_Obj16_DelayTime 60;
BA_ "GenSigCycleTime" SG_ 294 FR_Obj16_ReferPoint_Dx 60;
BA_ "GenSigCycleTime" SG_ 294 FR_Obj16_HeightGround 60;
BA_ "GenSigCycleTime" SG_ 294 FR_Obj16_MotionStatusConf 60;
BA_ "GenSigCycleTime" SG_ 294 FR_Obj16_MotionStatus 60;
BA_ "GenSigCycleTime" SG_ 294 FR_Obj16_Measured 60;
BA_ "GenSigCycleTime" SG_ 294 FR_Obj16_valid 60;
BA_ "GenSigCycleTime" SG_ 294 FR_Obj16_Track_Age 60;
BA_ "GenSigCycleTime" SG_ 294 FR_Obj16_Track_ID 60;
BA_ "GenSigCycleTime" SG_ 294 FR_Obj16_ObstacleProb 60;
BA_ "GenSigCycleTime" SG_ 294 FR_Obj16_ExistProb 60;
BA_ "GenSigCycleTime" SG_ 294 FR_Obj16_RelAx 60;
BA_ "GenSigCycleTime" SG_ 294 FR_Obj16_RelAy 60;
BA_ "GenSigInvalidValue" SG_ 294 FR_Obj16_RelVx_std "4095";
BA_ "GenSigCycleTime" SG_ 294 FR_Obj16_RelVx_std 60;
BA_ "GenSigCycleTime" SG_ 294 FR_Obj16_RelVx 60;
BA_ "GenSigInvalidValue" SG_ 294 FR_Obj16_RelVy_std "1023";
BA_ "GenSigCycleTime" SG_ 294 FR_Obj16_RelVy_std 60;
BA_ "GenSigCycleTime" SG_ 294 FR_Obj16_RelVy 60;
BA_ "GenSigInvalidValue" SG_ 294 FR_Obj16_Dx_Vnce "16383";
BA_ "GenSigCycleTime" SG_ 294 FR_Obj16_Dx_Vnce 60;
BA_ "GenSigCycleTime" SG_ 294 FR_Obj16_Dx 60;
BA_ "GenSigInvalidValue" SG_ 294 FR_Obj16_Dy_Vnce "1023";
BA_ "GenSigCycleTime" SG_ 294 FR_Obj16_Dy_Vnce 60;
BA_ "GenSigCycleTime" SG_ 294 FR_Obj16_Dy 60;
BA_ "GenSigCycleTime" SG_ 294 FR_Obj16_HeadingAngle 60;
BA_ "GenSigCycleTime" SG_ 294 FR_Obj16_Length 60;
BA_ "GenSigCycleTime" SG_ 294 FR_Obj16_Height 60;
BA_ "GenSigCycleTime" SG_ 294 FR_Obj16_Width 60;
BA_ "GenSigCycleTime" SG_ 294 FR_Obj16_TypeProb 60;
BA_ "GenSigCycleTime" SG_ 294 FR_Obj16_Type 60;
BA_ "GenSigCycleTime" SG_ 295 FR_CRCCheck_127 60;
BA_ "GenSigCycleTime" SG_ 295 FR_RollingCounter_127 60;
BA_ "GenSigCycleTime" SG_ 295 FR_Obj17_Ax 60;
BA_ "GenSigCycleTime" SG_ 295 FR_Obj17_Ay 60;
BA_ "GenSigCycleTime" SG_ 295 FR_Obj17_Vx 60;
BA_ "GenSigCycleTime" SG_ 295 FR_Obj17_Vy 60;
BA_ "GenSigCycleTime" SG_ 295 FR_Obj17_DelayTime 60;
BA_ "GenSigCycleTime" SG_ 295 FR_Obj17_ReferPoint_Dx 60;
BA_ "GenSigCycleTime" SG_ 295 FR_Obj17_HeightGround 60;
BA_ "GenSigCycleTime" SG_ 295 FR_Obj17_MotionStatusConf 60;
BA_ "GenSigCycleTime" SG_ 295 FR_Obj17_MotionStatus 60;
BA_ "GenSigCycleTime" SG_ 295 FR_Obj17_Measured 60;
BA_ "GenSigCycleTime" SG_ 295 FR_Obj17_valid 60;
BA_ "GenSigCycleTime" SG_ 295 FR_Obj17_Track_Age 60;
BA_ "GenSigCycleTime" SG_ 295 FR_Obj17_Track_ID 60;
BA_ "GenSigCycleTime" SG_ 295 FR_Obj17_ObstacleProb 60;
BA_ "GenSigCycleTime" SG_ 295 FR_Obj17_ExistProb 60;
BA_ "GenSigCycleTime" SG_ 295 FR_Obj17_RelAx 60;
BA_ "GenSigCycleTime" SG_ 295 FR_Obj17_RelAy 60;
BA_ "GenSigInvalidValue" SG_ 295 FR_Obj17_RelVx_std "4095";
BA_ "GenSigCycleTime" SG_ 295 FR_Obj17_RelVx_std 60;
BA_ "GenSigCycleTime" SG_ 295 FR_Obj17_RelVx 60;
BA_ "GenSigInvalidValue" SG_ 295 FR_Obj17_RelVy_std "1023";
BA_ "GenSigCycleTime" SG_ 295 FR_Obj17_RelVy_std 60;
BA_ "GenSigCycleTime" SG_ 295 FR_Obj17_RelVy 60;
BA_ "GenSigInvalidValue" SG_ 295 FR_Obj17_Dx_Vnce "16383";
BA_ "GenSigCycleTime" SG_ 295 FR_Obj17_Dx_Vnce 60;
BA_ "GenSigCycleTime" SG_ 295 FR_Obj17_Dx 60;
BA_ "GenSigInvalidValue" SG_ 295 FR_Obj17_Dy_Vnce "1023";
BA_ "GenSigCycleTime" SG_ 295 FR_Obj17_Dy_Vnce 60;
BA_ "GenSigCycleTime" SG_ 295 FR_Obj17_Dy 60;
BA_ "GenSigCycleTime" SG_ 295 FR_Obj17_HeadingAngle 60;
BA_ "GenSigCycleTime" SG_ 295 FR_Obj17_Length 60;
BA_ "GenSigCycleTime" SG_ 295 FR_Obj17_Height 60;
BA_ "GenSigCycleTime" SG_ 295 FR_Obj17_Width 60;
BA_ "GenSigCycleTime" SG_ 295 FR_Obj17_TypeProb 60;
BA_ "GenSigCycleTime" SG_ 295 FR_Obj17_Type 60;
BA_ "GenSigCycleTime" SG_ 296 FR_CRCCheck_128 60;
BA_ "GenSigCycleTime" SG_ 296 FR_RollingCounter_128 60;
BA_ "GenSigCycleTime" SG_ 296 FR_Obj18_Ax 60;
BA_ "GenSigCycleTime" SG_ 296 FR_Obj18_Ay 60;
BA_ "GenSigCycleTime" SG_ 296 FR_Obj18_Vx 60;
BA_ "GenSigCycleTime" SG_ 296 FR_Obj18_Vy 60;
BA_ "GenSigCycleTime" SG_ 296 FR_Obj18_DelayTime 60;
BA_ "GenSigCycleTime" SG_ 296 FR_Obj18_ReferPoint_Dx 60;
BA_ "GenSigCycleTime" SG_ 296 FR_Obj18_HeightGround 60;
BA_ "GenSigCycleTime" SG_ 296 FR_Obj18_MotionStatusConf 60;
BA_ "GenSigCycleTime" SG_ 296 FR_Obj18_MotionStatus 60;
BA_ "GenSigCycleTime" SG_ 296 FR_Obj18_Measured 60;
BA_ "GenSigCycleTime" SG_ 296 FR_Obj18_valid 60;
BA_ "GenSigCycleTime" SG_ 296 FR_Obj18_Track_Age 60;
BA_ "GenSigCycleTime" SG_ 296 FR_Obj18_Track_ID 60;
BA_ "GenSigCycleTime" SG_ 296 FR_Obj18_ObstacleProb 60;
BA_ "GenSigCycleTime" SG_ 296 FR_Obj18_ExistProb 60;
BA_ "GenSigCycleTime" SG_ 296 FR_Obj18_RelAx 60;
BA_ "GenSigCycleTime" SG_ 296 FR_Obj18_RelAy 60;
BA_ "GenSigInvalidValue" SG_ 296 FR_Obj18_RelVx_std "4095";
BA_ "GenSigCycleTime" SG_ 296 FR_Obj18_RelVx_std 60;
BA_ "GenSigCycleTime" SG_ 296 FR_Obj18_RelVx 60;
BA_ "GenSigInvalidValue" SG_ 296 FR_Obj18_RelVy_std "1023";
BA_ "GenSigCycleTime" SG_ 296 FR_Obj18_RelVy_std 60;
BA_ "GenSigCycleTime" SG_ 296 FR_Obj18_RelVy 60;
BA_ "GenSigInvalidValue" SG_ 296 FR_Obj18_Dx_Vnce "16383";
BA_ "GenSigCycleTime" SG_ 296 FR_Obj18_Dx_Vnce 60;
BA_ "GenSigCycleTime" SG_ 296 FR_Obj18_Dx 60;
BA_ "GenSigInvalidValue" SG_ 296 FR_Obj18_Dy_Vnce "1023";
BA_ "GenSigCycleTime" SG_ 296 FR_Obj18_Dy_Vnce 60;
BA_ "GenSigCycleTime" SG_ 296 FR_Obj18_Dy 60;
BA_ "GenSigCycleTime" SG_ 296 FR_Obj18_HeadingAngle 60;
BA_ "GenSigCycleTime" SG_ 296 FR_Obj18_Length 60;
BA_ "GenSigCycleTime" SG_ 296 FR_Obj18_Height 60;
BA_ "GenSigCycleTime" SG_ 296 FR_Obj18_Width 60;
BA_ "GenSigCycleTime" SG_ 296 FR_Obj18_TypeProb 60;
BA_ "GenSigCycleTime" SG_ 296 FR_Obj18_Type 60;
BA_ "GenSigCycleTime" SG_ 297 FR_CRCCheck_129 60;
BA_ "GenSigCycleTime" SG_ 297 FR_RollingCounter_129 60;
BA_ "GenSigCycleTime" SG_ 297 FR_Obj19_Ax 60;
BA_ "GenSigCycleTime" SG_ 297 FR_Obj19_Ay 60;
BA_ "GenSigCycleTime" SG_ 297 FR_Obj19_Vx 60;
BA_ "GenSigCycleTime" SG_ 297 FR_Obj19_Vy 60;
BA_ "GenSigCycleTime" SG_ 297 FR_Obj19_DelayTime 60;
BA_ "GenSigCycleTime" SG_ 297 FR_Obj19_ReferPoint_Dx 60;
BA_ "GenSigCycleTime" SG_ 297 FR_Obj19_HeightGround 60;
BA_ "GenSigCycleTime" SG_ 297 FR_Obj19_MotionStatusConf 60;
BA_ "GenSigCycleTime" SG_ 297 FR_Obj19_MotionStatus 60;
BA_ "GenSigCycleTime" SG_ 297 FR_Obj19_Measured 60;
BA_ "GenSigCycleTime" SG_ 297 FR_Obj19_valid 60;
BA_ "GenSigCycleTime" SG_ 297 FR_Obj19_Track_Age 60;
BA_ "GenSigCycleTime" SG_ 297 FR_Obj19_Track_ID 60;
BA_ "GenSigCycleTime" SG_ 297 FR_Obj19_ObstacleProb 60;
BA_ "GenSigCycleTime" SG_ 297 FR_Obj19_ExistProb 60;
BA_ "GenSigCycleTime" SG_ 297 FR_Obj19_RelAx 60;
BA_ "GenSigCycleTime" SG_ 297 FR_Obj19_RelAy 60;
BA_ "GenSigInvalidValue" SG_ 297 FR_Obj19_RelVx_std "4095";
BA_ "GenSigCycleTime" SG_ 297 FR_Obj19_RelVx_std 60;
BA_ "GenSigCycleTime" SG_ 297 FR_Obj19_RelVx 60;
BA_ "GenSigInvalidValue" SG_ 297 FR_Obj19_RelVy_std "1023";
BA_ "GenSigCycleTime" SG_ 297 FR_Obj19_RelVy_std 60;
BA_ "GenSigCycleTime" SG_ 297 FR_Obj19_RelVy 60;
BA_ "GenSigInvalidValue" SG_ 297 FR_Obj19_Dx_Vnce "16383";
BA_ "GenSigCycleTime" SG_ 297 FR_Obj19_Dx_Vnce 60;
BA_ "GenSigCycleTime" SG_ 297 FR_Obj19_Dx 60;
BA_ "GenSigInvalidValue" SG_ 297 FR_Obj19_Dy_Vnce "1023";
BA_ "GenSigCycleTime" SG_ 297 FR_Obj19_Dy_Vnce 60;
BA_ "GenSigCycleTime" SG_ 297 FR_Obj19_Dy 60;
BA_ "GenSigCycleTime" SG_ 297 FR_Obj19_HeadingAngle 60;
BA_ "GenSigCycleTime" SG_ 297 FR_Obj19_Length 60;
BA_ "GenSigCycleTime" SG_ 297 FR_Obj19_Height 60;
BA_ "GenSigCycleTime" SG_ 297 FR_Obj19_Width 60;
BA_ "GenSigCycleTime" SG_ 297 FR_Obj19_TypeProb 60;
BA_ "GenSigCycleTime" SG_ 297 FR_Obj19_Type 60;
BA_ "GenSigCycleTime" SG_ 298 FR_CRCCheck_12A 60;
BA_ "GenSigCycleTime" SG_ 298 FR_RollingCounter_12A 60;
BA_ "GenSigCycleTime" SG_ 298 FR_Obj13_Ax 60;
BA_ "GenSigCycleTime" SG_ 298 FR_Obj13_Ay 60;
BA_ "GenSigCycleTime" SG_ 298 FR_Obj13_Vx 60;
BA_ "GenSigCycleTime" SG_ 298 FR_Obj13_Vy 60;
BA_ "GenSigCycleTime" SG_ 298 FR_Obj13_DelayTime 60;
BA_ "GenSigCycleTime" SG_ 298 FR_Obj13_ReferPoint_Dx 60;
BA_ "GenSigCycleTime" SG_ 298 FR_Obj13_HeightGround 60;
BA_ "GenSigCycleTime" SG_ 298 FR_Obj13_MotionStatusConf 60;
BA_ "GenSigCycleTime" SG_ 298 FR_Obj13_MotionStatus 60;
BA_ "GenSigCycleTime" SG_ 298 FR_Obj13_Measured 60;
BA_ "GenSigCycleTime" SG_ 298 FR_Obj13_valid 60;
BA_ "GenSigCycleTime" SG_ 298 FR_Obj13_Track_Age 60;
BA_ "GenSigCycleTime" SG_ 298 FR_Obj13_Track_ID 60;
BA_ "GenSigCycleTime" SG_ 298 FR_Obj13_ObstacleProb 60;
BA_ "GenSigCycleTime" SG_ 298 FR_Obj13_ExistProb 60;
BA_ "GenSigCycleTime" SG_ 298 FR_Obj13_RelAx 60;
BA_ "GenSigCycleTime" SG_ 298 FR_Obj13_RelAy 60;
BA_ "GenSigInvalidValue" SG_ 298 FR_Obj13_RelVx_std "4095";
BA_ "GenSigCycleTime" SG_ 298 FR_Obj13_RelVx_std 60;
BA_ "GenSigCycleTime" SG_ 298 FR_Obj13_RelVx 60;
BA_ "GenSigInvalidValue" SG_ 298 FR_Obj13_RelVy_std "1023";
BA_ "GenSigCycleTime" SG_ 298 FR_Obj13_RelVy_std 60;
BA_ "GenSigCycleTime" SG_ 298 FR_Obj13_RelVy 60;
BA_ "GenSigInvalidValue" SG_ 298 FR_Obj13_Dx_Vnce "16383";
BA_ "GenSigCycleTime" SG_ 298 FR_Obj13_Dx_Vnce 60;
BA_ "GenSigCycleTime" SG_ 298 FR_Obj13_Dx 60;
BA_ "GenSigInvalidValue" SG_ 298 FR_Obj13_Dy_Vnce "1023";
BA_ "GenSigCycleTime" SG_ 298 FR_Obj13_Dy_Vnce 60;
BA_ "GenSigCycleTime" SG_ 298 FR_Obj13_Dy 60;
BA_ "GenSigCycleTime" SG_ 298 FR_Obj13_HeadingAngle 60;
BA_ "GenSigCycleTime" SG_ 298 FR_Obj13_Length 60;
BA_ "GenSigCycleTime" SG_ 298 FR_Obj13_Height 60;
BA_ "GenSigCycleTime" SG_ 298 FR_Obj13_Width 60;
BA_ "GenSigCycleTime" SG_ 298 FR_Obj13_TypeProb 60;
BA_ "GenSigCycleTime" SG_ 298 FR_Obj13_Type 60;
BA_ "GenSigCycleTime" SG_ 299 FR_CRCCheck_12B 60;
BA_ "GenSigCycleTime" SG_ 299 FR_RollingCounter_12B 60;
BA_ "GenSigCycleTime" SG_ 299 FR_Obj20_Ax 60;
BA_ "GenSigCycleTime" SG_ 299 FR_Obj20_Ay 60;
BA_ "GenSigCycleTime" SG_ 299 FR_Obj20_Vx 60;
BA_ "GenSigCycleTime" SG_ 299 FR_Obj20_Vy 60;
BA_ "GenSigCycleTime" SG_ 299 FR_Obj20_DelayTime 60;
BA_ "GenSigCycleTime" SG_ 299 FR_Obj20_ReferPoint_Dx 60;
BA_ "GenSigCycleTime" SG_ 299 FR_Obj20_HeightGround 60;
BA_ "GenSigCycleTime" SG_ 299 FR_Obj20_MotionStatusConf 60;
BA_ "GenSigCycleTime" SG_ 299 FR_Obj20_MotionStatus 60;
BA_ "GenSigCycleTime" SG_ 299 FR_Obj20_Measured 60;
BA_ "GenSigCycleTime" SG_ 299 FR_Obj20_valid 60;
BA_ "GenSigCycleTime" SG_ 299 FR_Obj20_Track_Age 60;
BA_ "GenSigCycleTime" SG_ 299 FR_Obj20_Track_ID 60;
BA_ "GenSigCycleTime" SG_ 299 FR_Obj20_ObstacleProb 60;
BA_ "GenSigCycleTime" SG_ 299 FR_Obj20_ExistProb 60;
BA_ "GenSigCycleTime" SG_ 299 FR_Obj20_RelAx 60;
BA_ "GenSigCycleTime" SG_ 299 FR_Obj20_RelAy 60;
BA_ "GenSigInvalidValue" SG_ 299 FR_Obj20_RelVx_std "4095";
BA_ "GenSigCycleTime" SG_ 299 FR_Obj20_RelVx_std 60;
BA_ "GenSigCycleTime" SG_ 299 FR_Obj20_RelVx 60;
BA_ "GenSigInvalidValue" SG_ 299 FR_Obj20_RelVy_std "1023";
BA_ "GenSigCycleTime" SG_ 299 FR_Obj20_RelVy_std 60;
BA_ "GenSigCycleTime" SG_ 299 FR_Obj20_RelVy 60;
BA_ "GenSigInvalidValue" SG_ 299 FR_Obj20_Dx_Vnce "16383";
BA_ "GenSigCycleTime" SG_ 299 FR_Obj20_Dx_Vnce 60;
BA_ "GenSigCycleTime" SG_ 299 FR_Obj20_Dx 60;
BA_ "GenSigInvalidValue" SG_ 299 FR_Obj20_Dy_Vnce "1023";
BA_ "GenSigCycleTime" SG_ 299 FR_Obj20_Dy_Vnce 60;
BA_ "GenSigCycleTime" SG_ 299 FR_Obj20_Dy 60;
BA_ "GenSigCycleTime" SG_ 299 FR_Obj20_HeadingAngle 60;
BA_ "GenSigCycleTime" SG_ 299 FR_Obj20_Length 60;
BA_ "GenSigCycleTime" SG_ 299 FR_Obj20_Height 60;
BA_ "GenSigCycleTime" SG_ 299 FR_Obj20_Width 60;
BA_ "GenSigCycleTime" SG_ 299 FR_Obj20_TypeProb 60;
BA_ "GenSigCycleTime" SG_ 299 FR_Obj20_Type 60;
BA_ "GenSigCycleTime" SG_ 300 FR_CRCCheck_12C 60;
BA_ "GenSigCycleTime" SG_ 300 FR_RollingCounter_12C 60;
BA_ "GenSigCycleTime" SG_ 300 FR_Obj21_Ax 60;
BA_ "GenSigCycleTime" SG_ 300 FR_Obj21_Ay 60;
BA_ "GenSigCycleTime" SG_ 300 FR_Obj21_Vx 60;
BA_ "GenSigCycleTime" SG_ 300 FR_Obj21_Vy 60;
BA_ "GenSigCycleTime" SG_ 300 FR_Obj21_DelayTime 60;
BA_ "GenSigCycleTime" SG_ 300 FR_Obj21_ReferPoint_Dx 60;
BA_ "GenSigCycleTime" SG_ 300 FR_Obj21_HeightGround 60;
BA_ "GenSigCycleTime" SG_ 300 FR_Obj21_MotionStatusConf 60;
BA_ "GenSigCycleTime" SG_ 300 FR_Obj21_MotionStatus 60;
BA_ "GenSigCycleTime" SG_ 300 FR_Obj21_Measured 60;
BA_ "GenSigCycleTime" SG_ 300 FR_Obj21_valid 60;
BA_ "GenSigCycleTime" SG_ 300 FR_Obj21_Track_Age 60;
BA_ "GenSigCycleTime" SG_ 300 FR_Obj21_Track_ID 60;
BA_ "GenSigCycleTime" SG_ 300 FR_Obj21_ObstacleProb 60;
BA_ "GenSigCycleTime" SG_ 300 FR_Obj21_ExistProb 60;
BA_ "GenSigCycleTime" SG_ 300 FR_Obj21_RelAx 60;
BA_ "GenSigCycleTime" SG_ 300 FR_Obj21_RelAy 60;
BA_ "GenSigInvalidValue" SG_ 300 FR_Obj21_RelVx_std "4095";
BA_ "GenSigCycleTime" SG_ 300 FR_Obj21_RelVx_std 60;
BA_ "GenSigCycleTime" SG_ 300 FR_Obj21_RelVx 60;
BA_ "GenSigInvalidValue" SG_ 300 FR_Obj21_RelVy_std "1023";
BA_ "GenSigCycleTime" SG_ 300 FR_Obj21_RelVy_std 60;
BA_ "GenSigCycleTime" SG_ 300 FR_Obj21_RelVy 60;
BA_ "GenSigInvalidValue" SG_ 300 FR_Obj21_Dx_Vnce "16383";
BA_ "GenSigCycleTime" SG_ 300 FR_Obj21_Dx_Vnce 60;
BA_ "GenSigCycleTime" SG_ 300 FR_Obj21_Dx 60;
BA_ "GenSigInvalidValue" SG_ 300 FR_Obj21_Dy_Vnce "1023";
BA_ "GenSigCycleTime" SG_ 300 FR_Obj21_Dy_Vnce 60;
BA_ "GenSigCycleTime" SG_ 300 FR_Obj21_Dy 60;
BA_ "GenSigCycleTime" SG_ 300 FR_Obj21_HeadingAngle 60;
BA_ "GenSigCycleTime" SG_ 300 FR_Obj21_Length 60;
BA_ "GenSigCycleTime" SG_ 300 FR_Obj21_Height 60;
BA_ "GenSigCycleTime" SG_ 300 FR_Obj21_Width 60;
BA_ "GenSigCycleTime" SG_ 300 FR_Obj21_TypeProb 60;
BA_ "GenSigCycleTime" SG_ 300 FR_Obj21_Type 60;
BA_ "GenSigCycleTime" SG_ 301 FR_CRCCheck_12D 60;
BA_ "GenSigCycleTime" SG_ 301 FR_RollingCounter_12D 60;
BA_ "GenSigCycleTime" SG_ 301 FR_Obj22_Ax 60;
BA_ "GenSigCycleTime" SG_ 301 FR_Obj22_Ay 60;
BA_ "GenSigCycleTime" SG_ 301 FR_Obj22_Vx 60;
BA_ "GenSigCycleTime" SG_ 301 FR_Obj22_Vy 60;
BA_ "GenSigCycleTime" SG_ 301 FR_Obj22_DelayTime 60;
BA_ "GenSigCycleTime" SG_ 301 FR_Obj22_ReferPoint_Dx 60;
BA_ "GenSigCycleTime" SG_ 301 FR_Obj22_HeightGround 60;
BA_ "GenSigCycleTime" SG_ 301 FR_Obj22_MotionStatusConf 60;
BA_ "GenSigCycleTime" SG_ 301 FR_Obj22_MotionStatus 60;
BA_ "GenSigCycleTime" SG_ 301 FR_Obj22_Measured 60;
BA_ "GenSigCycleTime" SG_ 301 FR_Obj22_valid 60;
BA_ "GenSigCycleTime" SG_ 301 FR_Obj22_Track_Age 60;
BA_ "GenSigCycleTime" SG_ 301 FR_Obj22_Track_ID 60;
BA_ "GenSigCycleTime" SG_ 301 FR_Obj22_ObstacleProb 60;
BA_ "GenSigCycleTime" SG_ 301 FR_Obj22_ExistProb 60;
BA_ "GenSigCycleTime" SG_ 301 FR_Obj22_RelAx 60;
BA_ "GenSigCycleTime" SG_ 301 FR_Obj22_RelAy 60;
BA_ "GenSigInvalidValue" SG_ 301 FR_Obj22_RelVx_std "4095";
BA_ "GenSigCycleTime" SG_ 301 FR_Obj22_RelVx_std 60;
BA_ "GenSigCycleTime" SG_ 301 FR_Obj22_RelVx 60;
BA_ "GenSigInvalidValue" SG_ 301 FR_Obj22_RelVy_std "1023";
BA_ "GenSigCycleTime" SG_ 301 FR_Obj22_RelVy_std 60;
BA_ "GenSigCycleTime" SG_ 301 FR_Obj22_RelVy 60;
BA_ "GenSigInvalidValue" SG_ 301 FR_Obj22_Dx_Vnce "16383";
BA_ "GenSigCycleTime" SG_ 301 FR_Obj22_Dx_Vnce 60;
BA_ "GenSigCycleTime" SG_ 301 FR_Obj22_Dx 60;
BA_ "GenSigInvalidValue" SG_ 301 FR_Obj22_Dy_Vnce "1023";
BA_ "GenSigCycleTime" SG_ 301 FR_Obj22_Dy_Vnce 60;
BA_ "GenSigCycleTime" SG_ 301 FR_Obj22_Dy 60;
BA_ "GenSigCycleTime" SG_ 301 FR_Obj22_HeadingAngle 60;
BA_ "GenSigCycleTime" SG_ 301 FR_Obj22_Length 60;
BA_ "GenSigCycleTime" SG_ 301 FR_Obj22_Height 60;
BA_ "GenSigCycleTime" SG_ 301 FR_Obj22_Width 60;
BA_ "GenSigCycleTime" SG_ 301 FR_Obj22_TypeProb 60;
BA_ "GenSigCycleTime" SG_ 301 FR_Obj22_Type 60;
BA_ "GenSigCycleTime" SG_ 302 FR_CRCCheck_12E 60;
BA_ "GenSigCycleTime" SG_ 302 FR_RollingCounter_12E 60;
BA_ "GenSigCycleTime" SG_ 302 FR_Obj23_Ax 60;
BA_ "GenSigCycleTime" SG_ 302 FR_Obj23_Ay 60;
BA_ "GenSigCycleTime" SG_ 302 FR_Obj23_Vx 60;
BA_ "GenSigCycleTime" SG_ 302 FR_Obj23_Vy 60;
BA_ "GenSigCycleTime" SG_ 302 FR_Obj23_DelayTime 60;
BA_ "GenSigCycleTime" SG_ 302 FR_Obj23_ReferPoint_Dx 60;
BA_ "GenSigCycleTime" SG_ 302 FR_Obj23_HeightGround 60;
BA_ "GenSigCycleTime" SG_ 302 FR_Obj23_MotionStatusConf 60;
BA_ "GenSigCycleTime" SG_ 302 FR_Obj23_MotionStatus 60;
BA_ "GenSigCycleTime" SG_ 302 FR_Obj23_Measured 60;
BA_ "GenSigCycleTime" SG_ 302 FR_Obj23_valid 60;
BA_ "GenSigCycleTime" SG_ 302 FR_Obj23_Track_Age 60;
BA_ "GenSigCycleTime" SG_ 302 FR_Obj23_Track_ID 60;
BA_ "GenSigCycleTime" SG_ 302 FR_Obj23_ObstacleProb 60;
BA_ "GenSigCycleTime" SG_ 302 FR_Obj23_ExistProb 60;
BA_ "GenSigCycleTime" SG_ 302 FR_Obj23_RelAx 60;
BA_ "GenSigCycleTime" SG_ 302 FR_Obj23_RelAy 60;
BA_ "GenSigInvalidValue" SG_ 302 FR_Obj23_RelVx_std "4095";
BA_ "GenSigCycleTime" SG_ 302 FR_Obj23_RelVx_std 60;
BA_ "GenSigCycleTime" SG_ 302 FR_Obj23_RelVx 60;
BA_ "GenSigInvalidValue" SG_ 302 FR_Obj23_RelVy_std "1023";
BA_ "GenSigCycleTime" SG_ 302 FR_Obj23_RelVy_std 60;
BA_ "GenSigCycleTime" SG_ 302 FR_Obj23_RelVy 60;
BA_ "GenSigInvalidValue" SG_ 302 FR_Obj23_Dx_Vnce "16383";
BA_ "GenSigCycleTime" SG_ 302 FR_Obj23_Dx_Vnce 60;
BA_ "GenSigCycleTime" SG_ 302 FR_Obj23_Dx 60;
BA_ "GenSigInvalidValue" SG_ 302 FR_Obj23_Dy_Vnce "1023";
BA_ "GenSigCycleTime" SG_ 302 FR_Obj23_Dy_Vnce 60;
BA_ "GenSigCycleTime" SG_ 302 FR_Obj23_Dy 60;
BA_ "GenSigCycleTime" SG_ 302 FR_Obj23_HeadingAngle 60;
BA_ "GenSigCycleTime" SG_ 302 FR_Obj23_Length 60;
BA_ "GenSigCycleTime" SG_ 302 FR_Obj23_Height 60;
BA_ "GenSigCycleTime" SG_ 302 FR_Obj23_Width 60;
BA_ "GenSigCycleTime" SG_ 302 FR_Obj23_TypeProb 60;
BA_ "GenSigCycleTime" SG_ 302 FR_Obj23_Type 60;
BA_ "GenSigCycleTime" SG_ 303 FR_CRCCheck_12F 60;
BA_ "GenSigCycleTime" SG_ 303 FR_RollingCounter_12F 60;
BA_ "GenSigCycleTime" SG_ 303 FR_Obj24_Ax 60;
BA_ "GenSigCycleTime" SG_ 303 FR_Obj24_Ay 60;
BA_ "GenSigCycleTime" SG_ 303 FR_Obj24_Vx 60;
BA_ "GenSigCycleTime" SG_ 303 FR_Obj24_Vy 60;
BA_ "GenSigCycleTime" SG_ 303 FR_Obj24_DelayTime 60;
BA_ "GenSigCycleTime" SG_ 303 FR_Obj24_ReferPoint_Dx 60;
BA_ "GenSigCycleTime" SG_ 303 FR_Obj24_HeightGround 60;
BA_ "GenSigCycleTime" SG_ 303 FR_Obj24_MotionStatusConf 60;
BA_ "GenSigCycleTime" SG_ 303 FR_Obj24_MotionStatus 60;
BA_ "GenSigCycleTime" SG_ 303 FR_Obj24_Measured 60;
BA_ "GenSigCycleTime" SG_ 303 FR_Obj24_valid 60;
BA_ "GenSigCycleTime" SG_ 303 FR_Obj24_Track_Age 60;
BA_ "GenSigCycleTime" SG_ 303 FR_Obj24_Track_ID 60;
BA_ "GenSigCycleTime" SG_ 303 FR_Obj24_ObstacleProb 60;
BA_ "GenSigCycleTime" SG_ 303 FR_Obj24_ExistProb 60;
BA_ "GenSigCycleTime" SG_ 303 FR_Obj24_RelAx 60;
BA_ "GenSigCycleTime" SG_ 303 FR_Obj24_RelAy 60;
BA_ "GenSigInvalidValue" SG_ 303 FR_Obj24_RelVx_std "4095";
BA_ "GenSigCycleTime" SG_ 303 FR_Obj24_RelVx_std 60;
BA_ "GenSigCycleTime" SG_ 303 FR_Obj24_RelVx 60;
BA_ "GenSigInvalidValue" SG_ 303 FR_Obj24_RelVy_std "1023";
BA_ "GenSigCycleTime" SG_ 303 FR_Obj24_RelVy_std 60;
BA_ "GenSigCycleTime" SG_ 303 FR_Obj24_RelVy 60;
BA_ "GenSigInvalidValue" SG_ 303 FR_Obj24_Dx_Vnce "16383";
BA_ "GenSigCycleTime" SG_ 303 FR_Obj24_Dx_Vnce 60;
BA_ "GenSigCycleTime" SG_ 303 FR_Obj24_Dx 60;
BA_ "GenSigInvalidValue" SG_ 303 FR_Obj24_Dy_Vnce "1023";
BA_ "GenSigCycleTime" SG_ 303 FR_Obj24_Dy_Vnce 60;
BA_ "GenSigCycleTime" SG_ 303 FR_Obj24_Dy 60;
BA_ "GenSigCycleTime" SG_ 303 FR_Obj24_HeadingAngle 60;
BA_ "GenSigCycleTime" SG_ 303 FR_Obj24_Length 60;
BA_ "GenSigCycleTime" SG_ 303 FR_Obj24_Height 60;
BA_ "GenSigCycleTime" SG_ 303 FR_Obj24_Width 60;
BA_ "GenSigCycleTime" SG_ 303 FR_Obj24_TypeProb 60;
BA_ "GenSigCycleTime" SG_ 303 FR_Obj24_Type 60;
BA_ "GenSigInvalidValue" SG_ 338 ADC_SenceMode "0";
BA_ "GenSigCycleTime" SG_ 338 ADC_SenceMode 10;
BA_ "GenSigInvalidValue" SG_ 338 AD_Reqmode "3";
BA_ "GenSigCycleTime" SG_ 338 AD_Reqmode 10;
BA_ "GenSigCycleTime" SG_ 349 ESP_Calibrated 10;
BA_ "GenSigCycleTime" SG_ 349 ESP_CRCCheck_15D 10;
BA_ "GenSigCycleTime" SG_ 349 ESP_RollingCounter_15D 10;
BA_ "GenSigCycleTime" SG_ 349 ESP_YawRateValid 10;
BA_ "GenSigInvalidValue" SG_ 349 ESP_YawRate "16383";
BA_ "GenSigCycleTime" SG_ 349 ESP_YawRate 10;
BA_ "GenSigCycleTime" SG_ 349 ESP_LongAccelValid 10;
BA_ "GenSigInvalidValue" SG_ 349 ESP_LongAccel "1023";
BA_ "GenSigCycleTime" SG_ 349 ESP_LongAccel 10;
BA_ "GenSigCycleTime" SG_ 349 ESP_LatAccelValid 10;
BA_ "GenSigInvalidValue" SG_ 349 ESP_LatAccel "255";
BA_ "GenSigCycleTime" SG_ 349 ESP_LatAccel 10;
BA_ "GenSigSendType" SG_ 377 ADC_SYNC_Sync_Time 1;
BA_ "GenSigSendType" SG_ 377 ADC_SYNC_UserByte_OVS_SGW 1;
BA_ "GenSigSendType" SG_ 377 ADC_SYNC_TimeDomain 1;
BA_ "GenSigSendType" SG_ 377 ADC_SYNC_Sequence 1;
BA_ "GenSigSendType" SG_ 377 ADC_SYNC_CRC 1;
BA_ "GenSigSendType" SG_ 377 ADC_SYNC_Type 1;
BA_ "GenSigInvalidValue" SG_ 384 EpsSteerAgSensFilr "1";
BA_ "GenSigCycleTime" SG_ 384 EpsSteerAgSensFilr 10;
BA_ "GenSigCycleTime" SG_ 384 EpsSasCalSts 10;
BA_ "GenSigInvalidValue" SG_ 384 EpsSasSteerAgVld "1";
BA_ "GenSigCycleTime" SG_ 384 EpsSasSteerAgVld 10;
BA_ "GenSigInvalidValue" SG_ 384 EpsSasSteerAg "32767";
BA_ "GenSigCycleTime" SG_ 384 EpsSasSteerAg 10;
BA_ "GenSigInvalidValue" SG_ 384 EpsSteerAgRate "255";
BA_ "GenSigCycleTime" SG_ 384 EpsSteerAgRate 10;
BA_ "GenSigCycleTime" SG_ 384 EPS_CRCCheck_180 10;
BA_ "GenSigCycleTime" SG_ 384 EPS_RollingCounter_180 10;
BA_ "GenSigInvalidValue" SG_ 433 VcuAccrPedlPosnVld "1";
BA_ "GenSigCycleTime" SG_ 433 VcuAccrPedlPosnVld 10;
BA_ "GenSigInvalidValue" SG_ 433 VcuAccrPedlPosn "1023";
BA_ "GenSigCycleTime" SG_ 433 VcuAccrPedlPosn 10;
BA_ "GenSigInvalidValue" SG_ 433 VcuRdySts "NA";
BA_ "GenSigCycleTime" SG_ 433 VcuRdySts 10;
BA_ "GenSigInvalidValue" SG_ 433 VcuVehGearPosnVld "1";
BA_ "GenSigCycleTime" SG_ 433 VcuVehGearPosnVld 10;
BA_ "GenSigInvalidValue" SG_ 433 VcuGearPosn "NA";
BA_ "GenSigCycleTime" SG_ 433 VcuGearPosn 10;
BA_ "GenSigInvalidValue" SG_ 433 VCU_CRCCheck_1B1 "NA";
BA_ "GenSigCycleTime" SG_ 433 VCU_CRCCheck_1B1 10;
BA_ "GenSigInvalidValue" SG_ 433 VCU_RollingCounter_1B1 "NA";
BA_ "GenSigCycleTime" SG_ 433 VCU_RollingCounter_1B1 10;
BA_ "GenSigInvalidValue" SG_ 450 WhlSpdReRiPls "NA";
BA_ "GenSigCycleTime" SG_ 450 WhlSpdReRiPls 10;
BA_ "GenSigInvalidValue" SG_ 450 WhlSpdRiReDir "3";
BA_ "GenSigCycleTime" SG_ 450 WhlSpdRiReDir 10;
BA_ "GenSigInvalidValue" SG_ 450 WhlSpdRiReDataVld "1";
BA_ "GenSigCycleTime" SG_ 450 WhlSpdRiReDataVld 10;
BA_ "GenSigInvalidValue" SG_ 450 WhlSpdRiReData "8191";
BA_ "GenSigCycleTime" SG_ 450 WhlSpdRiReData 10;
BA_ "GenSigInvalidValue" SG_ 450 WhlSpdReLePls "255";
BA_ "GenSigCycleTime" SG_ 450 WhlSpdReLePls 10;
BA_ "GenSigInvalidValue" SG_ 450 WhlSpdLeReDir "3";
BA_ "GenSigCycleTime" SG_ 450 WhlSpdLeReDir 10;
BA_ "GenSigInvalidValue" SG_ 450 WhlSpdLeReDataVld "1";
BA_ "GenSigCycleTime" SG_ 450 WhlSpdLeReDataVld 10;
BA_ "GenSigInvalidValue" SG_ 450 WhlSpdLeReData "8191";
BA_ "GenSigCycleTime" SG_ 450 WhlSpdLeReData 10;
BA_ "GenSigInvalidValue" SG_ 450 WhlSpdFrntRiPls "NA";
BA_ "GenSigCycleTime" SG_ 450 WhlSpdFrntRiPls 10;
BA_ "GenSigInvalidValue" SG_ 450 WhlSpdRiFrntDir "3";
BA_ "GenSigCycleTime" SG_ 450 WhlSpdRiFrntDir 10;
BA_ "GenSigInvalidValue" SG_ 450 WhlSpdRiFrntDataVld "1";
BA_ "GenSigCycleTime" SG_ 450 WhlSpdRiFrntDataVld 10;
BA_ "GenSigInvalidValue" SG_ 450 WhlSpdRiFrntData "8191";
BA_ "GenSigCycleTime" SG_ 450 WhlSpdRiFrntData 10;
BA_ "GenSigInvalidValue" SG_ 450 WhlSpdFrntLePls "255";
BA_ "GenSigCycleTime" SG_ 450 WhlSpdFrntLePls 10;
BA_ "GenSigInvalidValue" SG_ 450 WhlSpdLeFrntDir "3";
BA_ "GenSigCycleTime" SG_ 450 WhlSpdLeFrntDir 10;
BA_ "GenSigInvalidValue" SG_ 450 WhlSpdLeFrntDataVld "1";
BA_ "GenSigCycleTime" SG_ 450 WhlSpdLeFrntDataVld 10;
BA_ "GenSigInvalidValue" SG_ 450 WhlSpdLeFrntData "8191";
BA_ "GenSigCycleTime" SG_ 450 WhlSpdLeFrntData 10;
BA_ "GenSigInvalidValue" SG_ 450 EspVehStandstill "NA";
BA_ "GenSigCycleTime" SG_ 450 EspVehStandstill 10;
BA_ "GenSigInvalidValue" SG_ 450 EspVehSpdVld "1";
BA_ "GenSigCycleTime" SG_ 450 EspVehSpdVld 10;
BA_ "GenSigInvalidValue" SG_ 450 EspVehSpd "8191";
BA_ "GenSigCycleTime" SG_ 450 EspVehSpd 10;
BA_ "GenSigInvalidValue" SG_ 450 ESP_RollingCounter_1C2 "NA";
BA_ "GenSigCycleTime" SG_ 450 ESP_RollingCounter_1C2 10;
BA_ "GenSigInvalidValue" SG_ 450 ESP_CRCCheck_1C2 "NA";
BA_ "GenSigCycleTime" SG_ 450 ESP_CRCCheck_1C2 10;
VAL_ 273 FR_Obj1_ReferPoint_Dx 0 "参考点未知
0x1=后方左角点
0x2=后方中心
0x3=后方右角点
0x4=左边中心
0x5=中心
0x6=右边中心
0x7=前方左角点
0x8=前方中心
0x9=前方右角点
0x10=前轮
0x11=后轮
0x12=内部轮" ;
VAL_ 273 FR_Obj1_MotionStatus 0 "unknown" 1 "moving " 2 "stopped" 3 "stationary" 4 "crossing" 5 "reserve;" ;
VAL_ 273 FR_Obj1_Measured 0 "unknown" 1 "Measured" 2 "Predicted" 3 "Reserved" ;
VAL_ 273 FR_Obj1_valid 0 "" ;
VAL_ 273 FR_Obj1_Type 0 "Not Detected" 1 "car" 2 "truck" 3 "bicycle/motorbike" 4 "pedestrian" 5 "tricycle" 6 "animal" 7 "uncertain" ;
VAL_ 274 FR_Obj2_ReferPoint_Dx 0 "参考点未知
0x1=后方左角点
0x2=后方中心
0x3=后方右角点
0x4=左边中心
0x5=中心
0x6=右边中心
0x7=前方左角点
0x8=前方中心
0x9=前方右角点
0x10=前轮
0x11=后轮
0x12=内部轮" ;
VAL_ 274 FR_Obj2_MotionStatus 0 "unknown" 1 "moving " 2 "stopped" 3 "stationary" 4 "crossing" 5 "reserve;" ;
VAL_ 274 FR_Obj2_Measured 0 "unknown" 1 "Measured" 2 "Predicted" 3 "Reserved" ;
VAL_ 274 FR_Obj2_valid 0 "" ;
VAL_ 274 FR_Obj2_Type 0 "Not Detected" 1 "car" 2 "truck" 3 "bicycle/motorbike" 4 "pedestrian" 5 "tricycle" 6 "animal" 7 "uncertain" ;
VAL_ 275 FR_Obj3_ReferPoint_Dx 0 "参考点未知
0x1=后方左角点
0x2=后方中心
0x3=后方右角点
0x4=左边中心
0x5=中心
0x6=右边中心
0x7=前方左角点
0x8=前方中心
0x9=前方右角点
0x10=前轮
0x11=后轮
0x12=内部轮" ;
VAL_ 275 FR_Obj3_MotionStatus 0 "unknown" 1 "moving " 2 "stopped" 3 "stationary" 4 "crossing" 5 "reserve;" ;
VAL_ 275 FR_Obj3_Measured 0 "unknown" 1 "Measured" 2 "Predicted" 3 "Reserved" ;
VAL_ 275 FR_Obj3_valid 0 "" ;
VAL_ 275 FR_Obj3_Type 0 "Not Detected" 1 "car" 2 "truck" 3 "bicycle/motorbike" 4 "pedestrian" 5 "tricycle" 6 "animal" 7 "uncertain" ;
VAL_ 276 FR_Obj4_ReferPoint_Dx 0 "参考点未知
0x1=后方左角点
0x2=后方中心
0x3=后方右角点
0x4=左边中心
0x5=中心
0x6=右边中心
0x7=前方左角点
0x8=前方中心
0x9=前方右角点
0x10=前轮
0x11=后轮
0x12=内部轮" ;
VAL_ 276 FR_Obj4_MotionStatus 0 "unknown" 1 "moving " 2 "stopped" 3 "stationary" 4 "crossing" 5 "reserve;" ;
VAL_ 276 FR_Obj4_Measured 0 "unknown" 1 "Measured" 2 "Predicted" 3 "Reserved" ;
VAL_ 276 FR_Obj4_valid 0 "" ;
VAL_ 276 FR_Obj4_Type 0 "Not Detected" 1 "car" 2 "truck" 3 "bicycle/motorbike" 4 "pedestrian" 5 "tricycle" 6 "animal" 7 "uncertain" ;
VAL_ 277 FR_Obj5_ReferPoint_Dx 0 "参考点未知
0x1=后方左角点
0x2=后方中心
0x3=后方右角点
0x4=左边中心
0x5=中心
0x6=右边中心
0x7=前方左角点
0x8=前方中心
0x9=前方右角点
0x10=前轮
0x11=后轮
0x12=内部轮" ;
VAL_ 277 FR_Obj5_MotionStatus 0 "unknown" 1 "moving " 2 "stopped" 3 "stationary" 4 "crossing" 5 "reserve;" ;
VAL_ 277 FR_Obj5_Measured 0 "unknown" 1 "Measured" 2 "Predicted" 3 "Reserved" ;
VAL_ 277 FR_Obj5_valid 0 "" ;
VAL_ 277 FR_Obj5_Type 0 "Not Detected" 1 "car" 2 "truck" 3 "bicycle/motorbike" 4 "pedestrian" 5 "tricycle" 6 "animal" 7 "uncertain" ;
VAL_ 278 FR_Obj6_ReferPoint_Dx 0 "参考点未知
0x1=后方左角点
0x2=后方中心
0x3=后方右角点
0x4=左边中心
0x5=中心
0x6=右边中心
0x7=前方左角点
0x8=前方中心
0x9=前方右角点
0x10=前轮
0x11=后轮
0x12=内部轮" ;
VAL_ 278 FR_Obj6_MotionStatus 0 "unknown" 1 "moving " 2 "stopped" 3 "stationary" 4 "crossing" 5 "reserve;" ;
VAL_ 278 FR_Obj6_Measured 0 "unknown" 1 "Measured" 2 "Predicted" 3 "Reserved" ;
VAL_ 278 FR_Obj6_valid 0 "" ;
VAL_ 278 FR_Obj6_Type 0 "Not Detected" 1 "car" 2 "truck" 3 "bicycle/motorbike" 4 "pedestrian" 5 "tricycle" 6 "animal" 7 "uncertain" ;
VAL_ 279 FR_Obj7_ReferPoint_Dx 0 "参考点未知
0x1=后方左角点
0x2=后方中心
0x3=后方右角点
0x4=左边中心
0x5=中心
0x6=右边中心
0x7=前方左角点
0x8=前方中心
0x9=前方右角点
0x10=前轮
0x11=后轮
0x12=内部轮" ;
VAL_ 279 FR_Obj7_MotionStatus 0 "unknown" 1 "moving " 2 "stopped" 3 "stationary" 4 "crossing" 5 "reserve;" ;
VAL_ 279 FR_Obj7_Measured 0 "unknown" 1 "Measured" 2 "Predicted" 3 "Reserved" ;
VAL_ 279 FR_Obj7_valid 0 "" ;
VAL_ 279 FR_Obj7_Type 0 "Not Detected" 1 "car" 2 "truck" 3 "bicycle/motorbike" 4 "pedestrian" 5 "tricycle" 6 "animal" 7 "uncertain" ;
VAL_ 280 FR_Obj8_ReferPoint_Dx 0 "参考点未知
0x1=后方左角点
0x2=后方中心
0x3=后方右角点
0x4=左边中心
0x5=中心
0x6=右边中心
0x7=前方左角点
0x8=前方中心
0x9=前方右角点
0x10=前轮
0x11=后轮
0x12=内部轮" ;
VAL_ 280 FR_Obj8_MotionStatus 0 "unknown" 1 "moving " 2 "stopped" 3 "stationary" 4 "crossing" 5 "reserve;" ;
VAL_ 280 FR_Obj8_Measured 0 "unknown" 1 "Measured" 2 "Predicted" 3 "Reserved" ;
VAL_ 280 FR_Obj8_valid 0 "" ;
VAL_ 280 FR_Obj8_Type 0 "Not Detected" 1 "car" 2 "truck" 3 "bicycle/motorbike" 4 "pedestrian" 5 "tricycle" 6 "animal" 7 "uncertain" ;
VAL_ 281 FR_Obj9_ReferPoint_Dx 0 "参考点未知
0x1=后方左角点
0x2=后方中心
0x3=后方右角点
0x4=左边中心
0x5=中心
0x6=右边中心
0x7=前方左角点
0x8=前方中心
0x9=前方右角点
0x10=前轮
0x11=后轮
0x12=内部轮" ;
VAL_ 281 FR_Obj9_MotionStatus 0 "unknown" 1 "moving " 2 "stopped" 3 "stationary" 4 "crossing" 5 "reserve;" ;
VAL_ 281 FR_Obj9_Measured 0 "unknown" 1 "Measured" 2 "Predicted" 3 "Reserved" ;
VAL_ 281 FR_Obj9_valid 0 "" ;
VAL_ 281 FR_Obj9_Type 0 "Not Detected" 1 "car" 2 "truck" 3 "bicycle/motorbike" 4 "pedestrian" 5 "tricycle" 6 "animal" 7 "uncertain" ;
VAL_ 288 FR_Obj10_ReferPoint_Dx 0 "参考点未知
0x1=后方左角点
0x2=后方中心
0x3=后方右角点
0x4=左边中心
0x5=中心
0x6=右边中心
0x7=前方左角点
0x8=前方中心
0x9=前方右角点
0x10=前轮
0x11=后轮
0x12=内部轮" ;
VAL_ 288 FR_Obj10_MotionStatus 0 "unknown" 1 "moving " 2 "stopped" 3 "stationary" 4 "crossing" 5 "reserve;" ;
VAL_ 288 FR_Obj10_Measured 0 "unknown" 1 "Measured" 2 "Predicted" 3 "Reserved" ;
VAL_ 288 FR_Obj10_valid 0 "" ;
VAL_ 288 FR_Obj10_Type 0 "Not Detected" 1 "car" 2 "truck" 3 "bicycle/motorbike" 4 "pedestrian" 5 "tricycle" 6 "animal" 7 "uncertain" ;
VAL_ 289 FR_Obj11_ReferPoint_Dx 0 "参考点未知
0x1=后方左角点
0x2=后方中心
0x3=后方右角点
0x4=左边中心
0x5=中心
0x6=右边中心
0x7=前方左角点
0x8=前方中心
0x9=前方右角点
0x10=前轮
0x11=后轮
0x12=内部轮" ;
VAL_ 289 FR_Obj11_MotionStatus 0 "unknown" 1 "moving " 2 "stopped" 3 "stationary" 4 "crossing" 5 "reserve;" ;
VAL_ 289 FR_Obj11_Measured 0 "unknown" 1 "Measured" 2 "Predicted" 3 "Reserved" ;
VAL_ 289 FR_Obj11_valid 0 "" ;
VAL_ 289 FR_Obj11_Type 0 "Not Detected" 1 "car" 2 "truck" 3 "bicycle/motorbike" 4 "pedestrian" 5 "tricycle" 6 "animal" 7 "uncertain" ;
VAL_ 290 FR_Obj12_ReferPoint_Dx 0 "参考点未知
0x1=后方左角点
0x2=后方中心
0x3=后方右角点
0x4=左边中心
0x5=中心
0x6=右边中心
0x7=前方左角点
0x8=前方中心
0x9=前方右角点
0x10=前轮
0x11=后轮
0x12=内部轮" ;
VAL_ 290 FR_Obj12_MotionStatus 0 "unknown" 1 "moving " 2 "stopped" 3 "stationary" 4 "crossing" 5 "reserve;" ;
VAL_ 290 FR_Obj12_Measured 0 "unknown" 1 "Measured" 2 "Predicted" 3 "Reserved" ;
VAL_ 290 FR_Obj12_valid 0 "" ;
VAL_ 290 FR_Obj12_Type 0 "Not Detected" 1 "car" 2 "truck" 3 "bicycle/motorbike" 4 "pedestrian" 5 "tricycle" 6 "animal" 7 "uncertain" ;
VAL_ 292 FR_Obj14_ReferPoint_Dx 0 "参考点未知
0x1=后方左角点
0x2=后方中心
0x3=后方右角点
0x4=左边中心
0x5=中心
0x6=右边中心
0x7=前方左角点
0x8=前方中心
0x9=前方右角点
0x10=前轮
0x11=后轮
0x12=内部轮" ;
VAL_ 292 FR_Obj14_MotionStatus 0 "unknown" 1 "moving " 2 "stopped" 3 "stationary" 4 "crossing" 5 "reserve;" ;
VAL_ 292 FR_Obj14_Measured 0 "unknown" 1 "Measured" 2 "Predicted" 3 "Reserved" ;
VAL_ 292 FR_Obj14_valid 0 "" ;
VAL_ 292 FR_Obj14_Type 0 "Not Detected" 1 "car" 2 "truck" 3 "bicycle/motorbike" 4 "pedestrian" 5 "tricycle" 6 "animal" 7 "uncertain" ;
VAL_ 293 FR_Obj15_ReferPoint_Dx 0 "参考点未知
0x1=后方左角点
0x2=后方中心
0x3=后方右角点
0x4=左边中心
0x5=中心
0x6=右边中心
0x7=前方左角点
0x8=前方中心
0x9=前方右角点
0x10=前轮
0x11=后轮
0x12=内部轮" ;
VAL_ 293 FR_Obj15_MotionStatus 0 "unknown" 1 "moving " 2 "stopped" 3 "stationary" 4 "crossing" 5 "reserve;" ;
VAL_ 293 FR_Obj15_Measured 0 "unknown" 1 "Measured" 2 "Predicted" 3 "Reserved" ;
VAL_ 293 FR_Obj15_valid 0 "" ;
VAL_ 293 FR_Obj15_Type 0 "Not Detected" 1 "car" 2 "truck" 3 "bicycle/motorbike" 4 "pedestrian" 5 "tricycle" 6 "animal" 7 "uncertain" ;
VAL_ 294 FR_Obj16_ReferPoint_Dx 0 "参考点未知
0x1=后方左角点
0x2=后方中心
0x3=后方右角点
0x4=左边中心
0x5=中心
0x6=右边中心
0x7=前方左角点
0x8=前方中心
0x9=前方右角点
0x10=前轮
0x11=后轮
0x12=内部轮" ;
VAL_ 294 FR_Obj16_MotionStatus 0 "unknown" 1 "moving " 2 "stopped" 3 "stationary" 4 "crossing" 5 "reserve;" ;
VAL_ 294 FR_Obj16_Measured 0 "unknown" 1 "Measured" 2 "Predicted" 3 "Reserved" ;
VAL_ 294 FR_Obj16_valid 0 "" ;
VAL_ 294 FR_Obj16_Type 0 "Not Detected" 1 "car" 2 "truck" 3 "bicycle/motorbike" 4 "pedestrian" 5 "tricycle" 6 "animal" 7 "uncertain" ;
VAL_ 295 FR_Obj17_ReferPoint_Dx 0 "参考点未知
0x1=后方左角点
0x2=后方中心
0x3=后方右角点
0x4=左边中心
0x5=中心
0x6=右边中心
0x7=前方左角点
0x8=前方中心
0x9=前方右角点
0x10=前轮
0x11=后轮
0x12=内部轮" ;
VAL_ 295 FR_Obj17_MotionStatus 0 "unknown" 1 "moving " 2 "stopped" 3 "stationary" 4 "crossing" 5 "reserve;" ;
VAL_ 295 FR_Obj17_Measured 0 "unknown" 1 "Measured" 2 "Predicted" 3 "Reserved" ;
VAL_ 295 FR_Obj17_valid 0 "" ;
VAL_ 295 FR_Obj17_Type 0 "Not Detected" 1 "car" 2 "truck" 3 "bicycle/motorbike" 4 "pedestrian" 5 "tricycle" 6 "animal" 7 "uncertain" ;
VAL_ 296 FR_Obj18_ReferPoint_Dx 0 "参考点未知
0x1=后方左角点
0x2=后方中心
0x3=后方右角点
0x4=左边中心
0x5=中心
0x6=右边中心
0x7=前方左角点
0x8=前方中心
0x9=前方右角点
0x10=前轮
0x11=后轮
0x12=内部轮" ;
VAL_ 296 FR_Obj18_MotionStatus 0 "unknown" 1 "moving " 2 "stopped" 3 "stationary" 4 "crossing" 5 "reserve;" ;
VAL_ 296 FR_Obj18_Measured 0 "unknown" 1 "Measured" 2 "Predicted" 3 "Reserved" ;
VAL_ 296 FR_Obj18_valid 0 "" ;
VAL_ 296 FR_Obj18_Type 0 "Not Detected" 1 "car" 2 "truck" 3 "bicycle/motorbike" 4 "pedestrian" 5 "tricycle" 6 "animal" 7 "uncertain" ;
VAL_ 297 FR_Obj19_ReferPoint_Dx 0 "参考点未知
0x1=后方左角点
0x2=后方中心
0x3=后方右角点
0x4=左边中心
0x5=中心
0x6=右边中心
0x7=前方左角点
0x8=前方中心
0x9=前方右角点
0x10=前轮
0x11=后轮
0x12=内部轮" ;
VAL_ 297 FR_Obj19_MotionStatus 0 "unknown" 1 "moving " 2 "stopped" 3 "stationary" 4 "crossing" 5 "reserve;" ;
VAL_ 297 FR_Obj19_Measured 0 "unknown" 1 "Measured" 2 "Predicted" 3 "Reserved" ;
VAL_ 297 FR_Obj19_valid 0 "" ;
VAL_ 297 FR_Obj19_Type 0 "Not Detected" 1 "car" 2 "truck" 3 "bicycle/motorbike" 4 "pedestrian" 5 "tricycle" 6 "animal" 7 "uncertain" ;
VAL_ 298 FR_Obj13_ReferPoint_Dx 0 "参考点未知
0x1=后方左角点
0x2=后方中心
0x3=后方右角点
0x4=左边中心
0x5=中心
0x6=右边中心
0x7=前方左角点
0x8=前方中心
0x9=前方右角点
0x10=前轮
0x11=后轮
0x12=内部轮" ;
VAL_ 298 FR_Obj13_MotionStatus 0 "unknown" 1 "moving " 2 "stopped" 3 "stationary" 4 "crossing" 5 "reserve;" ;
VAL_ 298 FR_Obj13_Measured 0 "unknown" 1 "Measured" 2 "Predicted" 3 "Reserved" ;
VAL_ 298 FR_Obj13_valid 0 "" ;
VAL_ 298 FR_Obj13_Type 0 "Not Detected" 1 "car" 2 "truck" 3 "bicycle/motorbike" 4 "pedestrian" 5 "tricycle" 6 "animal" 7 "uncertain" ;
VAL_ 299 FR_Obj20_ReferPoint_Dx 0 "参考点未知
0x1=后方左角点
0x2=后方中心
0x3=后方右角点
0x4=左边中心
0x5=中心
0x6=右边中心
0x7=前方左角点
0x8=前方中心
0x9=前方右角点
0x10=前轮
0x11=后轮
0x12=内部轮" ;
VAL_ 299 FR_Obj20_MotionStatus 0 "unknown" 1 "moving " 2 "stopped" 3 "stationary" 4 "crossing" 5 "reserve;" ;
VAL_ 299 FR_Obj20_Measured 0 "unknown" 1 "Measured" 2 "Predicted" 3 "Reserved" ;
VAL_ 299 FR_Obj20_valid 0 "" ;
VAL_ 299 FR_Obj20_Type 0 "Not Detected" 1 "car" 2 "truck" 3 "bicycle/motorbike" 4 "pedestrian" 5 "tricycle" 6 "animal" 7 "uncertain" ;
VAL_ 300 FR_Obj21_ReferPoint_Dx 0 "参考点未知
0x1=后方左角点
0x2=后方中心
0x3=后方右角点
0x4=左边中心
0x5=中心
0x6=右边中心
0x7=前方左角点
0x8=前方中心
0x9=前方右角点
0x10=前轮
0x11=后轮
0x12=内部轮" ;
VAL_ 300 FR_Obj21_MotionStatus 0 "unknown" 1 "moving " 2 "stopped" 3 "stationary" 4 "crossing" 5 "reserve;" ;
VAL_ 300 FR_Obj21_Measured 0 "unknown" 1 "Measured" 2 "Predicted" 3 "Reserved" ;
VAL_ 300 FR_Obj21_valid 0 "" ;
VAL_ 300 FR_Obj21_Type 0 "Not Detected" 1 "car" 2 "truck" 3 "bicycle/motorbike" 4 "pedestrian" 5 "tricycle" 6 "animal" 7 "uncertain" ;
VAL_ 301 FR_Obj22_ReferPoint_Dx 0 "参考点未知
0x1=后方左角点
0x2=后方中心
0x3=后方右角点
0x4=左边中心
0x5=中心
0x6=右边中心
0x7=前方左角点
0x8=前方中心
0x9=前方右角点
0x10=前轮
0x11=后轮
0x12=内部轮" ;
VAL_ 301 FR_Obj22_MotionStatus 0 "unknown" 1 "moving " 2 "stopped" 3 "stationary" 4 "crossing" 5 "reserve;" ;
VAL_ 301 FR_Obj22_Measured 0 "unknown" 1 "Measured" 2 "Predicted" 3 "Reserved" ;
VAL_ 301 FR_Obj22_valid 0 "" ;
VAL_ 301 FR_Obj22_Type 0 "Not Detected" 1 "car" 2 "truck" 3 "bicycle/motorbike" 4 "pedestrian" 5 "tricycle" 6 "animal" 7 "uncertain" ;
VAL_ 302 FR_Obj23_ReferPoint_Dx 0 "参考点未知
0x1=后方左角点
0x2=后方中心
0x3=后方右角点
0x4=左边中心
0x5=中心
0x6=右边中心
0x7=前方左角点
0x8=前方中心
0x9=前方右角点
0x10=前轮
0x11=后轮
0x12=内部轮" ;
VAL_ 302 FR_Obj23_MotionStatus 0 "unknown" 1 "moving " 2 "stopped" 3 "stationary" 4 "crossing" 5 "reserve;" ;
VAL_ 302 FR_Obj23_Measured 0 "unknown" 1 "Measured" 2 "Predicted" 3 "Reserved" ;
VAL_ 302 FR_Obj23_valid 0 "" ;
VAL_ 302 FR_Obj23_Type 0 "Not Detected" 1 "car" 2 "truck" 3 "bicycle/motorbike" 4 "pedestrian" 5 "tricycle" 6 "animal" 7 "uncertain" ;
VAL_ 303 FR_Obj24_ReferPoint_Dx 0 "参考点未知
0x1=后方左角点
0x2=后方中心
0x3=后方右角点
0x4=左边中心
0x5=中心
0x6=右边中心
0x7=前方左角点
0x8=前方中心
0x9=前方右角点
0x10=前轮
0x11=后轮
0x12=内部轮" ;
VAL_ 303 FR_Obj24_MotionStatus 0 "unknown" 1 "moving " 2 "stopped" 3 "stationary" 4 "crossing" 5 "reserve;" ;
VAL_ 303 FR_Obj24_Measured 0 "unknown" 1 "Measured" 2 "Predicted" 3 "Reserved" ;
VAL_ 303 FR_Obj24_valid 0 "" ;
VAL_ 303 FR_Obj24_Type 0 "Not Detected" 1 "car" 2 "truck" 3 "bicycle/motorbike" 4 "pedestrian" 5 "tricycle" 6 "animal" 7 "uncertain" ;
VAL_ 338 ADC_SenceMode 0 "unkown
0x1=地库模式
0x2=非地库模式
0x3=Reserved" ;
VAL_ 338 AD_Reqmode 1 "  Parking running" 2 "Auto Driving" 3 "Reserved" ;
VAL_ 349 ESP_Calibrated 0 "Calibrated" 1 " Not Calibrated" ;
VAL_ 349 ESP_YawRateValid 0 " Initializing" 1 " Valid" 2 " Invalid" 3 " Reserved" ;
VAL_ 349 ESP_LongAccelValid 0 "Initializing" 1 "Valid" 2 "Invalid" 3 "Reserved" ;
VAL_ 349 ESP_LatAccelValid 0 "Initializing" 1 "Valid" 2 "Invalid" 3 "Reserved" ;
VAL_ 377 ADC_SYNC_Sync_Time 0 "0x20=SYNC. SyncTimeSec = 32bit LSB of the 48 bits Seconds part of the time
 
Type=0x28=FUP.SyncTimeNSec = 32 bit time stamp in nanoseconds" ;
VAL_ 377 ADC_SYNC_UserByte_OVS_SGW 0 "0x20=SYNC.用户自定义数据，默认为0.

Type=0x28=FUP.
bit1-bit0=OVS(Overflow of seconds)
bit2=SGW
bit7-bit3=reserved。" ;
VAL_ 377 ADC_SYNC_Type 32 "SYNC
0x28=FUP" ;
VAL_ 384 EpsSteerAgSensFilr 0 "Valid" 1 "Invalid" ;
VAL_ 384 EpsSasCalSts 0 "Calibrated" 1 "Not Calibrated" ;
VAL_ 384 EpsSasSteerAgVld 0 "Valid" 1 "Invalid" ;
VAL_ 433 VcuAccrPedlPosnVld 0 "Valid" 1 "Invalid" ;
VAL_ 433 VcuRdySts 0 "no Ready" 1 "Ready" ;
VAL_ 433 VcuVehGearPosnVld 0 "Valid" 1 "Invalid" ;
VAL_ 433 VcuGearPosn 0 "Invalid" 1 "P" 2 "R" 3 "N" 4 "D" 5 "reserved" ;
VAL_ 450 WhlSpdRiReDir 0 "Forward" 1 "backward" 2 "Standstill" 3 "Invalid" ;
VAL_ 450 WhlSpdRiReDataVld 0 "Valid" 1 "Invalid" ;
VAL_ 450 WhlSpdLeReDir 0 "Forward" 1 "backward" 2 "Standstill" 3 "Invalid" ;
VAL_ 450 WhlSpdLeReDataVld 0 "Valid" 1 "Invalid" ;
VAL_ 450 WhlSpdRiFrntDir 0 "Forward" 1 "backward" 2 "Standstill" 3 "Invalid" ;
VAL_ 450 WhlSpdRiFrntDataVld 0 "Valid" 1 "Invalid" ;
VAL_ 450 WhlSpdLeFrntDir 0 "Forward" 1 "backward" 2 "Standstill" 3 "Invalid" ;
VAL_ 450 WhlSpdLeFrntDataVld 0 "Valid" 1 "Invalid" ;
VAL_ 450 EspVehStandstill 0 "Not standstill" 1 "standstill" ;
VAL_ 450 EspVehSpdVld 0 "Valid" 1 "Invalid" ;
